VERSION ""

NS_ :

BS_:

BU_: CH DIPF DIPR ETH FC HVI HVS PARTY SDCV VEH VIRT

BO_ 1373 VCLEFT_alertLog: 8 VEH
 SG_ VCLEFT_a166_AUTO_DOWN_HELD m166 : 62|1@1+ (1,0) [0|1] ""  gtw
 SG_ VCLEFT_a150_pinchV3InUse m150 : 61|1@1+ (1,0) [0|1] ""  gtw
 SG_ VCLEFT_a151_pinchV3InUse m151 : 61|1@1+ (1,0) [0|1] ""  gtw
 SG_ VCLEFT_a166_SOFT_STOP_OVERRIDE m166 : 61|1@1+ (1,0) [0|1] ""  gtw
 SG_ VCLEFT_a166_CAL_CLEAR_ENC_LOSS m166 : 60|1@1+ (1,0) [0|1] ""  gtw
 SG_ VCLEFT_a321_railVoltage m321 : 59|5@1+ (0.5,0) [0|16] "V"  gtw
 SG_ VCLEFT_a320_railVoltage m320 : 59|5@1+ (0.5,0) [0|16] "V"  gtw
 SG_ VCLEFT_a323_railVoltage m323 : 59|5@1+ (0.5,0) [0|16] "V"  gtw
 SG_ VCLEFT_a166_SHORT_DROP_FAILED m166 : 59|1@1+ (1,0) [0|1] ""  gtw
 SG_ VCLEFT_a322_railVoltage m322 : 59|5@1+ (0.5,0) [0|16] "V"  gtw
 SG_ VCLEFT_a166_PINCH_TABLE_REJECTED m166 : 58|1@1+ (1,0) [0|1] ""  gtw
 SG_ VCLEFT_a166_INT_SWITCH_IGNORED m166 : 57|1@1+ (1,0) [0|1] ""  gtw
 SG_ VCLEFT_a042_UsageNVMMTask m42 : 56|8@1+ (1,0) [0|255] ""  gtw
 SG_ VCLEFT_a166_REAR_SWITCH_IGNORED m166 : 56|1@1+ (1,0) [0|1] ""  gtw
 SG_ VCLEFT_a041_CPULoadNVMMTask m41 : 56|8@1+ (1,0) [0|255] ""  gtw
 SG_ VCLEFT_a022_TaskInitError4 m22 : 56|8@1+ (1,0) [0|255] ""  gtw
 SG_ VCLEFT_a200_phantomTicks m200 : 53|11@1- (1,0) [-1024|1023] "ticks"  gtw
 SG_ VCLEFT_a265_seatMotorState m265 : 52|3@1+ (1,0) [0|5] ""  gtw
 SG_ VCLEFT_a237_lumbarBState m237 : 52|3@1+ (1,0) [0|5] ""  gtw
 SG_ VCLEFT_a269_seatMotorState m269 : 52|3@1+ (1,0) [0|5] ""  gtw
 SG_ VCLEFT_a270_seatMotorState m270 : 52|3@1+ (1,0) [0|5] ""  gtw
 SG_ VCLEFT_a266_seatMotorState m266 : 52|3@1+ (1,0) [0|5] ""  gtw
 SG_ VCLEFT_a263_seatMotorState m263 : 52|3@1+ (1,0) [0|5] ""  gtw
 SG_ VCLEFT_a180_latchClawStatus m180 : 52|1@1+ (1,0) [0|1] ""  gtw
 SG_ VCLEFT_a238_lumbarBState m238 : 52|3@1+ (1,0) [0|5] ""  gtw
 SG_ VCLEFT_a218_motorDutyCycle m218 : 52|10@1+ (0.1,0) [0|100] "A"  gtw
 SG_ VCLEFT_a267_seatMotorState m267 : 52|3@1+ (1,0) [0|5] ""  gtw
 SG_ VCLEFT_a181_latchClawStatus m181 : 52|1@1+ (1,0) [0|1] ""  gtw
 SG_ VCLEFT_a236_lumbarBState m236 : 52|3@1+ (1,0) [0|5] ""  gtw
 SG_ VCLEFT_a264_seatMotorState m264 : 52|3@1+ (1,0) [0|5] ""  gtw
 SG_ VCLEFT_a268_seatMotorState m268 : 52|3@1+ (1,0) [0|5] ""  gtw
 SG_ VCLEFT_a166_pinchV2PctAboveExp m166 : 51|5@1+ (1,0) [0|31] ""  gtw
 SG_ VCLEFT_a151_powerDeriv2Accum m151 : 51|10@1+ (1000,0) [0|1023000] "ticks"  gtw
 SG_ VCLEFT_a150_powerDeriv2Accum m150 : 51|10@1+ (1000,0) [0|1023000] "ticks"  gtw
 SG_ VCLEFT_a223_seatSwitchForward m223 : 50|2@1+ (1,0) [0|3] ""  gtw
 SG_ VCLEFT_a322_powerDerivAccum m322 : 50|9@1+ (100,0) [0|51100] "-"  gtw
 SG_ VCLEFT_a323_powerDeriv2Accum m323 : 50|9@1+ (2000,0) [0|1022000] "-"  gtw
 SG_ VCLEFT_a220_seatSwitchForward m220 : 50|2@1+ (1,0) [0|3] ""  gtw
 SG_ VCLEFT_a320_powerDerivAccum m320 : 50|9@1+ (100,0) [0|51100] "-"  gtw
 SG_ VCLEFT_a221_seatSwitchForward m221 : 50|2@1+ (1,0) [0|3] ""  gtw
 SG_ VCLEFT_a231_seatSwitchForward m231 : 50|2@1+ (1,0) [0|3] ""  gtw
 SG_ VCLEFT_a228_seatSwitchForward m228 : 50|2@1+ (1,0) [0|3] ""  gtw
 SG_ VCLEFT_a222_seatSwitchForward m222 : 50|2@1+ (1,0) [0|3] ""  gtw
 SG_ VCLEFT_a321_powerDeriv2Accum m321 : 50|9@1+ (2000,0) [0|1022000] "-"  gtw
 SG_ VCLEFT_a230_seatSwitchForward m230 : 50|2@1+ (1,0) [0|3] ""  gtw
 SG_ VCLEFT_a229_seatSwitchForward m229 : 50|2@1+ (1,0) [0|3] ""  gtw
 SG_ VCLEFT_a238_lumbarAState m238 : 49|3@1+ (1,0) [0|5] ""  gtw
 SG_ VCLEFT_a237_lumbarAState m237 : 49|3@1+ (1,0) [0|5] ""  gtw
 SG_ VCLEFT_a236_lumbarAState m236 : 49|3@1+ (1,0) [0|5] ""  gtw
 SG_ VCLEFT_a181_latchStatus m181 : 48|4@1+ (1,0) [0|8] ""  gtw
 SG_ VCLEFT_a223_seatSwitchBack m223 : 48|2@1+ (1,0) [0|3] ""  gtw
 SG_ VCLEFT_a237_lumbarDiagStatus m237 : 48|1@1+ (1,0) [0|1] ""  gtw
 SG_ VCLEFT_a041_CPULoad1000msTask m41 : 48|8@1+ (1,0) [0|255] ""  gtw
 SG_ VCLEFT_a180_latchStatus m180 : 48|4@1+ (1,0) [0|8] ""  gtw
 SG_ VCLEFT_a231_seatSwitchBack m231 : 48|2@1+ (1,0) [0|3] ""  gtw
 SG_ VCLEFT_a228_seatSwitchBack m228 : 48|2@1+ (1,0) [0|3] ""  gtw
 SG_ VCLEFT_a222_seatSwitchBack m222 : 48|2@1+ (1,0) [0|3] ""  gtw
 SG_ VCLEFT_a238_lumbarDiagStatus m238 : 48|1@1+ (1,0) [0|1] ""  gtw
 SG_ VCLEFT_a221_seatSwitchBack m221 : 48|2@1+ (1,0) [0|3] ""  gtw
 SG_ VCLEFT_a042_UsageUDSTask m42 : 48|8@1+ (1,0) [0|255] ""  gtw
 SG_ VCLEFT_a022_TaskInitError3 m22 : 48|8@1+ (1,0) [0|255] ""  gtw
 SG_ VCLEFT_a216_byte3 m216 : 48|8@1+ (1,0) [0|255] ""  gtw
 SG_ VCLEFT_a168_pinchV3InUse m168 : 48|1@1+ (1,0) [0|1] ""  gtw
 SG_ VCLEFT_a220_seatSwitchBack m220 : 48|2@1+ (1,0) [0|3] ""  gtw
 SG_ VCLEFT_a164_calibratedVoltage m164 : 48|6@1+ (0.25,0) [0|16] "V"  gtw
 SG_ VCLEFT_a167_pinchV3InUse m167 : 48|1@1+ (1,0) [0|1] ""  gtw
 SG_ VCLEFT_a236_lumbarDiagStatus m236 : 48|1@1+ (1,0) [0|1] ""  gtw
 SG_ VCLEFT_a229_seatSwitchBack m229 : 48|2@1+ (1,0) [0|3] ""  gtw
 SG_ VCLEFT_a230_seatSwitchBack m230 : 48|2@1+ (1,0) [0|3] ""  gtw
 SG_ VCLEFT_a003_Data m3 : 48|16@1+ (1,0) [0|65535] ""  gtw
 SG_ VCLEFT_a000_alertDataW2 m0 : 48|16@1+ (1,0) [0|65535] ""  X
 SG_ VCLEFT_a200_motorPosition m200 : 46|7@1+ (20,0) [0|2540] "ticks"  gtw
 SG_ VCLEFT_a235_seatSwitchForward m235 : 45|2@1+ (1,0) [0|3] ""  gtw
 SG_ VCLEFT_a253_seatSwitchForward m253 : 45|2@1+ (1,0) [0|3] ""  gtw
 SG_ VCLEFT_a252_seatSwitchForward m252 : 45|2@1+ (1,0) [0|3] ""  gtw
 SG_ VCLEFT_a234_seatSwitchForward m234 : 45|2@1+ (1,0) [0|3] ""  gtw
 SG_ VCLEFT_a233_seatSwitchForward m233 : 45|2@1+ (1,0) [0|3] ""  gtw
 SG_ VCLEFT_a200_encoder8vEn m200 : 45|1@1+ (1,0) [0|1] ""  gtw
 SG_ VCLEFT_a232_seatSwitchForward m232 : 45|2@1+ (1,0) [0|3] ""  gtw
 SG_ VCLEFT_a254_seatSwitchForward m254 : 45|2@1+ (1,0) [0|3] ""  gtw
 SG_ VCLEFT_a251_seatSwitchForward m251 : 45|2@1+ (1,0) [0|3] ""  gtw
 SG_ VCLEFT_a221_seatMotorState m221 : 44|3@1+ (1,0) [0|5] ""  gtw
 SG_ VCLEFT_a231_seatMotorState m231 : 44|3@1+ (1,0) [0|5] ""  gtw
 SG_ VCLEFT_a228_seatMotorState m228 : 44|3@1+ (1,0) [0|5] ""  gtw
 SG_ VCLEFT_a222_seatMotorState m222 : 44|3@1+ (1,0) [0|5] ""  gtw
 SG_ VCLEFT_a229_seatMotorState m229 : 44|3@1+ (1,0) [0|5] ""  gtw
 SG_ VCLEFT_a230_seatMotorState m230 : 44|3@1+ (1,0) [0|5] ""  gtw
 SG_ VCLEFT_a223_seatMotorState m223 : 44|3@1+ (1,0) [0|5] ""  gtw
 SG_ VCLEFT_a220_seatMotorState m220 : 44|3@1+ (1,0) [0|5] ""  gtw
 SG_ VCLEFT_a166_sealPos m166 : 43|8@1+ (1,0) [0|255] ""  gtw
 SG_ VCLEFT_a251_seatSwitchBack m251 : 43|2@1+ (1,0) [0|3] ""  gtw
 SG_ VCLEFT_a234_seatSwitchBack m234 : 43|2@1+ (1,0) [0|3] ""  gtw
 SG_ VCLEFT_a252_seatSwitchBack m252 : 43|2@1+ (1,0) [0|3] ""  gtw
 SG_ VCLEFT_a235_seatSwitchBack m235 : 43|2@1+ (1,0) [0|3] ""  gtw
 SG_ VCLEFT_a253_seatSwitchBack m253 : 43|2@1+ (1,0) [0|3] ""  gtw
 SG_ VCLEFT_a063_faulted m63 : 43|1@1+ (1,0) [0|1] ""  gtw
 SG_ VCLEFT_a232_seatSwitchBack m232 : 43|2@1+ (1,0) [0|3] ""  gtw
 SG_ VCLEFT_a254_seatSwitchBack m254 : 43|2@1+ (1,0) [0|3] ""  gtw
 SG_ VCLEFT_a233_seatSwitchBack m233 : 43|2@1+ (1,0) [0|3] ""  gtw
 SG_ VCLEFT_a218_motorCurrent m218 : 42|10@1- (0.04,0.0) [-20|20] "A"  gtw
 SG_ VCLEFT_a129_VGS_LC m129 : 42|1@1+ (1,0) [0|1] ""  gtw
 SG_ VCLEFT_a063_stuckActive m63 : 42|1@1+ (1,0) [0|1] ""  gtw
 SG_ VCLEFT_a323_peakTimeMs m323 : 41|9@1+ (2,0) [0|1022] "ms"  gtw
 SG_ VCLEFT_a150_powerDerivAccum m150 : 41|10@1+ (100,0) [0|102300] "ticks"  gtw
 SG_ VCLEFT_a129_VGS_HC m129 : 41|1@1+ (1,0) [0|1] ""  gtw
 SG_ VCLEFT_a151_powerDerivAccum m151 : 41|10@1+ (100,0) [0|102300] "ticks"  gtw
 SG_ VCLEFT_a320_peakTimeMs m320 : 41|9@1+ (2,0) [0|1022] "ms"  gtw
 SG_ VCLEFT_a321_peakTimeMs m321 : 41|9@1+ (2,0) [0|1022] "ms"  gtw
 SG_ VCLEFT_a322_peakTimeMs m322 : 41|9@1+ (2,0) [0|1022] "ms"  gtw
 SG_ VCLEFT_a063_indeterminate m63 : 41|1@1+ (1,0) [0|1] ""  gtw
 SG_ VCLEFT_a129_VGS_LB m129 : 40|1@1+ (1,0) [0|1] ""  gtw
 SG_ VCLEFT_a042_Usage1000msTask m42 : 40|8@1+ (1,0) [0|255] ""  gtw
 SG_ VCLEFT_a266_seatMotorPosReal m266 : 40|12@1- (1,0) [-2048|2047] "mm"  gtw
 SG_ VCLEFT_a254_seatMotorState m254 : 40|3@1+ (1,0) [0|5] ""  gtw
 SG_ VCLEFT_a232_seatMotorState m232 : 40|3@1+ (1,0) [0|5] ""  gtw
 SG_ VCLEFT_a265_seatMotorPosReal m265 : 40|12@1- (1,0) [-2048|2047] "mm"  gtw
 SG_ VCLEFT_a242_seatHeatTmpTarget m242 : 40|8@1- (0.5,0) [0|60] "degC"  gtw
 SG_ VCLEFT_a208_unitStatusEPBM m208 : 40|5@1+ (1,0) [0|21] ""  gtw
 SG_ VCLEFT_a234_seatMotorState m234 : 40|3@1+ (1,0) [0|5] ""  gtw
 SG_ VCLEFT_a252_seatMotorState m252 : 40|3@1+ (1,0) [0|5] ""  gtw
 SG_ VCLEFT_a207_unitStatusEPBM m207 : 40|5@1+ (1,0) [0|21] ""  gtw
 SG_ VCLEFT_a043_CallTrace1 m43 : 40|24@1+ (1,0) [0|16777215] ""  gtw
 SG_ VCLEFT_a046_CallTrace1 m46 : 40|24@1+ (1,0) [0|16777215] ""  gtw
 SG_ VCLEFT_a045_CallTrace1 m45 : 40|24@1+ (1,0) [0|16777215] ""  gtw
 SG_ VCLEFT_a181_releasePWM m181 : 40|8@1+ (1,0) [0|255] "%"  gtw
 SG_ VCLEFT_a270_seatMotorPosReal m270 : 40|12@1- (1,0) [-2048|2047] "mm"  gtw
 SG_ VCLEFT_a269_seatMotorPosReal m269 : 40|12@1- (1,0) [-2048|2047] "mm"  gtw
 SG_ VCLEFT_a264_seatMotorPosReal m264 : 40|12@1- (1,0) [-2048|2047] "mm"  gtw
 SG_ VCLEFT_a164_downMovementTimeMs m164 : 40|7@1+ (50,0) [0|6350] "ms"  gtw
 SG_ VCLEFT_a217_byte7 m217 : 40|8@1+ (1,0) [0|255] ""  gtw
 SG_ VCLEFT_a263_seatMotorPosReal m263 : 40|12@1- (1,0) [-2048|2047] "mm"  gtw
 SG_ VCLEFT_a251_seatMotorState m251 : 40|3@1+ (1,0) [0|5] ""  gtw
 SG_ VCLEFT_a063_disconnected m63 : 40|1@1+ (1,0) [0|1] ""  gtw
 SG_ VCLEFT_a206_unitStatusEPBM m206 : 40|5@1+ (1,0) [0|21] ""  gtw
 SG_ VCLEFT_a165_lowerEndStopPosition m165 : 40|8@1+ (10,0) [0|2550] "ticks"  gtw
 SG_ VCLEFT_a041_CPULoad100msTask m41 : 40|8@1+ (1,0) [0|255] ""  gtw
 SG_ VCLEFT_a044_CallTrace1 m44 : 40|24@1+ (1,0) [0|16777215] ""  gtw
 SG_ VCLEFT_a268_seatMotorPosReal m268 : 40|12@1- (1,0) [-2048|2047] "mm"  gtw
 SG_ VCLEFT_a180_releasePWM m180 : 40|8@1+ (1,0) [0|255] "%"  gtw
 SG_ VCLEFT_a216_byte2 m216 : 40|8@1+ (1,0) [0|255] ""  gtw
 SG_ VCLEFT_a233_seatMotorState m233 : 40|3@1+ (1,0) [0|5] ""  gtw
 SG_ VCLEFT_a022_TaskInitError2 m22 : 40|8@1+ (1,0) [0|255] ""  gtw
 SG_ VCLEFT_a059_current m59 : 40|12@1+ (0.05,0) [0|204.75] "A"  gtw
 SG_ VCLEFT_a267_seatMotorPosReal m267 : 40|12@1- (1,0) [-2048|2047] "mm"  gtw
 SG_ VCLEFT_a210_unitStatusEPBM m210 : 40|5@1+ (1,0) [0|21] ""  gtw
 SG_ VCLEFT_a239_seatHeatTmpTarget m239 : 40|8@1- (0.5,0) [0|60] "degC"  gtw
 SG_ VCLEFT_a253_seatMotorState m253 : 40|3@1+ (1,0) [0|5] ""  gtw
 SG_ VCLEFT_a235_seatMotorState m235 : 40|3@1+ (1,0) [0|5] ""  gtw
 SG_ VCLEFT_a209_unitStatusEPBM m209 : 40|5@1+ (1,0) [0|21] ""  gtw
 SG_ VCLEFT_a200_encoderVoltage m200 : 39|6@1+ (0.15,0) [0|9] "V"  gtw
 SG_ VCLEFT_a129_VGS_HB m129 : 39|1@1+ (1,0) [0|1] ""  gtw
 SG_ VCLEFT_a205_current m205 : 38|10@1+ (0.2,0) [0|204.6] "A"  gtw
 SG_ VCLEFT_a213_current m213 : 38|10@1+ (0.2,0) [0|204.6] "A"  gtw
 SG_ VCLEFT_a204_current m204 : 38|10@1+ (0.2,0) [0|204.6] "A"  gtw
 SG_ VCLEFT_a129_VGS_LA m129 : 38|1@1+ (1,0) [0|1] ""  gtw
 SG_ VCLEFT_a203_current m203 : 38|10@1+ (0.2,0) [0|204.6] "A"  gtw
 SG_ VCLEFT_a211_current m211 : 38|10@1+ (0.2,0) [0|204.6] "A"  gtw
 SG_ VCLEFT_a214_current m214 : 38|10@1+ (0.2,0) [0|204.6] "A"  gtw
 SG_ VCLEFT_a202_current m202 : 38|10@1+ (0.2,0) [0|204.6] "A"  gtw
 SG_ VCLEFT_a168_powerDeriv2Accum m168 : 38|10@1+ (1000,0) [0|1023000] "ticks"  gtw
 SG_ VCLEFT_a212_current m212 : 38|10@1+ (0.2,0) [0|204.6] "A"  gtw
 SG_ VCLEFT_a167_powerDeriv2Accum m167 : 38|10@1+ (1000,0) [0|1023000] "ticks"  gtw
 SG_ VCLEFT_a129_VGS_HA m129 : 37|1@1+ (1,0) [0|1] ""  gtw
 SG_ VCLEFT_a129_VCPH_OVLO_ABS m129 : 36|1@1+ (1,0) [0|1] ""  gtw
 SG_ VCLEFT_a150_pinchVoltage m150 : 35|6@1+ (0.25,0) [0|16] "V"  gtw
 SG_ VCLEFT_a129_VCPH_UVLO m129 : 35|1@1+ (1,0) [0|1] ""  gtw
 SG_ VCLEFT_a151_pinchVoltage m151 : 35|6@1+ (0.25,0) [0|16] "V"  gtw
 SG_ VCLEFT_a320_movementTimeMs m320 : 34|7@1+ (50,0) [0|6350] "ms"  gtw
 SG_ VCLEFT_a226_seatSwitchForward m226 : 34|2@1+ (1,0) [0|3] ""  gtw
 SG_ VCLEFT_a227_seatSwitchForward m227 : 34|2@1+ (1,0) [0|3] ""  gtw
 SG_ VCLEFT_a321_movementTimeMs m321 : 34|7@1+ (50,0) [0|6350] "ms"  gtw
 SG_ VCLEFT_a322_movementTimeMs m322 : 34|7@1+ (50,0) [0|6350] "ms"  gtw
 SG_ VCLEFT_a224_seatSwitchForward m224 : 34|2@1+ (1,0) [0|3] ""  gtw
 SG_ VCLEFT_a225_seatSwitchForward m225 : 34|2@1+ (1,0) [0|3] ""  gtw
 SG_ VCLEFT_a129_VCPH_UVLO2 m129 : 34|1@1+ (1,0) [0|1] ""  gtw
 SG_ VCLEFT_a323_movementTimeMs m323 : 34|7@1+ (50,0) [0|6350] "ms"  gtw
 SG_ VCLEFT_a302_CBC_UARTReset m302 : 33|1@1+ (1,0) [0|1] ""  gtw
 SG_ VCLEFT_a129_VCP_LSD_UVLO2 m129 : 33|1@1+ (1,0) [0|1] ""  gtw
 SG_ VCLEFT_a219_dropoutCount m219 : 32|12@1+ (1,0) [0|4095] ""  gtw
 SG_ VCLEFT_a231_seatMotorPosReal m231 : 32|12@1- (1,0) [-2048|2047] "mm"  gtw
 SG_ VCLEFT_a228_seatMotorPosReal m228 : 32|12@1- (1,0) [-2048|2047] "mm"  gtw
 SG_ VCLEFT_a022_TaskInitError1 m22 : 32|8@1+ (1,0) [0|255] ""  gtw
 SG_ VCLEFT_a210_unitStatusEPB m210 : 32|5@1+ (1,0) [0|21] ""  gtw
 SG_ VCLEFT_a224_seatSwitchBack m224 : 32|2@1+ (1,0) [0|3] ""  gtw
 SG_ VCLEFT_a209_unitStatusEPB m209 : 32|5@1+ (1,0) [0|21] ""  gtw
 SG_ VCLEFT_a167_pinchVoltage m167 : 32|6@1+ (0.25,0) [0|16] "V"  gtw
 SG_ VCLEFT_a180_extHandlePulled m180 : 32|1@1+ (1,0) [0|1] ""  gtw
 SG_ VCLEFT_a164_upMovementTimeMs m164 : 32|7@1+ (50,0) [0|6350] "ms"  gtw
 SG_ VCLEFT_a216_byte1 m216 : 32|8@1+ (1,0) [0|255] ""  gtw
 SG_ VCLEFT_a151_windowPinchReason m151 : 32|3@1+ (1,0) [0|4] ""  gtw
 SG_ VCLEFT_a302_CBC_MIA m302 : 32|1@1+ (1,0) [0|1] ""  gtw
 SG_ VCLEFT_a206_unitStatusEPB m206 : 32|5@1+ (1,0) [0|21] ""  gtw
 SG_ VCLEFT_a212_desyncCount m212 : 32|6@1+ (1,0) [0|63] ""  gtw
 SG_ VCLEFT_a236_lumbarBPressureHpa m236 : 32|16@1+ (1,0) [0|65535] ""  gtw
 SG_ VCLEFT_a222_seatMotorPosReal m222 : 32|12@1- (1,0) [-2048|2047] "mm"  gtw
 SG_ VCLEFT_a208_unitStatusEPB m208 : 32|5@1+ (1,0) [0|21] ""  gtw
 SG_ VCLEFT_a276_mirrorTiltYPosition m276 : 32|8@1+ (0.02,0) [0|5] "V"  gtw
 SG_ VCLEFT_a041_CPULoad10msTask m41 : 32|8@1+ (1,0) [0|255] ""  gtw
 SG_ VCLEFT_a181_extHandlePulled m181 : 32|1@1+ (1,0) [0|1] ""  gtw
 SG_ VCLEFT_a221_seatMotorPosReal m221 : 32|12@1- (1,0) [-2048|2047] "mm"  gtw
 SG_ VCLEFT_a129_AVDD_UVLO m129 : 32|1@1+ (1,0) [0|1] ""  gtw
 SG_ VCLEFT_a214_desyncCount m214 : 32|6@1+ (1,0) [0|63] ""  gtw
 SG_ VCLEFT_a227_seatSwitchBack m227 : 32|2@1+ (1,0) [0|3] ""  gtw
 SG_ VCLEFT_a213_desyncCount m213 : 32|6@1+ (1,0) [0|63] ""  gtw
 SG_ VCLEFT_a260_temperature m260 : 32|8@1+ (0.5,-40) [-40|80] "degC"  gtw
 SG_ VCLEFT_a000_alertDataW1 m0 : 32|16@1+ (1,0) [0|65535] ""  X
 SG_ VCLEFT_a217_byte6 m217 : 32|8@1+ (1,0) [0|255] ""  gtw
 SG_ VCLEFT_a165_sealZoneStartPos m165 : 32|8@1+ (1,0) [0|255] ""  gtw
 SG_ VCLEFT_a287_encoderVoltage m287 : 32|6@1+ (0.15,0) [0|9] "V"  gtw
 SG_ VCLEFT_a220_seatMotorPosReal m220 : 32|12@1- (1,0) [-2048|2047] "mm"  gtw
 SG_ VCLEFT_a003_LineNumber m3 : 32|16@1+ (1,0) [0|65535] ""  gtw
 SG_ VCLEFT_a244_seatHeatTmpTarget m244 : 32|8@1- (0.5,0) [0|60] "degC"  gtw
 SG_ VCLEFT_a063_ADCVoltage m63 : 32|8@1+ (0.025,0) [0|6.375] "V"  gtw
 SG_ VCLEFT_a166_powerSealPos m166 : 32|11@1+ (1,0) [0|2047] ""  gtw
 SG_ VCLEFT_a168_pinchVoltage m168 : 32|6@1+ (0.25,0) [0|16] "V"  gtw
 SG_ VCLEFT_a042_Usage100msTask m42 : 32|8@1+ (1,0) [0|255] ""  gtw
 SG_ VCLEFT_a218_voltage m218 : 32|10@1+ (0.02,0) [0|19] "V"  gtw
 SG_ VCLEFT_a241_seatHeatTmpTarget m241 : 32|8@1- (0.5,0) [0|60] "degC"  gtw
 SG_ VCLEFT_a203_desyncCount m203 : 32|6@1+ (1,0) [0|63] ""  gtw
 SG_ VCLEFT_a226_seatSwitchBack m226 : 32|2@1+ (1,0) [0|3] ""  gtw
 SG_ VCLEFT_a211_desyncCount m211 : 32|6@1+ (1,0) [0|63] ""  gtw
 SG_ VCLEFT_a230_seatMotorPosReal m230 : 32|12@1- (1,0) [-2048|2047] "mm"  gtw
 SG_ VCLEFT_a229_seatMotorPosReal m229 : 32|12@1- (1,0) [-2048|2047] "mm"  gtw
 SG_ VCLEFT_a225_seatSwitchBack m225 : 32|2@1+ (1,0) [0|3] ""  gtw
 SG_ VCLEFT_a286_encoderVoltage m286 : 32|6@1+ (0.15,0) [0|9] "V"  gtw
 SG_ VCLEFT_a259_temperature m259 : 32|8@1+ (0.5,-40) [-40|80] "degC"  gtw
 SG_ VCLEFT_a238_lumbarBPressureHpa m238 : 32|16@1+ (1,0) [0|65535] ""  gtw
 SG_ VCLEFT_a205_desyncCount m205 : 32|6@1+ (1,0) [0|63] ""  gtw
 SG_ VCLEFT_a237_lumbarBPressureHpa m237 : 32|16@1+ (1,0) [0|65535] ""  gtw
 SG_ VCLEFT_a202_desyncCount m202 : 32|6@1+ (1,0) [0|63] ""  gtw
 SG_ VCLEFT_a223_seatMotorPosReal m223 : 32|12@1- (1,0) [-2048|2047] "mm"  gtw
 SG_ VCLEFT_a207_unitStatusEPB m207 : 32|5@1+ (1,0) [0|21] ""  gtw
 SG_ VCLEFT_a150_windowPinchReason m150 : 32|3@1+ (1,0) [0|4] ""  gtw
 SG_ VCLEFT_a204_desyncCount m204 : 32|6@1+ (1,0) [0|63] ""  gtw
 SG_ VCLEFT_a129_VREG_UV m129 : 31|1@1+ (1,0) [0|1] ""  gtw
 SG_ VCLEFT_a302_overCurrentLatch m302 : 31|1@1+ (1,0) [0|1] ""  gtw
 SG_ VCLEFT_a166_STATE_TIMEOUT m166 : 31|1@1+ (1,0) [0|1] ""  gtw
 SG_ VCLEFT_a302_DRV_MIA m302 : 30|1@1+ (1,0) [0|1] ""  gtw
 SG_ VCLEFT_a166_PINCH_DEBUG m166 : 30|1@1+ (1,0) [0|1] ""  gtw
 SG_ VCLEFT_a129_OTSD m129 : 30|1@1+ (1,0) [0|1] ""  gtw
 SG_ VCLEFT_a130_OTW m130 : 29|1@1+ (1,0) [0|1] ""  gtw
 SG_ VCLEFT_a226_seatMotorState m226 : 29|3@1+ (1,0) [0|5] ""  gtw
 SG_ VCLEFT_a129_WD_FAULT m129 : 29|1@1+ (1,0) [0|1] ""  gtw
 SG_ VCLEFT_a227_seatMotorState m227 : 29|3@1+ (1,0) [0|5] ""  gtw
 SG_ VCLEFT_a224_seatMotorState m224 : 29|3@1+ (1,0) [0|5] ""  gtw
 SG_ VCLEFT_a225_seatMotorState m225 : 29|3@1+ (1,0) [0|5] ""  gtw
 SG_ VCLEFT_a302_motorDisconnect m302 : 29|1@1+ (1,0) [0|1] ""  gtw
 SG_ VCLEFT_a166_PINCH_V1 m166 : 29|1@1+ (1,0) [0|1] ""  gtw
 SG_ VCLEFT_a267_seatMotorDCurrent m267 : 28|12@1- (0.01,0) [-20.48|20.47] "A"  gtw
 SG_ VCLEFT_a204_wenchPendingAllowed m204 : 28|1@1+ (1,0) [0|1] ""  gtw
 SG_ VCLEFT_a130_TEMP_FLAG3 m130 : 28|1@1+ (1,0) [0|1] ""  gtw
 SG_ VCLEFT_a212_wenchPendingAllowed m212 : 28|1@1+ (1,0) [0|1] ""  gtw
 SG_ VCLEFT_a129_PVDD_UVLO2 m129 : 28|1@1+ (1,0) [0|1] ""  gtw
 SG_ VCLEFT_a268_seatMotorDCurrent m268 : 28|12@1- (0.01,0) [-20.48|20.47] "A"  gtw
 SG_ VCLEFT_a059_resistanceEstimate m59 : 28|12@1+ (0.00244,0) [0|9.9918] "Ohms"  gtw
 SG_ VCLEFT_a292_railV m292 : 28|12@1- (0.01,0) [-20.48|20.47] "V"  gtw
 SG_ VCLEFT_a240_seatHeatTmp m240 : 28|12@1- (0.05,0) [-40|80] "degC"  gtw
 SG_ VCLEFT_a266_seatMotorDCurrent m266 : 28|12@1- (0.01,0) [-20.48|20.47] "A"  gtw
 SG_ VCLEFT_a205_wenchPendingAllowed m205 : 28|1@1+ (1,0) [0|1] ""  gtw
 SG_ VCLEFT_a208_wenchPendingAllowed m208 : 28|1@1+ (1,0) [0|1] ""  gtw
 SG_ VCLEFT_a239_seatHeatTmp m239 : 28|12@1- (0.05,0) [-40|80] "degC"  gtw
 SG_ VCLEFT_a211_wenchPendingAllowed m211 : 28|1@1+ (1,0) [0|1] ""  gtw
 SG_ VCLEFT_a232_seatMotorPosReal m232 : 28|12@1- (1,0) [-2048|2047] "mm"  gtw
 SG_ VCLEFT_a254_seatMotorPosReal m254 : 28|12@1- (1,0) [-2048|2047] "mm"  gtw
 SG_ VCLEFT_a251_seatMotorPosReal m251 : 28|12@1- (1,0) [-2048|2047] "mm"  gtw
 SG_ VCLEFT_a202_wenchPendingAllowed m202 : 28|1@1+ (1,0) [0|1] ""  gtw
 SG_ VCLEFT_a209_wenchPendingAllowed m209 : 28|1@1+ (1,0) [0|1] ""  gtw
 SG_ VCLEFT_a210_wenchPendingAllowed m210 : 28|1@1+ (1,0) [0|1] ""  gtw
 SG_ VCLEFT_a234_seatMotorPosReal m234 : 28|12@1- (1,0) [-2048|2047] "mm"  gtw
 SG_ VCLEFT_a252_seatMotorPosReal m252 : 28|12@1- (1,0) [-2048|2047] "mm"  gtw
 SG_ VCLEFT_a295_railV m295 : 28|12@1- (0.01,0) [-20.48|20.47] "V"  gtw
 SG_ VCLEFT_a242_seatHeatTmp m242 : 28|12@1- (0.05,0) [-40|80] "degC"  gtw
 SG_ VCLEFT_a291_railVoltage m291 : 28|12@1+ (0.01,0) [0|40.95] "V"  gtw
 SG_ VCLEFT_a203_wenchPendingAllowed m203 : 28|1@1+ (1,0) [0|1] ""  gtw
 SG_ VCLEFT_a206_wenchPendingAllowed m206 : 28|1@1+ (1,0) [0|1] ""  gtw
 SG_ VCLEFT_a233_seatMotorPosReal m233 : 28|12@1- (1,0) [-2048|2047] "mm"  gtw
 SG_ VCLEFT_a265_seatMotorDCurrent m265 : 28|12@1- (0.01,0) [-20.48|20.47] "A"  gtw
 SG_ VCLEFT_a166_ENCODER_STALL m166 : 28|1@1+ (1,0) [0|1] ""  gtw
 SG_ VCLEFT_a302_fetOvertempShutdown m302 : 28|1@1+ (1,0) [0|1] ""  gtw
 SG_ VCLEFT_a294_railV m294 : 28|12@1- (0.01,0) [-20.48|20.47] "V"  gtw
 SG_ VCLEFT_a290_railVoltage m290 : 28|12@1- (0.01,0) [-20.48|20.47] "V"  gtw
 SG_ VCLEFT_a243_seatHeatTmp m243 : 28|12@1- (0.05,0) [-40|80] "degC"  gtw
 SG_ VCLEFT_a214_wenchPendingAllowed m214 : 28|1@1+ (1,0) [0|1] ""  gtw
 SG_ VCLEFT_a235_seatMotorPosReal m235 : 28|12@1- (1,0) [-2048|2047] "mm"  gtw
 SG_ VCLEFT_a253_seatMotorPosReal m253 : 28|12@1- (1,0) [-2048|2047] "mm"  gtw
 SG_ VCLEFT_a263_seatMotorDCurrent m263 : 28|12@1- (0.01,0) [-20.48|20.47] "A"  gtw
 SG_ VCLEFT_a264_seatMotorDCurrent m264 : 28|12@1- (0.01,0) [-20.48|20.47] "A"  gtw
 SG_ VCLEFT_a207_wenchPendingAllowed m207 : 28|1@1+ (1,0) [0|1] ""  gtw
 SG_ VCLEFT_a269_seatMotorDCurrent m269 : 28|12@1- (0.01,0) [-20.48|20.47] "A"  gtw
 SG_ VCLEFT_a293_railV m293 : 28|12@1- (0.01,0) [-20.48|20.47] "V"  gtw
 SG_ VCLEFT_a270_seatMotorDCurrent m270 : 28|12@1- (0.01,0) [-20.48|20.47] "A"  gtw
 SG_ VCLEFT_a213_wenchPendingAllowed m213 : 28|1@1+ (1,0) [0|1] ""  gtw
 SG_ VCLEFT_a212_parkPendingAllowed m212 : 27|1@1+ (1,0) [0|1] ""  gtw
 SG_ VCLEFT_a130_TEMP_FLAG2 m130 : 27|1@1+ (1,0) [0|1] ""  gtw
 SG_ VCLEFT_a202_parkPendingAllowed m202 : 27|1@1+ (1,0) [0|1] ""  gtw
 SG_ VCLEFT_a207_parkPendingAllowed m207 : 27|1@1+ (1,0) [0|1] ""  gtw
 SG_ VCLEFT_a116_VEH_logging1Hz m116 : 27|1@1+ (1,0) [0|1] ""  gtw
 SG_ VCLEFT_a211_parkPendingAllowed m211 : 27|1@1+ (1,0) [0|1] ""  gtw
 SG_ VCLEFT_a208_parkPendingAllowed m208 : 27|1@1+ (1,0) [0|1] ""  gtw
 SG_ VCLEFT_a166_UNDERCURRENT m166 : 27|1@1+ (1,0) [0|1] ""  gtw
 SG_ VCLEFT_a214_parkPendingAllowed m214 : 27|1@1+ (1,0) [0|1] ""  gtw
 SG_ VCLEFT_a203_parkPendingAllowed m203 : 27|1@1+ (1,0) [0|1] ""  gtw
 SG_ VCLEFT_a129_SNS_A_OCP m129 : 27|1@1+ (1,0) [0|1] ""  gtw
 SG_ VCLEFT_a204_parkPendingAllowed m204 : 27|1@1+ (1,0) [0|1] ""  gtw
 SG_ VCLEFT_a021_Task1000msMissed m21 : 27|1@1+ (1,0) [0|1] ""  gtw
 SG_ VCLEFT_a210_parkPendingAllowed m210 : 27|1@1+ (1,0) [0|1] ""  gtw
 SG_ VCLEFT_a209_parkPendingAllowed m209 : 27|1@1+ (1,0) [0|1] ""  gtw
 SG_ VCLEFT_a213_parkPendingAllowed m213 : 27|1@1+ (1,0) [0|1] ""  gtw
 SG_ VCLEFT_a302_TMS320OverTempShutDw m302 : 27|1@1+ (1,0) [0|1] ""  gtw
 SG_ VCLEFT_a205_parkPendingAllowed m205 : 27|1@1+ (1,0) [0|1] ""  gtw
 SG_ VCLEFT_a206_parkPendingAllowed m206 : 27|1@1+ (1,0) [0|1] ""  gtw
 SG_ VCLEFT_a205_releaseAllowed m205 : 26|1@1+ (1,0) [0|1] ""  gtw
 SG_ VCLEFT_a202_releaseAllowed m202 : 26|1@1+ (1,0) [0|1] ""  gtw
 SG_ VCLEFT_a209_releaseAllowed m209 : 26|1@1+ (1,0) [0|1] ""  gtw
 SG_ VCLEFT_a210_releaseAllowed m210 : 26|1@1+ (1,0) [0|1] ""  gtw
 SG_ VCLEFT_a206_releaseAllowed m206 : 26|1@1+ (1,0) [0|1] ""  gtw
 SG_ VCLEFT_a203_releaseAllowed m203 : 26|1@1+ (1,0) [0|1] ""  gtw
 SG_ VCLEFT_a320_positionDelta m320 : 26|8@1+ (2,0) [0|510] "ticks"  gtw
 SG_ VCLEFT_a214_releaseAllowed m214 : 26|1@1+ (1,0) [0|1] ""  gtw
 SG_ VCLEFT_a132_RPMTarget m132 : 26|10@1+ (10,0) [0|10000] "RPM"  gtw
 SG_ VCLEFT_a213_releaseAllowed m213 : 26|1@1+ (1,0) [0|1] ""  gtw
 SG_ VCLEFT_a321_positionDelta m321 : 26|8@1+ (2,0) [0|510] "ticks"  gtw
 SG_ VCLEFT_a116_VEH_switchStatus m116 : 26|1@1+ (1,0) [0|1] ""  gtw
 SG_ VCLEFT_a207_releaseAllowed m207 : 26|1@1+ (1,0) [0|1] ""  gtw
 SG_ VCLEFT_a130_TEMP_FLAG1 m130 : 26|1@1+ (1,0) [0|1] ""  gtw
 SG_ VCLEFT_a204_releaseAllowed m204 : 26|1@1+ (1,0) [0|1] ""  gtw
 SG_ VCLEFT_a302_startupFailed m302 : 26|1@1+ (1,0) [0|1] ""  gtw
 SG_ VCLEFT_a133_RPMTarget m133 : 26|10@1+ (10,0) [0|10000] "RPM"  gtw
 SG_ VCLEFT_a322_positionDelta m322 : 26|8@1+ (2,0) [0|510] "ticks"  gtw
 SG_ VCLEFT_a021_Task1000msStarved m21 : 26|1@1+ (1,0) [0|1] ""  gtw
 SG_ VCLEFT_a129_SNS_B_OCP m129 : 26|1@1+ (1,0) [0|1] ""  gtw
 SG_ VCLEFT_a166_POWER_AT_SEAL m166 : 26|1@1+ (1,0) [0|1] ""  gtw
 SG_ VCLEFT_a212_releaseAllowed m212 : 26|1@1+ (1,0) [0|1] ""  gtw
 SG_ VCLEFT_a284_RPMTarget m284 : 26|10@1+ (10,0) [0|10000] "RPM"  gtw
 SG_ VCLEFT_a211_releaseAllowed m211 : 26|1@1+ (1,0) [0|1] ""  gtw
 SG_ VCLEFT_a208_releaseAllowed m208 : 26|1@1+ (1,0) [0|1] ""  gtw
 SG_ VCLEFT_a323_positionDelta m323 : 26|8@1+ (2,0) [0|510] "ticks"  gtw
 SG_ VCLEFT_a116_VEH_restraintStatus m116 : 25|1@1+ (1,0) [0|1] ""  gtw
 SG_ VCLEFT_a203_dynApplyAllowed m203 : 25|1@1+ (1,0) [0|1] ""  gtw
 SG_ VCLEFT_a210_dynApplyAllowed m210 : 25|1@1+ (1,0) [0|1] ""  gtw
 SG_ VCLEFT_a209_dynApplyAllowed m209 : 25|1@1+ (1,0) [0|1] ""  gtw
 SG_ VCLEFT_a202_dynApplyAllowed m202 : 25|1@1+ (1,0) [0|1] ""  gtw
 SG_ VCLEFT_a302_overspeedFault m302 : 25|1@1+ (1,0) [0|1] ""  gtw
 SG_ VCLEFT_a208_dynApplyAllowed m208 : 25|1@1+ (1,0) [0|1] ""  gtw
 SG_ VCLEFT_a211_dynApplyAllowed m211 : 25|1@1+ (1,0) [0|1] ""  gtw
 SG_ VCLEFT_a205_dynApplyAllowed m205 : 25|1@1+ (1,0) [0|1] ""  gtw
 SG_ VCLEFT_a286_voltage m286 : 25|7@1+ (0.15,0) [0|19] "V"  gtw
 SG_ VCLEFT_a212_dynApplyAllowed m212 : 25|1@1+ (1,0) [0|1] ""  gtw
 SG_ VCLEFT_a117_VEH_intrusionSensorS m117 : 25|1@1+ (1,0) [0|1] ""  gtw
 SG_ VCLEFT_a204_dynApplyAllowed m204 : 25|1@1+ (1,0) [0|1] ""  gtw
 SG_ VCLEFT_a130_VCPH_UVFL m130 : 25|1@1+ (1,0) [0|1] ""  gtw
 SG_ VCLEFT_a213_dynApplyAllowed m213 : 25|1@1+ (1,0) [0|1] ""  gtw
 SG_ VCLEFT_a287_voltage m287 : 25|7@1+ (0.15,0) [0|19] "V"  gtw
 SG_ VCLEFT_a207_dynApplyAllowed m207 : 25|1@1+ (1,0) [0|1] ""  gtw
 SG_ VCLEFT_a021_Task1000msLate m21 : 25|1@1+ (1,0) [0|1] ""  gtw
 SG_ VCLEFT_a166_JUST_CALIBRATED m166 : 25|1@1+ (1,0) [0|1] ""  gtw
 SG_ VCLEFT_a214_dynApplyAllowed m214 : 25|1@1+ (1,0) [0|1] ""  gtw
 SG_ VCLEFT_a206_dynApplyAllowed m206 : 25|1@1+ (1,0) [0|1] ""  gtw
 SG_ VCLEFT_a129_SNS_C_OCP m129 : 25|1@1+ (1,0) [0|1] ""  gtw
 SG_ VCLEFT_a276_mirrorTiltXPosition m276 : 24|8@1+ (0.02,0) [0|5] "V"  gtw
 SG_ VCLEFT_a260_voltage m260 : 24|7@1+ (0.15,0) [0|19] "V"  gtw
 SG_ VCLEFT_a042_Usage10msTask m42 : 24|8@1+ (1,0) [0|255] ""  gtw
 SG_ VCLEFT_a181_extHandlePWM m181 : 24|8@1+ (1,0) [0|255] "%"  gtw
 SG_ VCLEFT_a212_parkingAllowed m212 : 24|1@1+ (1,0) [0|1] ""  gtw
 SG_ VCLEFT_a150_movementTimeMs m150 : 24|7@1+ (50,0) [0|6350] "ms"  gtw
 SG_ VCLEFT_a282_temperature m282 : 24|8@1+ (0.5,-40) [-40|80] "degC"  gtw
 SG_ VCLEFT_a206_parkingAllowed m206 : 24|1@1+ (1,0) [0|1] ""  gtw
 SG_ VCLEFT_a205_parkingAllowed m205 : 24|1@1+ (1,0) [0|1] ""  gtw
 SG_ VCLEFT_a168_movementTimeMs m168 : 24|7@1+ (50,0) [0|6350] "ms"  gtw
 SG_ VCLEFT_a216_byte0 m216 : 24|8@1+ (1,0) [0|255] ""  gtw
 SG_ VCLEFT_a063_switchType m63 : 24|8@1+ (1,0) [0|255] ""  gtw
 SG_ VCLEFT_a022_TaskInitError0 m22 : 24|8@1+ (1,0) [0|255] ""  gtw
 SG_ VCLEFT_a187_temperature m187 : 24|8@1+ (0.5,-40) [-40|80] "degC"  gtw
 SG_ VCLEFT_a273_temperature m273 : 24|8@1+ (0.5,-40) [-40|80] "degC"  gtw
 SG_ VCLEFT_a117_VEH_switchStatus m117 : 24|1@1+ (1,0) [0|1] ""  gtw
 SG_ VCLEFT_a116_VEH_seatHeatStatus m116 : 24|1@1+ (1,0) [0|1] ""  gtw
 SG_ VCLEFT_a274_temperature m274 : 24|8@1+ (0.5,-40) [-40|80] "degC"  gtw
 SG_ VCLEFT_a302_currentUnbalance m302 : 24|1@1+ (1,0) [0|1] ""  gtw
 SG_ VCLEFT_a118_VEH_systemStatus m118 : 24|1@1+ (1,0) [0|1] ""  gtw
 SG_ VCLEFT_a283_temperature m283 : 24|8@1+ (0.5,-40) [-40|80] "degC"  gtw
 SG_ VCLEFT_a180_extHandlePWM m180 : 24|8@1+ (1,0) [0|255] "%"  gtw
 SG_ VCLEFT_a286_windowDirectionUp m286 : 24|1@1+ (1,0) [0|1] ""  gtw
 SG_ VCLEFT_a213_parkingAllowed m213 : 24|1@1+ (1,0) [0|1] ""  gtw
 SG_ VCLEFT_a167_movementTimeMs m167 : 24|7@1+ (50,0) [0|6350] "ms"  gtw
 SG_ VCLEFT_a210_parkingAllowed m210 : 24|1@1+ (1,0) [0|1] ""  gtw
 SG_ VCLEFT_a186_temperature m186 : 24|8@1+ (0.5,-40) [-40|80] "degC"  gtw
 SG_ VCLEFT_a129_VDS_LC m129 : 24|1@1+ (1,0) [0|1] ""  gtw
 SG_ VCLEFT_a209_parkingAllowed m209 : 24|1@1+ (1,0) [0|1] ""  gtw
 SG_ VCLEFT_a310_foldingDirection m310 : 24|1@1+ (1,0) [0|1] ""  gtw
 SG_ VCLEFT_a183_stopReason m183 : 24|4@1+ (1,0) [0|8] ""  gtw
 SG_ VCLEFT_a204_parkingAllowed m204 : 24|1@1+ (1,0) [0|1] ""  gtw
 SG_ VCLEFT_a203_parkingAllowed m203 : 24|1@1+ (1,0) [0|1] ""  gtw
 SG_ VCLEFT_a169_currentPeakPosition m169 : 24|8@1+ (10,0) [0|2550] "ticks"  gtw
 SG_ VCLEFT_a287_windowDirectionUp m287 : 24|1@1+ (1,0) [0|1] ""  gtw
 SG_ VCLEFT_a170_currentPeakPosition m170 : 24|8@1+ (10,0) [0|2550] "ticks"  gtw
 SG_ VCLEFT_a259_voltage m259 : 24|7@1+ (0.15,0) [0|19] "V"  gtw
 SG_ VCLEFT_a189_temperature m189 : 24|8@1+ (0.5,-40) [-40|80] "degC"  gtw
 SG_ VCLEFT_a021_Task100msMissed m21 : 24|1@1+ (1,0) [0|1] ""  gtw
 SG_ VCLEFT_a113_VEH_powertrainContro m113 : 24|1@1+ (1,0) [0|1] ""  gtw
 SG_ VCLEFT_a041_CPULoad1msTask m41 : 24|8@1+ (1,0) [0|255] ""  gtw
 SG_ VCLEFT_a164_stopReason m164 : 24|3@1+ (1,0) [0|6] ""  gtw
 SG_ VCLEFT_a214_parkingAllowed m214 : 24|1@1+ (1,0) [0|1] ""  gtw
 SG_ VCLEFT_a211_parkingAllowed m211 : 24|1@1+ (1,0) [0|1] ""  gtw
 SG_ VCLEFT_a208_parkingAllowed m208 : 24|1@1+ (1,0) [0|1] ""  gtw
 SG_ VCLEFT_a165_maxClosingPower m165 : 24|8@1+ (1,0) [0|255] "W"  gtw
 SG_ VCLEFT_a166_CAL_CLEAR_PARTIAL m166 : 24|1@1+ (1,0) [0|1] ""  gtw
 SG_ VCLEFT_a207_parkingAllowed m207 : 24|1@1+ (1,0) [0|1] ""  gtw
 SG_ VCLEFT_a151_movementTimeMs m151 : 24|7@1+ (50,0) [0|6350] "ms"  gtw
 SG_ VCLEFT_a188_temperature m188 : 24|8@1+ (0.5,-40) [-40|80] "degC"  gtw
 SG_ VCLEFT_a202_parkingAllowed m202 : 24|1@1+ (1,0) [0|1] ""  gtw
 SG_ VCLEFT_a130_VDS_STATUS m130 : 24|1@1+ (1,0) [0|1] ""  gtw
 SG_ VCLEFT_a120_VEH_speed m120 : 24|1@1+ (1,0) [0|1] ""  gtw
 SG_ VCLEFT_a201_motorChannels m201 : 24|16@1+ (1,0) [0|65535] ""  gtw
 SG_ VCLEFT_a217_byte5 m217 : 24|8@1+ (1,0) [0|255] ""  gtw
 SG_ VCLEFT_a200_motorChannels m200 : 23|16@1+ (1,0) [0|65535] ""  gtw
 SG_ VCLEFT_a302_motorLostPhase m302 : 23|1@1+ (1,0) [0|1] ""  gtw
 SG_ VCLEFT_a117_VEH_doorStatus m117 : 23|1@1+ (1,0) [0|1] ""  gtw
 SG_ VCLEFT_a204_winchReleaseAllowed m204 : 23|1@1+ (1,0) [0|1] ""  gtw
 SG_ VCLEFT_a202_winchReleaseAllowed m202 : 23|1@1+ (1,0) [0|1] ""  gtw
 SG_ VCLEFT_a120_PARTY_speed m120 : 23|1@1+ (1,0) [0|1] ""  gtw
 SG_ VCLEFT_a205_winchReleaseAllowed m205 : 23|1@1+ (1,0) [0|1] ""  gtw
 SG_ VCLEFT_a211_winchReleaseAllowed m211 : 23|1@1+ (1,0) [0|1] ""  gtw
 SG_ VCLEFT_a208_winchReleaseAllowed m208 : 23|1@1+ (1,0) [0|1] ""  gtw
 SG_ VCLEFT_a116_VEH_doorStatus m116 : 23|1@1+ (1,0) [0|1] ""  gtw
 SG_ VCLEFT_a203_winchReleaseAllowed m203 : 23|1@1+ (1,0) [0|1] ""  gtw
 SG_ VCLEFT_a118_VEH_12VBattStatus m118 : 23|1@1+ (1,0) [0|1] ""  gtw
 SG_ VCLEFT_a206_winchReleaseAllowed m206 : 23|1@1+ (1,0) [0|1] ""  gtw
 SG_ VCLEFT_a210_winchReleaseAllowed m210 : 23|1@1+ (1,0) [0|1] ""  gtw
 SG_ VCLEFT_a209_winchReleaseAllowed m209 : 23|1@1+ (1,0) [0|1] ""  gtw
 SG_ VCLEFT_a129_VDS_HC m129 : 23|1@1+ (1,0) [0|1] ""  gtw
 SG_ VCLEFT_a207_winchReleaseAllowed m207 : 23|1@1+ (1,0) [0|1] ""  gtw
 SG_ VCLEFT_a166_CAL_CLEAR_POS m166 : 23|1@1+ (1,0) [0|1] ""  gtw
 SG_ VCLEFT_a213_winchReleaseAllowed m213 : 23|1@1+ (1,0) [0|1] ""  gtw
 SG_ VCLEFT_a021_Task100msStarved m21 : 23|1@1+ (1,0) [0|1] ""  gtw
 SG_ VCLEFT_a214_winchReleaseAllowed m214 : 23|1@1+ (1,0) [0|1] ""  gtw
 SG_ VCLEFT_a113_VEH_chassisControl m113 : 23|1@1+ (1,0) [0|1] ""  gtw
 SG_ VCLEFT_a130_PVDD_OVFL m130 : 23|1@1+ (1,0) [0|1] ""  gtw
 SG_ VCLEFT_a212_winchReleaseAllowed m212 : 23|1@1+ (1,0) [0|1] ""  gtw
 SG_ VCLEFT_a208_winchAllowed m208 : 22|1@1+ (1,0) [0|1] ""  gtw
 SG_ VCLEFT_a211_winchAllowed m211 : 22|1@1+ (1,0) [0|1] ""  gtw
 SG_ VCLEFT_a116_VEH_thsStatus m116 : 22|1@1+ (1,0) [0|1] ""  gtw
 SG_ VCLEFT_a205_winchAllowed m205 : 22|1@1+ (1,0) [0|1] ""  gtw
 SG_ VCLEFT_a206_winchAllowed m206 : 22|1@1+ (1,0) [0|1] ""  gtw
 SG_ VCLEFT_a129_VDS_LB m129 : 22|1@1+ (1,0) [0|1] ""  gtw
 SG_ VCLEFT_a203_winchAllowed m203 : 22|1@1+ (1,0) [0|1] ""  gtw
 SG_ VCLEFT_a209_winchAllowed m209 : 22|1@1+ (1,0) [0|1] ""  gtw
 SG_ VCLEFT_a210_winchAllowed m210 : 22|1@1+ (1,0) [0|1] ""  gtw
 SG_ VCLEFT_a118_VEH_vehicleStatus m118 : 22|1@1+ (1,0) [0|1] ""  gtw
 SG_ VCLEFT_a213_winchAllowed m213 : 22|1@1+ (1,0) [0|1] ""  gtw
 SG_ VCLEFT_a120_VEH_status m120 : 22|1@1+ (1,0) [0|1] ""  gtw
 SG_ VCLEFT_a207_winchAllowed m207 : 22|1@1+ (1,0) [0|1] ""  gtw
 SG_ VCLEFT_a166_CAL_CLEAR_SWITCH m166 : 22|1@1+ (1,0) [0|1] ""  gtw
 SG_ VCLEFT_a117_VEH_seatStatus m117 : 22|1@1+ (1,0) [0|1] ""  gtw
 SG_ VCLEFT_a214_winchAllowed m214 : 22|1@1+ (1,0) [0|1] ""  gtw
 SG_ VCLEFT_a276_mirrorDip m276 : 22|1@1+ (1,0) [0|1] ""  gtw
 SG_ VCLEFT_a130_PVDD_UVFL m130 : 22|1@1+ (1,0) [0|1] ""  gtw
 SG_ VCLEFT_a212_winchAllowed m212 : 22|1@1+ (1,0) [0|1] ""  gtw
 SG_ VCLEFT_a113_VEH_ventCntlReq m113 : 22|1@1+ (1,0) [0|1] ""  gtw
 SG_ VCLEFT_a204_winchAllowed m204 : 22|1@1+ (1,0) [0|1] ""  gtw
 SG_ VCLEFT_a021_Task100msLate m21 : 22|1@1+ (1,0) [0|1] ""  gtw
 SG_ VCLEFT_a302_overloadFault m302 : 22|1@1+ (1,0) [0|1] ""  gtw
 SG_ VCLEFT_a202_winchAllowed m202 : 22|1@1+ (1,0) [0|1] ""  gtw
 SG_ VCLEFT_a210_serviceAllowed m210 : 21|1@1+ (1,0) [0|1] ""  gtw
 SG_ VCLEFT_a118_VEH_LVPowerState m118 : 21|1@1+ (1,0) [0|1] ""  gtw
 SG_ VCLEFT_a120_PARTY_locStatus m120 : 21|1@1+ (1,0) [0|1] ""  gtw
 SG_ VCLEFT_a209_serviceAllowed m209 : 21|1@1+ (1,0) [0|1] ""  gtw
 SG_ VCLEFT_a203_serviceAllowed m203 : 21|1@1+ (1,0) [0|1] ""  gtw
 SG_ VCLEFT_a113_VEH_solarData m113 : 21|1@1+ (1,0) [0|1] ""  gtw
 SG_ VCLEFT_a205_serviceAllowed m205 : 21|1@1+ (1,0) [0|1] ""  gtw
 SG_ VCLEFT_a166_THERMAL_BLOCKED m166 : 21|1@1+ (1,0) [0|1] ""  gtw
 SG_ VCLEFT_a213_serviceAllowed m213 : 21|1@1+ (1,0) [0|1] ""  gtw
 SG_ VCLEFT_a116_VEH_seatStatus m116 : 21|1@1+ (1,0) [0|1] ""  gtw
 SG_ VCLEFT_a012_ExternalReset m12 : 21|1@1+ (1,0) [0|1] ""  gtw
 SG_ VCLEFT_a129_VDS_HB m129 : 21|1@1+ (1,0) [0|1] ""  gtw
 SG_ VCLEFT_a130_TEMP_FLAG4 m130 : 21|1@1+ (1,0) [0|1] ""  gtw
 SG_ VCLEFT_a206_serviceAllowed m206 : 21|1@1+ (1,0) [0|1] ""  gtw
 SG_ VCLEFT_a117_VEH_lightStatus m117 : 21|1@1+ (1,0) [0|1] ""  gtw
 SG_ VCLEFT_a021_Task10msMissed m21 : 21|1@1+ (1,0) [0|1] ""  gtw
 SG_ VCLEFT_a302_motorStall m302 : 21|1@1+ (1,0) [0|1] ""  gtw
 SG_ VCLEFT_a212_serviceAllowed m212 : 21|1@1+ (1,0) [0|1] ""  gtw
 SG_ VCLEFT_a211_serviceAllowed m211 : 21|1@1+ (1,0) [0|1] ""  gtw
 SG_ VCLEFT_a208_serviceAllowed m208 : 21|1@1+ (1,0) [0|1] ""  gtw
 SG_ VCLEFT_a015_NVMMWriteFailed m15 : 21|1@1+ (1,0) [0|1] ""  gtw
 SG_ VCLEFT_a214_serviceAllowed m214 : 21|1@1+ (1,0) [0|1] ""  gtw
 SG_ VCLEFT_a202_serviceAllowed m202 : 21|1@1+ (1,0) [0|1] ""  gtw
 SG_ VCLEFT_a207_serviceAllowed m207 : 21|1@1+ (1,0) [0|1] ""  gtw
 SG_ VCLEFT_a204_serviceAllowed m204 : 21|1@1+ (1,0) [0|1] ""  gtw
 SG_ VCLEFT_a204_startAllowed m204 : 20|1@1+ (1,0) [0|1] ""  gtw
 SG_ VCLEFT_a130_vccUnderVoltage m130 : 20|1@1+ (1,0) [0|1] ""  gtw
 SG_ VCLEFT_a107_VEH_bmbMinMax m107 : 20|1@1+ (1,0) [0|1] ""  gtw
 SG_ VCLEFT_a129_VDS_LA m129 : 20|1@1+ (1,0) [0|1] ""  gtw
 SG_ VCLEFT_a203_startAllowed m203 : 20|1@1+ (1,0) [0|1] ""  gtw
 SG_ VCLEFT_a214_startAllowed m214 : 20|1@1+ (1,0) [0|1] ""  gtw
 SG_ VCLEFT_a117_VEH_restraintStatus m117 : 20|1@1+ (1,0) [0|1] ""  gtw
 SG_ VCLEFT_a012_DebugReset m12 : 20|1@1+ (1,0) [0|1] ""  gtw
 SG_ VCLEFT_a120_VEH_torque m120 : 20|1@1+ (1,0) [0|1] ""  gtw
 SG_ VCLEFT_a302_overRMSCurrent m302 : 20|1@1+ (1,0) [0|1] ""  gtw
 SG_ VCLEFT_a211_startAllowed m211 : 20|1@1+ (1,0) [0|1] ""  gtw
 SG_ VCLEFT_a113_VEH_vehicleControl2 m113 : 20|1@1+ (1,0) [0|1] ""  gtw
 SG_ VCLEFT_a208_startAllowed m208 : 20|1@1+ (1,0) [0|1] ""  gtw
 SG_ VCLEFT_a207_startAllowed m207 : 20|1@1+ (1,0) [0|1] ""  gtw
 SG_ VCLEFT_a131_thOverTemperature m131 : 20|1@1+ (1,0) [0|1] ""  gtw
 SG_ VCLEFT_a116_VEH_lightStatus m116 : 20|1@1+ (1,0) [0|1] ""  gtw
 SG_ VCLEFT_a202_startAllowed m202 : 20|1@1+ (1,0) [0|1] ""  gtw
 SG_ VCLEFT_a285_watchdogTimeout m285 : 20|1@1+ (1,0) [0|1] ""  gtw
 SG_ VCLEFT_a212_startAllowed m212 : 20|1@1+ (1,0) [0|1] ""  gtw
 SG_ VCLEFT_a206_startAllowed m206 : 20|1@1+ (1,0) [0|1] ""  gtw
 SG_ VCLEFT_a205_startAllowed m205 : 20|1@1+ (1,0) [0|1] ""  gtw
 SG_ VCLEFT_a021_Task10msStarved m21 : 20|1@1+ (1,0) [0|1] ""  gtw
 SG_ VCLEFT_a166_THERMAL m166 : 20|1@1+ (1,0) [0|1] ""  gtw
 SG_ VCLEFT_a015_NVMMMemOverflow m15 : 20|1@1+ (1,0) [0|1] ""  gtw
 SG_ VCLEFT_a213_startAllowed m213 : 20|1@1+ (1,0) [0|1] ""  gtw
 SG_ VCLEFT_a209_startAllowed m209 : 20|1@1+ (1,0) [0|1] ""  gtw
 SG_ VCLEFT_a210_startAllowed m210 : 20|1@1+ (1,0) [0|1] ""  gtw
 SG_ VCLEFT_a118_VEH_okToUseHighPwr m118 : 20|1@1+ (1,0) [0|1] ""  gtw
 SG_ VCLEFT_a166_PINCH_OVERRIDE m166 : 19|1@1+ (1,0) [0|1] ""  gtw
 SG_ VCLEFT_a164_lastState m164 : 19|3@1+ (1,0) [0|5] ""  gtw
 SG_ VCLEFT_a204_parkAllowed m204 : 19|1@1+ (1,0) [0|1] ""  gtw
 SG_ VCLEFT_a212_parkAllowed m212 : 19|1@1+ (1,0) [0|1] ""  gtw
 SG_ VCLEFT_a302_moduleOverCurrent m302 : 19|1@1+ (1,0) [0|1] ""  gtw
 SG_ VCLEFT_a131_vglUnderVoltage m131 : 19|1@1+ (1,0) [0|1] ""  gtw
 SG_ VCLEFT_a130_lossOfSpeedLock m130 : 19|1@1+ (1,0) [0|1] ""  gtw
 SG_ VCLEFT_a205_parkAllowed m205 : 19|1@1+ (1,0) [0|1] ""  gtw
 SG_ VCLEFT_a208_parkAllowed m208 : 19|1@1+ (1,0) [0|1] ""  gtw
 SG_ VCLEFT_a120_PARTY_torque m120 : 19|1@1+ (1,0) [0|1] ""  gtw
 SG_ VCLEFT_a211_parkAllowed m211 : 19|1@1+ (1,0) [0|1] ""  gtw
 SG_ VCLEFT_a276_mirrorState m276 : 19|3@1+ (1,0) [0|4] ""  gtw
 SG_ VCLEFT_a129_VDS_HA m129 : 19|1@1+ (1,0) [0|1] ""  gtw
 SG_ VCLEFT_a107_VEH_thermalStatus m107 : 19|1@1+ (1,0) [0|1] ""  gtw
 SG_ VCLEFT_a108_PARTY_torque m108 : 19|1@1+ (1,0) [0|1] ""  gtw
 SG_ VCLEFT_a202_parkAllowed m202 : 19|1@1+ (1,0) [0|1] ""  gtw
 SG_ VCLEFT_a118_VEH_status m118 : 19|1@1+ (1,0) [0|1] ""  gtw
 SG_ VCLEFT_a113_VEH_vehicleControl m113 : 19|1@1+ (1,0) [0|1] ""  gtw
 SG_ VCLEFT_a209_parkAllowed m209 : 19|1@1+ (1,0) [0|1] ""  gtw
 SG_ VCLEFT_a210_parkAllowed m210 : 19|1@1+ (1,0) [0|1] ""  gtw
 SG_ VCLEFT_a117_VEH_LVPowerState m117 : 19|1@1+ (1,0) [0|1] ""  gtw
 SG_ VCLEFT_a203_parkAllowed m203 : 19|1@1+ (1,0) [0|1] ""  gtw
 SG_ VCLEFT_a206_parkAllowed m206 : 19|1@1+ (1,0) [0|1] ""  gtw
 SG_ VCLEFT_a183_lastState m183 : 19|3@1+ (1,0) [0|6] ""  gtw
 SG_ VCLEFT_a109_PARTY_collision m109 : 19|1@1+ (1,0) [0|1] ""  gtw
 SG_ VCLEFT_a214_parkAllowed m214 : 19|1@1+ (1,0) [0|1] ""  gtw
 SG_ VCLEFT_a021_Task10msLate m21 : 19|1@1+ (1,0) [0|1] ""  gtw
 SG_ VCLEFT_a207_parkAllowed m207 : 19|1@1+ (1,0) [0|1] ""  gtw
 SG_ VCLEFT_a015_NVMMRecordUpgraded m15 : 19|1@1+ (1,0) [0|1] ""  gtw
 SG_ VCLEFT_a213_parkAllowed m213 : 19|1@1+ (1,0) [0|1] ""  gtw
 SG_ VCLEFT_a285_pwmOutputFault m285 : 19|1@1+ (1,0) [0|1] ""  gtw
 SG_ VCLEFT_a012_CheckstopReset m12 : 19|1@1+ (1,0) [0|1] ""  gtw
 SG_ VCLEFT_a114_PARTY_party3 m114 : 19|1@1+ (1,0) [0|1] ""  gtw
 SG_ VCLEFT_a116_VEH_LVPowerState m116 : 19|1@1+ (1,0) [0|1] ""  gtw
 SG_ VCLEFT_a216_monitor_MIA m216 : 19|1@1+ (1,0) [0|1] ""  gtw
 SG_ VCLEFT_a104_PARTY_control m104 : 19|1@1+ (1,0) [0|1] ""  gtw
 SG_ VCLEFT_a210_dynamicAllowed m210 : 18|1@1+ (1,0) [0|1] ""  gtw
 SG_ VCLEFT_a107_VEH_status m107 : 18|1@1+ (1,0) [0|1] ""  gtw
 SG_ VCLEFT_a117_VEH_hvacBlowerFdb m117 : 18|1@1+ (1,0) [0|1] ""  gtw
 SG_ VCLEFT_a272_actualState m272 : 18|2@1+ (1,0) [0|3] ""  gtw
 SG_ VCLEFT_a209_dynamicAllowed m209 : 18|1@1+ (1,0) [0|1] ""  gtw
 SG_ VCLEFT_a110_VEH_time m110 : 18|1@1+ (1,0) [0|1] ""  gtw
 SG_ VCLEFT_a012_SoftwareReset m12 : 18|1@1+ (1,0) [0|1] ""  gtw
 SG_ VCLEFT_a119_VEH_rightStalk m119 : 18|1@1+ (1,0) [0|1] ""  gtw
 SG_ VCLEFT_a106_VEH_thermalStatus m106 : 18|1@1+ (1,0) [0|1] ""  gtw
 SG_ VCLEFT_a203_dynamicAllowed m203 : 18|1@1+ (1,0) [0|1] ""  gtw
 SG_ VCLEFT_a196_lockoutState m196 : 18|1@1+ (1,0) [0|1] ""  gtw
 SG_ VCLEFT_a114_VEH_wheelSpeeds m114 : 18|1@1+ (1,0) [0|1] ""  gtw
 SG_ VCLEFT_a116_VEH_hvacRequest m116 : 18|1@1+ (1,0) [0|1] ""  gtw
 SG_ VCLEFT_a152_pinchTableBuilt m152 : 18|1@1+ (1,0) [0|1] ""  gtw
 SG_ VCLEFT_a015_NVMMVersionMismatch m15 : 18|1@1+ (1,0) [0|1] ""  gtw
 SG_ VCLEFT_a109_PARTY_nearDeploy m109 : 18|1@1+ (1,0) [0|1] ""  gtw
 SG_ VCLEFT_a130_startUpOperation m130 : 18|1@1+ (1,0) [0|1] ""  gtw
 SG_ VCLEFT_a205_dynamicAllowed m205 : 18|1@1+ (1,0) [0|1] ""  gtw
 SG_ VCLEFT_a165_windowRear m165 : 18|1@1+ (1,0) [0|1] ""  gtw
 SG_ VCLEFT_a102_VEH_sensorStatus m102 : 18|1@1+ (1,0) [0|1] ""  gtw
 SG_ VCLEFT_a166_PINCH_V2C m166 : 18|1@1+ (1,0) [0|1] ""  gtw
 SG_ VCLEFT_a213_dynamicAllowed m213 : 18|1@1+ (1,0) [0|1] ""  gtw
 SG_ VCLEFT_a108_VEH_torque m108 : 18|1@1+ (1,0) [0|1] ""  gtw
 SG_ VCLEFT_a183_doorRear m183 : 18|1@1+ (1,0) [0|1] ""  gtw
 SG_ VCLEFT_a153_pinchTableBuilt m153 : 18|1@1+ (1,0) [0|1] ""  gtw
 SG_ VCLEFT_a120_PARTY_systemStatus m120 : 18|1@1+ (1,0) [0|1] ""  gtw
 SG_ VCLEFT_a104_VEH_thermalStatus m104 : 18|1@1+ (1,0) [0|1] ""  gtw
 SG_ VCLEFT_a285_spiDiagError m285 : 18|1@1+ (1,0) [0|1] ""  gtw
 SG_ VCLEFT_a118_VEH_sensors m118 : 18|1@1+ (1,0) [0|1] ""  gtw
 SG_ VCLEFT_a206_dynamicAllowed m206 : 18|1@1+ (1,0) [0|1] ""  gtw
 SG_ VCLEFT_a021_Task1msMissed m21 : 18|1@1+ (1,0) [0|1] ""  gtw
 SG_ VCLEFT_a113_VEH_chargeRequest m113 : 18|1@1+ (1,0) [0|1] ""  gtw
 SG_ VCLEFT_a212_dynamicAllowed m212 : 18|1@1+ (1,0) [0|1] ""  gtw
 SG_ VCLEFT_a129_lockedRotor m129 : 18|1@1+ (1,0) [0|1] ""  gtw
 SG_ VCLEFT_a208_dynamicAllowed m208 : 18|1@1+ (1,0) [0|1] ""  gtw
 SG_ VCLEFT_a211_dynamicAllowed m211 : 18|1@1+ (1,0) [0|1] ""  gtw
 SG_ VCLEFT_a214_dynamicAllowed m214 : 18|1@1+ (1,0) [0|1] ""  gtw
 SG_ VCLEFT_a131_chpUnderVoltage m131 : 18|1@1+ (1,0) [0|1] ""  gtw
 SG_ VCLEFT_a103_VEH_status m103 : 18|1@1+ (1,0) [0|1] ""  gtw
 SG_ VCLEFT_a202_dynamicAllowed m202 : 18|1@1+ (1,0) [0|1] ""  gtw
 SG_ VCLEFT_a197_lockoutState m197 : 18|1@1+ (1,0) [0|1] ""  gtw
 SG_ VCLEFT_a136_DIbrakePedalState m136 : 18|2@1+ (1,0) [0|2] ""  gtw
 SG_ VCLEFT_a216_CRC_error m216 : 18|1@1+ (1,0) [0|1] ""  gtw
 SG_ VCLEFT_a207_dynamicAllowed m207 : 18|1@1+ (1,0) [0|1] ""  gtw
 SG_ VCLEFT_a302_motorOverTemperature m302 : 18|1@1+ (1,0) [0|1] ""  gtw
 SG_ VCLEFT_a164_windowRear m164 : 18|1@1+ (1,0) [0|1] ""  gtw
 SG_ VCLEFT_a204_dynamicAllowed m204 : 18|1@1+ (1,0) [0|1] ""  gtw
 SG_ VCLEFT_a211_openAllowed m211 : 17|1@1+ (1,0) [0|1] ""  gtw
 SG_ VCLEFT_a103_VEH_vehNm m103 : 17|1@1+ (1,0) [0|1] ""  gtw
 SG_ VCLEFT_a120_VEH_systemStatus m120 : 17|1@1+ (1,0) [0|1] ""  gtw
 SG_ VCLEFT_a208_openAllowed m208 : 17|1@1+ (1,0) [0|1] ""  gtw
 SG_ VCLEFT_a227_seatMotorCurrent m227 : 17|12@1- (0.01,0) [-20.48|20.47] "A"  gtw
 SG_ VCLEFT_a220_seatMotorCurrent m220 : 17|12@1- (0.01,0) [-20.48|20.47] "A"  gtw
 SG_ VCLEFT_a002_PowerOnReset m2 : 17|1@1+ (1,0) [0|1] ""  gtw
 SG_ VCLEFT_a013_ClearQueueFull m13 : 17|1@1+ (1,0) [0|1] ""  gtw
 SG_ VCLEFT_a207_openAllowed m207 : 17|1@1+ (1,0) [0|1] ""  gtw
 SG_ VCLEFT_a115_VEH_authentication m115 : 17|1@1+ (1,0) [0|1] ""  gtw
 SG_ VCLEFT_a098_VEH_temperature m98 : 17|1@1+ (1,0) [0|1] ""  gtw
 SG_ VCLEFT_a202_openAllowed m202 : 17|1@1+ (1,0) [0|1] ""  gtw
 SG_ VCLEFT_a129_fetShortCircuit m129 : 17|1@1+ (1,0) [0|1] ""  gtw
 SG_ VCLEFT_a152_endStopTrusted m152 : 17|1@1+ (1,0) [0|1] ""  gtw
 SG_ VCLEFT_a196_NVRAMState m196 : 17|1@1+ (1,0) [0|1] ""  gtw
 SG_ VCLEFT_a119_VEH_leftStalk m119 : 17|1@1+ (1,0) [0|1] ""  gtw
 SG_ VCLEFT_a209_openAllowed m209 : 17|1@1+ (1,0) [0|1] ""  gtw
 SG_ VCLEFT_a100_PARTY m100 : 17|1@1+ (1,0) [0|1] ""  gtw
 SG_ VCLEFT_a210_openAllowed m210 : 17|1@1+ (1,0) [0|1] ""  gtw
 SG_ VCLEFT_a112_VEH_status m112 : 17|1@1+ (1,0) [0|1] ""  gtw
 SG_ VCLEFT_a015_NVMMCRCMismatch m15 : 17|1@1+ (1,0) [0|1] ""  gtw
 SG_ VCLEFT_a118_VEH_lighting m118 : 17|1@1+ (1,0) [0|1] ""  gtw
 SG_ VCLEFT_a204_openAllowed m204 : 17|1@1+ (1,0) [0|1] ""  gtw
 SG_ VCLEFT_a131_vsOverVoltage m131 : 17|1@1+ (1,0) [0|1] ""  gtw
 SG_ VCLEFT_a060_resetUnlocked m60 : 17|1@1+ (1,0) [0|1] ""  gtw
 SG_ VCLEFT_a116_VEH_vehNm m116 : 17|1@1+ (1,0) [0|1] ""  gtw
 SG_ VCLEFT_a203_openAllowed m203 : 17|1@1+ (1,0) [0|1] ""  gtw
 SG_ VCLEFT_a104_VEH_bodyControls m104 : 17|1@1+ (1,0) [0|1] ""  gtw
 SG_ VCLEFT_a224_seatMotorCurrent m224 : 17|12@1- (0.01,0) [-20.48|20.47] "A"  gtw
 SG_ VCLEFT_a285_spiRegisterMismatch m285 : 17|1@1+ (1,0) [0|1] ""  gtw
 SG_ VCLEFT_a221_seatMotorCurrent m221 : 17|12@1- (0.01,0) [-20.48|20.47] "A"  gtw
 SG_ VCLEFT_a205_openAllowed m205 : 17|1@1+ (1,0) [0|1] ""  gtw
 SG_ VCLEFT_a117_VEH_vehNm m117 : 17|1@1+ (1,0) [0|1] ""  gtw
 SG_ VCLEFT_a222_seatMotorCurrent m222 : 17|12@1- (0.01,0) [-20.48|20.47] "A"  gtw
 SG_ VCLEFT_a110_VEH_carConfig m110 : 17|1@1+ (1,0) [0|1] ""  gtw
 SG_ VCLEFT_a164_windowFront m164 : 17|1@1+ (1,0) [0|1] ""  gtw
 SG_ VCLEFT_a130_junctionOverTemp m130 : 17|1@1+ (1,0) [0|1] ""  gtw
 SG_ VCLEFT_a197_NVRAMState m197 : 17|1@1+ (1,0) [0|1] ""  gtw
 SG_ VCLEFT_a228_seatMotorCurrent m228 : 17|12@1- (0.01,0) [-20.48|20.47] "A"  gtw
 SG_ VCLEFT_a111_VEH_status m111 : 17|1@1+ (1,0) [0|1] ""  gtw
 SG_ VCLEFT_a166_windowRear m166 : 17|1@1+ (1,0) [0|1] ""  gtw
 SG_ VCLEFT_a231_seatMotorCurrent m231 : 17|12@1- (0.01,0) [-20.48|20.47] "A"  gtw
 SG_ VCLEFT_a108_VEH_thermalControl m108 : 17|1@1+ (1,0) [0|1] ""  gtw
 SG_ VCLEFT_a213_openAllowed m213 : 17|1@1+ (1,0) [0|1] ""  gtw
 SG_ VCLEFT_a225_seatMotorCurrent m225 : 17|12@1- (0.01,0) [-20.48|20.47] "A"  gtw
 SG_ VCLEFT_a165_windowFront m165 : 17|1@1+ (1,0) [0|1] ""  gtw
 SG_ VCLEFT_a226_seatMotorCurrent m226 : 17|12@1- (0.01,0) [-20.48|20.47] "A"  gtw
 SG_ VCLEFT_a106_VEH_thermalControl m106 : 17|1@1+ (1,0) [0|1] ""  gtw
 SG_ VCLEFT_a113_VEH_hvacRequest m113 : 17|1@1+ (1,0) [0|1] ""  gtw
 SG_ VCLEFT_a107_VEH_vehNm m107 : 17|1@1+ (1,0) [0|1] ""  gtw
 SG_ VCLEFT_a021_Task1msStarved m21 : 17|1@1+ (1,0) [0|1] ""  gtw
 SG_ VCLEFT_a102_VEH_feedbackStatus m102 : 17|1@1+ (1,0) [0|1] ""  gtw
 SG_ VCLEFT_a223_seatMotorCurrent m223 : 17|12@1- (0.01,0) [-20.48|20.47] "A"  gtw
 SG_ VCLEFT_a114_PARTY_wheelSpeeds m114 : 17|1@1+ (1,0) [0|1] ""  gtw
 SG_ VCLEFT_a153_endStopTrusted m153 : 17|1@1+ (1,0) [0|1] ""  gtw
 SG_ VCLEFT_a097_VEH_state m97 : 17|1@1+ (1,0) [0|1] ""  gtw
 SG_ VCLEFT_a183_doorFront m183 : 17|1@1+ (1,0) [0|1] ""  gtw
 SG_ VCLEFT_a212_openAllowed m212 : 17|1@1+ (1,0) [0|1] ""  gtw
 SG_ VCLEFT_a216_spiFault m216 : 17|1@1+ (1,0) [0|1] ""  gtw
 SG_ VCLEFT_a105_VEH_chNm m105 : 17|1@1+ (1,0) [0|1] ""  gtw
 SG_ VCLEFT_a010_UnderVoltageTimeout m10 : 17|1@1+ (1,0) [0|1] ""  gtw
 SG_ VCLEFT_a206_openAllowed m206 : 17|1@1+ (1,0) [0|1] ""  gtw
 SG_ VCLEFT_a230_seatMotorCurrent m230 : 17|12@1- (0.01,0) [-20.48|20.47] "A"  gtw
 SG_ VCLEFT_a229_seatMotorCurrent m229 : 17|12@1- (0.01,0) [-20.48|20.47] "A"  gtw
 SG_ VCLEFT_a012_FlashError m12 : 17|1@1+ (1,0) [0|1] ""  gtw
 SG_ VCLEFT_a214_openAllowed m214 : 17|1@1+ (1,0) [0|1] ""  gtw
 SG_ VCLEFT_a109_PARTY_inertial2 m109 : 17|1@1+ (1,0) [0|1] ""  gtw
 SG_ VCLEFT_a302_underVoltage m302 : 17|1@1+ (1,0) [0|1] ""  gtw
 SG_ VCLEFT_a273_handlePWM m273 : 16|7@1+ (1,0) [0|100] "%"  gtw
 SG_ VCLEFT_a204_unknownAllowed m204 : 16|1@1+ (1,0) [0|1] ""  gtw
 SG_ VCLEFT_a111_VEH_internalStatus m111 : 16|1@1+ (1,0) [0|1] ""  gtw
 SG_ VCLEFT_a102_VEH_faults m102 : 16|1@1+ (1,0) [0|1] ""  gtw
 SG_ VCLEFT_a292_occupancySensorV m292 : 16|12@1- (0.01,0) [-20.48|20.47] "V"  gtw
 SG_ VCLEFT_a263_seatMotorCurrent m263 : 16|12@1- (0.01,0) [-20.48|20.47] "A"  gtw
 SG_ VCLEFT_a002_CPUUndervoltage m2 : 16|1@1+ (1,0) [0|1] ""  gtw
 SG_ VCLEFT_a196_outputState m196 : 16|1@1+ (1,0) [0|1] ""  gtw
 SG_ VCLEFT_a203_unknownAllowed m203 : 16|1@1+ (1,0) [0|1] ""  gtw
 SG_ VCLEFT_a238_lumbarAPressureHpa m238 : 16|16@1+ (1,0) [0|65535] ""  gtw
 SG_ VCLEFT_a264_seatMotorCurrent m264 : 16|12@1- (0.01,0) [-20.48|20.47] "A"  gtw
 SG_ VCLEFT_a222_seatMotorCalibrated m222 : 16|1@1+ (1,0) [0|1] ""  gtw
 SG_ VCLEFT_a260_disarmDelay m260 : 16|7@1+ (10,0) [0|1270] "ms"  gtw
 SG_ VCLEFT_a306_disconnectedTime m306 : 16|10@1+ (1,0) [0|1000] "ms"  gtw
 SG_ VCLEFT_a108_VEH_temperature m108 : 16|1@1+ (1,0) [0|1] ""  gtw
 SG_ VCLEFT_a115_VEH_vehNm m115 : 16|1@1+ (1,0) [0|1] ""  gtw
 SG_ VCLEFT_a132_RPMActual m132 : 16|10@1+ (10,0) [0|10000] "RPM"  gtw
 SG_ VCLEFT_a219_motorChannels m219 : 16|16@1+ (1,0) [0|65535] ""  gtw
 SG_ VCLEFT_a305_handleADCmV m305 : 16|8@1+ (5,0) [0|1000] "mV"  gtw
 SG_ VCLEFT_a183_testPassed m183 : 16|1@1+ (1,0) [0|1] ""  gtw
 SG_ VCLEFT_a227_seatMotorCalibrated m227 : 16|1@1+ (1,0) [0|1] ""  gtw
 SG_ VCLEFT_a295_buckleSensorVoltage m295 : 16|12@1- (0.01,0) [-20.48|20.47] "V"  gtw
 SG_ VCLEFT_a216_noData m216 : 16|1@1+ (1,0) [0|1] ""  gtw
 SG_ VCLEFT_a270_seatMotorCurrent m270 : 16|12@1- (0.01,0) [-20.48|20.47] "A"  gtw
 SG_ VCLEFT_a043_CallTrace0 m43 : 16|24@1+ (1,0) [0|16777215] ""  gtw
 SG_ VCLEFT_a240_seatHeatCurrent m240 : 16|12@1+ (0.01,0) [0|40.95] "A"  gtw
 SG_ VCLEFT_a131_vsUnderVoltage m131 : 16|1@1+ (1,0) [0|1] ""  gtw
 SG_ VCLEFT_a252_seatMotorCurrent m252 : 16|12@1- (0.01,0) [-20.48|20.47] "A"  gtw
 SG_ VCLEFT_a022_TaskInitErrorCount m22 : 16|8@1+ (1,0) [0|255] ""  gtw
 SG_ VCLEFT_a269_seatMotorCurrent m269 : 16|12@1- (0.01,0) [-20.48|20.47] "A"  gtw
 SG_ VCLEFT_a234_seatMotorCurrent m234 : 16|12@1- (0.01,0) [-20.48|20.47] "A"  gtw
 SG_ VCLEFT_a107_VEH_hvsNm m107 : 16|1@1+ (1,0) [0|1] ""  gtw
 SG_ VCLEFT_a154_windowThermalMode m154 : 16|2@1+ (1,0) [0|3] ""  gtw
 SG_ VCLEFT_a187_voltage m187 : 16|7@1+ (0.15,0) [0|19] "V"  gtw
 SG_ VCLEFT_a013_LogQueueFull m13 : 16|1@1+ (1,0) [0|1] ""  gtw
 SG_ VCLEFT_a166_windowFront m166 : 16|1@1+ (1,0) [0|1] ""  gtw
 SG_ VCLEFT_a197_outputState m197 : 16|1@1+ (1,0) [0|1] ""  gtw
 SG_ VCLEFT_a214_unknownAllowed m214 : 16|1@1+ (1,0) [0|1] ""  gtw
 SG_ VCLEFT_a251_seatMotorCurrent m251 : 16|12@1- (0.01,0) [-20.48|20.47] "A"  gtw
 SG_ VCLEFT_a310_mirrorFoldTime m310 : 16|8@1+ (10,0) [0|2550] "ms"  gtw
 SG_ VCLEFT_a059_voltageDrop m59 : 16|12@1+ (0.005443676098,0) [0|22.29185] "V"  gtw
 SG_ VCLEFT_a236_lumbarAPressureHpa m236 : 16|16@1+ (1,0) [0|65535] ""  gtw
 SG_ VCLEFT_a232_seatMotorCurrent m232 : 16|12@1- (0.01,0) [-20.48|20.47] "A"  gtw
 SG_ VCLEFT_a221_seatMotorCalibrated m221 : 16|1@1+ (1,0) [0|1] ""  gtw
 SG_ VCLEFT_a239_seatHeatCurrent m239 : 16|12@1+ (0.01,0) [0|40.95] "A"  gtw
 SG_ VCLEFT_a015_NVMMRecordNotFound m15 : 16|1@1+ (1,0) [0|1] ""  gtw
 SG_ VCLEFT_a168_windowPosition m168 : 16|8@1+ (10,0) [0|2550] "ticks"  gtw
 SG_ VCLEFT_a211_unknownAllowed m211 : 16|1@1+ (1,0) [0|1] ""  gtw
 SG_ VCLEFT_a130_junctionTempWarning m130 : 16|1@1+ (1,0) [0|1] ""  gtw
 SG_ VCLEFT_a254_seatMotorCurrent m254 : 16|12@1- (0.01,0) [-20.48|20.47] "A"  gtw
 SG_ VCLEFT_a282_voltage m282 : 16|7@1+ (0.15,0) [0|19] "V"  gtw
 SG_ VCLEFT_a045_CallTrace0 m45 : 16|24@1+ (1,0) [0|16777215] ""  gtw
 SG_ VCLEFT_a180_intButtonPressed m180 : 16|1@1+ (1,0) [0|1] ""  gtw
 SG_ VCLEFT_a208_unknownAllowed m208 : 16|1@1+ (1,0) [0|1] ""  gtw
 SG_ VCLEFT_a279_voltageInmV m279 : 16|16@1+ (1,0) [0|65535] ""  gtw
 SG_ VCLEFT_a241_seatHeatTmp m241 : 16|12@1- (0.05,0) [-40|80] "degC"  gtw
 SG_ VCLEFT_a186_voltage m186 : 16|7@1+ (0.15,0) [0|19] "V"  gtw
 SG_ VCLEFT_a226_seatMotorCalibrated m226 : 16|1@1+ (1,0) [0|1] ""  gtw
 SG_ VCLEFT_a164_testPassed m164 : 16|1@1+ (1,0) [0|1] ""  gtw
 SG_ VCLEFT_a207_unknownAllowed m207 : 16|1@1+ (1,0) [0|1] ""  gtw
 SG_ VCLEFT_a302_overVoltage m302 : 16|1@1+ (1,0) [0|1] ""  gtw
 SG_ VCLEFT_a155_windowThermalMode m155 : 16|2@1+ (1,0) [0|3] ""  gtw
 SG_ VCLEFT_a010_UnderVoltageDetected m10 : 16|1@1+ (1,0) [0|1] ""  gtw
 SG_ VCLEFT_a185_summonFaultReason m185 : 16|5@1+ (1,0) [0|28] ""  gtw
 SG_ VCLEFT_a167_windowPosition m167 : 16|8@1+ (10,0) [0|2550] "ticks"  gtw
 SG_ VCLEFT_a112_VEH_internalStatus m112 : 16|1@1+ (1,0) [0|1] ""  gtw
 SG_ VCLEFT_a152_zeroed m152 : 16|1@1+ (1,0) [0|1] ""  gtw
 SG_ VCLEFT_a202_unknownAllowed m202 : 16|1@1+ (1,0) [0|1] ""  gtw
 SG_ VCLEFT_a294_occupancySensorV m294 : 16|12@1- (0.01,0) [-20.48|20.47] "V"  gtw
 SG_ VCLEFT_a320_positionStart m320 : 16|10@1+ (2,0) [0|2046] "ticks"  gtw
 SG_ VCLEFT_a265_seatMotorCurrent m265 : 16|12@1- (0.01,0) [-20.48|20.47] "A"  gtw
 SG_ VCLEFT_a200_voltage m200 : 16|7@1+ (0.15,0) [0|19] "V"  gtw
 SG_ VCLEFT_a307_disconnectedTime m307 : 16|10@1+ (1,0) [0|1000] "ms"  gtw
 SG_ VCLEFT_a220_seatMotorCalibrated m220 : 16|1@1+ (1,0) [0|1] ""  gtw
 SG_ VCLEFT_a110_VEH_carState m110 : 16|1@1+ (1,0) [0|1] ""  gtw
 SG_ VCLEFT_a278_voltageInmV m278 : 16|16@1+ (1,0) [0|65535] ""  gtw
 SG_ VCLEFT_a215_desyncCount m215 : 16|8@1+ (1,0) [0|255] ""  gtw
 SG_ VCLEFT_a259_disarmDelay m259 : 16|7@1+ (10,0) [0|1270] "ms"  gtw
 SG_ VCLEFT_a060_lockoutDisabled m60 : 16|1@1+ (1,0) [0|1] ""  gtw
 SG_ VCLEFT_a064_busBitField m64 : 16|8@1+ (1,0) [0|255] ""  gtw
 SG_ VCLEFT_a283_voltage m283 : 16|7@1+ (0.15,0) [0|19] "V"  gtw
 SG_ VCLEFT_a099_VEH_oocStatus m99 : 16|1@1+ (1,0) [0|1] ""  gtw
 SG_ VCLEFT_a012_ClockError m12 : 16|1@1+ (1,0) [0|1] ""  gtw
 SG_ VCLEFT_a266_seatMotorCurrent m266 : 16|12@1- (0.01,0) [-20.48|20.47] "A"  gtw
 SG_ VCLEFT_a237_lumbarAPressureHpa m237 : 16|16@1+ (1,0) [0|65535] ""  gtw
 SG_ VCLEFT_a225_seatMotorCalibrated m225 : 16|1@1+ (1,0) [0|1] ""  gtw
 SG_ VCLEFT_a242_seatHeatCurrent m242 : 16|12@1+ (0.01,0) [0|40.95] "A"  gtw
 SG_ VCLEFT_a285_spiErrorCount m285 : 16|1@1+ (1,0) [0|1] ""  gtw
 SG_ VCLEFT_a272_expectedState m272 : 16|2@1+ (1,0) [0|3] ""  gtw
 SG_ VCLEFT_a156_windowThermalMode m156 : 16|2@1+ (1,0) [0|3] ""  gtw
 SG_ VCLEFT_a287_windowSpeed m287 : 16|8@1- (100,0) [-12800|12700] "ticksPerSecond"  gtw
 SG_ VCLEFT_a201_voltage m201 : 16|7@1+ (0.15,0) [0|19] "V"  gtw
 SG_ VCLEFT_a170_currentPeakCurrent m170 : 16|6@1+ (0.1,0) [0|6.3] "A"  gtw
 SG_ VCLEFT_a116_PARTY_epbmStatus m116 : 16|1@1+ (1,0) [0|1] ""  gtw
 SG_ VCLEFT_a274_handlePWM m274 : 16|7@1+ (1,0) [0|100] "%"  gtw
 SG_ VCLEFT_a321_positionStart m321 : 16|10@1+ (2,0) [0|2046] "ticks"  gtw
 SG_ VCLEFT_a136_brakeSwitch m136 : 16|2@1+ (1,0) [0|3] ""  gtw
 SG_ VCLEFT_a114_PARTY_status m114 : 16|1@1+ (1,0) [0|1] ""  gtw
 SG_ VCLEFT_a212_unknownAllowed m212 : 16|1@1+ (1,0) [0|1] ""  gtw
 SG_ VCLEFT_a000_alertDataW0 m0 : 16|16@1+ (1,0) [0|65535] ""  X
 SG_ VCLEFT_a137_VCSECPowerCycleCount m137 : 16|8@1+ (1,0) [0|255] ""  gtw
 SG_ VCLEFT_a104_VEH_chNm m104 : 16|1@1+ (1,0) [0|1] ""  gtw
 SG_ VCLEFT_a046_CallTrace0 m46 : 16|24@1+ (1,0) [0|16777215] ""  gtw
 SG_ VCLEFT_a169_currentPeakCurrent m169 : 16|6@1+ (0.1,0) [0|6.3] "A"  gtw
 SG_ VCLEFT_a098_VEH_thermalControl m98 : 16|1@1+ (1,0) [0|1] ""  gtw
 SG_ VCLEFT_a042_Usage1msTask m42 : 16|8@1+ (1,0) [0|255] ""  gtw
 SG_ VCLEFT_a119_VEH_steerAngle m119 : 16|1@1+ (1,0) [0|1] ""  gtw
 SG_ VCLEFT_a150_windowPosition m150 : 16|8@1+ (10,0) [0|2550] "ticks"  gtw
 SG_ VCLEFT_a003_AssertID m3 : 16|16@1+ (1,0) [0|65535] ""  gtw
 SG_ VCLEFT_a063_switchChannel m63 : 16|8@1+ (1,0) [0|255] ""  gtw
 SG_ VCLEFT_a118_VEH_vehNm m118 : 16|1@1+ (1,0) [0|1] ""  gtw
 SG_ VCLEFT_a165_testPassed m165 : 16|1@1+ (1,0) [0|1] ""  gtw
 SG_ VCLEFT_a153_zeroed m153 : 16|1@1+ (1,0) [0|1] ""  gtw
 SG_ VCLEFT_a105_VEH_states m105 : 16|1@1+ (1,0) [0|1] ""  gtw
 SG_ VCLEFT_a206_unknownAllowed m206 : 16|1@1+ (1,0) [0|1] ""  gtw
 SG_ VCLEFT_a290_occupancySensorV m290 : 16|12@1- (0.01,0) [-20.48|20.47] "V"  gtw
 SG_ VCLEFT_a277_voltageInmV m277 : 16|16@1+ (1,0) [0|65535] ""  gtw
 SG_ VCLEFT_a190_eFuseTripCount m190 : 16|8@1+ (1,0) [0|255] ""  gtw
 SG_ VCLEFT_a303_eFuseTripCount m303 : 16|8@1+ (1,0) [0|255] ""  gtw
 SG_ VCLEFT_a106_VEH_dcdcStatus m106 : 16|1@1+ (1,0) [0|1] ""  gtw
 SG_ VCLEFT_a157_windowThermalMode m157 : 16|2@1+ (1,0) [0|3] ""  gtw
 SG_ VCLEFT_a286_windowSpeed m286 : 16|8@1- (100,0) [-12800|12700] "ticksPerSecond"  gtw
 SG_ VCLEFT_a041_CPULoadTotal m41 : 16|8@1+ (1,0) [0|255] ""  gtw
 SG_ VCLEFT_a284_RPMActual m284 : 16|10@1+ (10,0) [0|10000] "RPM"  gtw
 SG_ VCLEFT_a120_PARTY_chassisCntl m120 : 16|1@1+ (1,0) [0|1] ""  gtw
 SG_ VCLEFT_a205_unknownAllowed m205 : 16|1@1+ (1,0) [0|1] ""  gtw
 SG_ VCLEFT_a243_seatHeatCurrent m243 : 16|12@1+ (0.01,0) [0|40.95] "A"  gtw
 SG_ VCLEFT_a224_seatMotorCalibrated m224 : 16|1@1+ (1,0) [0|1] ""  gtw
 SG_ VCLEFT_a293_occupancySensorV m293 : 16|12@1- (0.01,0) [-20.48|20.47] "V"  gtw
 SG_ VCLEFT_a217_byte4 m217 : 16|8@1+ (1,0) [0|255] ""  gtw
 SG_ VCLEFT_a267_seatMotorCurrent m267 : 16|12@1- (0.01,0) [-20.48|20.47] "A"  gtw
 SG_ VCLEFT_a230_seatMotorCalibrated m230 : 16|1@1+ (1,0) [0|1] ""  gtw
 SG_ VCLEFT_a189_voltage m189 : 16|7@1+ (0.15,0) [0|19] "V"  gtw
 SG_ VCLEFT_a141_outputCurrent m141 : 16|16@1+ (0.1,0) [0|6553.5] "A"  gtw
 SG_ VCLEFT_a322_positionStart m322 : 16|10@1+ (2,0) [0|2046] "ticks"  gtw
 SG_ VCLEFT_a100_VEH m100 : 16|1@1+ (1,0) [0|1] ""  gtw
 SG_ VCLEFT_a030_logId m30 : 16|4@1+ (1,0) [0|15] ""  gtw
 SG_ VCLEFT_a229_seatMotorCalibrated m229 : 16|1@1+ (1,0) [0|1] ""  gtw
 SG_ VCLEFT_a268_seatMotorCurrent m268 : 16|12@1- (0.01,0) [-20.48|20.47] "A"  gtw
 SG_ VCLEFT_a235_seatMotorCurrent m235 : 16|12@1- (0.01,0) [-20.48|20.47] "A"  gtw
 SG_ VCLEFT_a324_mirrorHeatCurrent m324 : 16|10@1+ (0.01,0) [0|10] "A"  gtw
 SG_ VCLEFT_a021_Task1msLate m21 : 16|1@1+ (1,0) [0|1] ""  gtw
 SG_ VCLEFT_a109_PARTY_status m109 : 16|1@1+ (1,0) [0|1] ""  gtw
 SG_ VCLEFT_a253_seatMotorCurrent m253 : 16|12@1- (0.01,0) [-20.48|20.47] "A"  gtw
 SG_ VCLEFT_a113_VEH_ethNm m113 : 16|1@1+ (1,0) [0|1] ""  gtw
 SG_ VCLEFT_a129_overCurrentError m129 : 16|1@1+ (1,0) [0|1] ""  gtw
 SG_ VCLEFT_a151_windowPosition m151 : 16|8@1+ (10,0) [0|2550] "ticks"  gtw
 SG_ VCLEFT_a223_seatMotorCalibrated m223 : 16|1@1+ (1,0) [0|1] ""  gtw
 SG_ VCLEFT_a133_RPMActual m133 : 16|10@1+ (10,0) [0|10000] "RPM"  gtw
 SG_ VCLEFT_a103_VEH_hvsNm m103 : 16|1@1+ (1,0) [0|1] ""  gtw
 SG_ VCLEFT_a097_VEH_HVStatus m97 : 16|1@1+ (1,0) [0|1] ""  gtw
 SG_ VCLEFT_a304_handleADCmV m304 : 16|8@1+ (5,0) [0|1000] "mV"  gtw
 SG_ VCLEFT_a213_unknownAllowed m213 : 16|1@1+ (1,0) [0|1] ""  gtw
 SG_ VCLEFT_a309_5VMainVoltage m309 : 16|12@1- (0.01,0) [-20.48|20.47] "V"  gtw
 SG_ VCLEFT_a244_seatHeatTmp m244 : 16|12@1- (0.05,0) [-40|80] "degC"  gtw
 SG_ VCLEFT_a117_PARTY_epbmStatus m117 : 16|1@1+ (1,0) [0|1] ""  gtw
 SG_ VCLEFT_a218_motorChannels m218 : 16|16@1+ (1,0) [0|65535] ""  gtw
 SG_ VCLEFT_a291_buckleSensorVoltage m291 : 16|12@1+ (0.01,0) [0|40.95] "V"  gtw
 SG_ VCLEFT_a181_intButtonPressed m181 : 16|1@1+ (1,0) [0|1] ""  gtw
 SG_ VCLEFT_a188_voltage m188 : 16|7@1+ (0.15,0) [0|19] "V"  gtw
 SG_ VCLEFT_a101_VEH_state m101 : 16|1@1+ (1,0) [0|1] ""  gtw
 SG_ VCLEFT_a233_seatMotorCurrent m233 : 16|12@1- (0.01,0) [-20.48|20.47] "A"  gtw
 SG_ VCLEFT_a231_seatMotorCalibrated m231 : 16|1@1+ (1,0) [0|1] ""  gtw
 SG_ VCLEFT_a001_InternalWatchdog m1 : 16|1@1+ (1,0) [0|1] ""  gtw
 SG_ VCLEFT_a323_positionStart m323 : 16|10@1+ (2,0) [0|2046] "ticks"  gtw
 SG_ VCLEFT_a210_unknownAllowed m210 : 16|1@1+ (1,0) [0|1] ""  gtw
 SG_ VCLEFT_a276_mirrorDebugType m276 : 16|3@1+ (1,0) [0|6] ""  gtw
 SG_ VCLEFT_a228_seatMotorCalibrated m228 : 16|1@1+ (1,0) [0|1] ""  gtw
 SG_ VCLEFT_a209_unknownAllowed m209 : 16|1@1+ (1,0) [0|1] ""  gtw
 SG_ VCLEFT_a044_CallTrace0 m44 : 16|24@1+ (1,0) [0|16777215] ""  gtw
 SG_ VCLEFT_alertType : 15|1@1+ (1,0) [0|1] ""  gtw
 SG_ VCLEFT_alertID M : 0|9@1+ (1,0) [0|324] ""  gtw

BO_ 812 CC_logData: 8 VEH
 SG_ CC_temperature4 m0 : 44|8@1- (1,88) [-40|215] "DegC"  gtw
 SG_ CC_contactor2Closed m0 : 42|2@1+ (1,0) [0|3] ""  gtw
 SG_ CC_contactor1Closed m0 : 40|2@1+ (1,0) [0|3] ""  gtw
 SG_ CC_lifetimeThermalFoldbacks m12 : 36|28@1+ (1,0) [0|268435455] ""  gtw
 SG_ CC_lifetimeCtrCyclesLoaded m11 : 36|28@1+ (1,0) [0|268435455] ""  gtw
 SG_ CC_lifetimeAvgStartupTemp m13 : 36|28@1- (0.1,0) [-13421772.8|13421772.7] "degC"  gtw
 SG_ CC_lifetimei2t m10 : 32|32@1+ (0.1,0) [0|429496729.5] "A2h"  gtw
 SG_ CC_temperature3 m0 : 32|8@1- (1,88) [-40|215] "DegC"  gtw
 SG_ CC_temperature2 m0 : 24|8@1- (1,88) [-40|215] "DegC"  gtw
 SG_ CC_temperature1 m0 : 16|8@1- (1,88) [-40|215] "DegC"  gtw
 SG_ CC_conn3Current m3 : 8|8@1+ (0.5,0) [0|127.5] "A"  gtw
 SG_ CC_lifetimeAlertCount m12 : 8|28@1+ (1,0) [0|268435455] ""  gtw
 SG_ CC_conn4Current m4 : 8|8@1+ (0.5,0) [0|127.5] "A"  gtw
 SG_ CC_activeConnectorID m0 : 8|8@1+ (1,0) [0|255] ""  gtw
 SG_ CC_lifetimeCtrCycles m11 : 8|28@1+ (1,0) [0|268435455] ""  gtw
 SG_ CC_conn1Current m1 : 8|8@1+ (0.5,0) [0|127.5] "A"  gtw
 SG_ CC_conn2Current m2 : 8|8@1+ (0.5,0) [0|127.5] "A"  gtw
 SG_ CC_logIndex M : 0|8@1+ (1,0) [0|13] ""  dbg

BO_ 1795 VCRIGHT_debugThermal10Hz: 8 VEH
 SG_ VCRIGHT_wattsHeaterRightFeedfwd m0 : 48|9@1+ (20,0) [0|4000] "W"  X
 SG_ VCRIGHT_setTempAdjustmentRight m3 : 40|7@1+ (0.1,0) [0|12] "degC"  X
 SG_ VCRIGHT_wattsHeaterRightFeedback m0 : 39|9@1- (20,0) [-1000|1000] "W"  X
 SG_ VCRIGHT_setTempAdjustmentLeft m3 : 32|7@1+ (0.1,0) [0|12] "degC"  X
 SG_ VCRIGHT_hvacPanelFloorSplitRow2 m2 : 32|8@1+ (0.4,0) [0|100] "%"  X
 SG_ VCRIGHT_wattsHeaterLeftFeedfwd m0 : 30|9@1+ (20,0) [0|4000] "W"  X
 SG_ VCRIGHT_hvacIntakeCalibrated m4 : 27|1@1+ (1,0) [0|1] ""  X
 SG_ VCRIGHT_cabinTempProbe m3 : 24|8@1+ (0.5,-40) [-40|80] "degC"  gtw
 SG_ VCRIGHT_hvacRow2Percent m2 : 24|8@1+ (0.4,0) [0|100] "%"  gtw
 SG_ VCRIGHT_hvacLowerModeCalibrated m4 : 23|1@1+ (1,0) [0|1] ""  X
 SG_ VCRIGHT_wattsHeaterLeftFeedback m0 : 21|9@1- (20,0) [-1000|1000] "W"  X
 SG_ VCRIGHT_hvacUpperModeCalibrated m4 : 19|1@1+ (1,0) [0|1] ""  X
 SG_ VCRIGHT_tempEvapAdjustmentRight m1 : 16|7@1+ (0.1,0) [0|9] "degC"  X
 SG_ VCRIGHT_hvacDefrostPercent m2 : 16|8@1+ (0.4,0) [0|100] "%"  X
 SG_ VCRIGHT_cabinTempThsBracket m3 : 16|8@1+ (0.5,-40) [-40|80] "degC"  X
 SG_ VCRIGHT_hvacRHVaneCalibrated m4 : 15|1@1+ (1,0) [0|1] ""  X
 SG_ VCRIGHT_wattsDemandEvapFeedfwd m0 : 12|9@1+ (20,0) [0|10000] "W"  X
 SG_ VCRIGHT_hvacLHVaneCalibrated m4 : 11|1@1+ (1,0) [0|1] ""  X
 SG_ VCRIGHT_hvacPanelFloorSplitRow1 m2 : 8|8@1+ (0.4,0) [0|100] "%"  X
 SG_ VCRIGHT_cabinTempThs m3 : 8|8@1+ (0.5,-40) [-40|80] "degC"  X
 SG_ VCRIGHT_tempEvapAdjustmentLeft m1 : 8|7@1+ (0.1,0) [0|9] "degC"  X
 SG_ VCRIGHT_hvacRHBleedCalibrated m4 : 7|1@1+ (1,0) [0|1] ""  X
 SG_ VCRIGHT_hvacActuatorsCalibrated m4 : 4|1@1+ (1,0) [0|1] ""  X
 SG_ VCRIGHT_wattsDemandEvapFeedback m0 : 3|9@1- (20,0) [-5000|5000] "W"  X
 SG_ VCRIGHT_hvacLHBleedCalibrated m4 : 3|1@1+ (1,0) [0|1] ""  X
 SG_ VCRIGHT_debugThermal10HzIndex M : 0|3@1+ (1,0) [0|5] ""  X

BO_ 1344 SCCM_alertLog: 8 VEH
 SG_ SCCM_a021_adcValue6 m21 : 56|8@1+ (1,0) [0|255] "-"  gtw
 SG_ SCCM_a023_adcValue6 m23 : 56|8@1+ (1,0) [0|255] "-"  gtw
 SG_ SCCM_a024_adcValue6 m24 : 56|8@1+ (1,0) [0|255] "-"  gtw
 SG_ SCCM_a022_adcValue6 m22 : 56|8@1+ (1,0) [0|255] "-"  gtw
 SG_ SCCM_a024_adcValue5 m24 : 48|8@1+ (1,0) [0|255] "-"  gtw
 SG_ SCCM_a012_adcValue2 m12 : 48|8@1+ (1,0) [0|255] "-"  gtw
 SG_ SCCM_a029_adcValue2 m29 : 48|8@1+ (1,0) [0|255] "-"  gtw
 SG_ SCCM_a028_adcValue2 m28 : 48|8@1+ (1,0) [0|255] "-"  gtw
 SG_ SCCM_a022_adcValue5 m22 : 48|8@1+ (1,0) [0|255] "-"  gtw
 SG_ SCCM_a007_adcValue2 m7 : 48|8@1+ (1,0) [0|255] "-"  gtw
 SG_ SCCM_a009_adcValue2 m9 : 48|8@1+ (1,0) [0|255] "-"  gtw
 SG_ SCCM_a010_adcValue2 m10 : 48|8@1+ (1,0) [0|255] "-"  gtw
 SG_ SCCM_a023_adcValue5 m23 : 48|8@1+ (1,0) [0|255] "-"  gtw
 SG_ SCCM_a011_adcValue2 m11 : 48|8@1+ (1,0) [0|255] "-"  gtw
 SG_ SCCM_a008_adcValue2 m8 : 48|8@1+ (1,0) [0|255] "-"  gtw
 SG_ SCCM_a027_adcValue2 m27 : 48|8@1+ (1,0) [0|255] "-"  gtw
 SG_ SCCM_a026_adcValue2 m26 : 48|8@1+ (1,0) [0|255] "-"  gtw
 SG_ SCCM_a021_adcValue5 m21 : 48|8@1+ (1,0) [0|255] "-"  gtw
 SG_ SCCM_a017_svError m17 : 44|16@1+ (1,0) [0|65535] "-"  gtw
 SG_ SCCM_a011_adcValue1 m11 : 40|8@1+ (1,0) [0|255] "-"  gtw
 SG_ SCCM_a008_adcValue1 m8 : 40|8@1+ (1,0) [0|255] "-"  gtw
 SG_ SCCM_a024_adcValue4 m24 : 40|8@1+ (1,0) [0|255] "-"  gtw
 SG_ SCCM_a010_adcValue1 m10 : 40|8@1+ (1,0) [0|255] "-"  gtw
 SG_ SCCM_a009_adcValue1 m9 : 40|8@1+ (1,0) [0|255] "-"  gtw
 SG_ SCCM_a026_adcValue1 m26 : 40|8@1+ (1,0) [0|255] "-"  gtw
 SG_ SCCM_a023_adcValue4 m23 : 40|8@1+ (1,0) [0|255] "-"  gtw
 SG_ SCCM_a003_adcValue m3 : 40|8@1+ (1,0) [0|255] "-"  gtw
 SG_ SCCM_a028_adcValue1 m28 : 40|8@1+ (1,0) [0|255] "-"  gtw
 SG_ SCCM_a027_adcValue1 m27 : 40|8@1+ (1,0) [0|255] "-"  gtw
 SG_ SCCM_a022_adcValue4 m22 : 40|8@1+ (1,0) [0|255] "-"  gtw
 SG_ SCCM_a004_adcValue m4 : 40|8@1+ (1,0) [0|255] "-"  gtw
 SG_ SCCM_a012_adcValue1 m12 : 40|8@1+ (1,0) [0|255] "-"  gtw
 SG_ SCCM_a029_adcValue1 m29 : 40|8@1+ (1,0) [0|255] "-"  gtw
 SG_ SCCM_a021_adcValue4 m21 : 40|8@1+ (1,0) [0|255] "-"  gtw
 SG_ SCCM_a017_subStackHardLimitTest m17 : 40|4@1+ (1,0) [0|15] "-"  gtw
 SG_ SCCM_a005_adcValue m5 : 40|8@1+ (1,0) [0|255] "-"  gtw
 SG_ SCCM_a007_adcValue1 m7 : 40|8@1+ (1,0) [0|255] "-"  gtw
 SG_ SCCM_a006_adcValue m6 : 40|8@1+ (1,0) [0|255] "-"  gtw
 SG_ SCCM_a017_subRomTest m17 : 36|4@1+ (1,0) [0|15] "-"  gtw
 SG_ SCCM_a022_adcValue3 m22 : 32|8@1+ (1,0) [0|255] "-"  gtw
 SG_ SCCM_a027_errorPosition m27 : 32|8@1+ (1,0) [0|255] "-"  gtw
 SG_ SCCM_a015_intMemIndex m15 : 32|8@1+ (1,0) [0|255] "-"  gtw
 SG_ SCCM_a005_errorPosition m5 : 32|8@1+ (1,0) [0|255] "-"  gtw
 SG_ SCCM_a023_adcValue3 m23 : 32|8@1+ (1,0) [0|255] "-"  gtw
 SG_ SCCM_a003_errorPosition m3 : 32|8@1+ (1,0) [0|255] "-"  gtw
 SG_ SCCM_a004_errorPosition m4 : 32|8@1+ (1,0) [0|255] "-"  gtw
 SG_ SCCM_a026_errorPosition m26 : 32|8@1+ (1,0) [0|255] "-"  gtw
 SG_ SCCM_a010_errorPosition m10 : 32|8@1+ (1,0) [0|255] "-"  gtw
 SG_ SCCM_a024_adcValue3 m24 : 32|8@1+ (1,0) [0|255] "-"  gtw
 SG_ SCCM_a009_errorPosition m9 : 32|8@1+ (1,0) [0|255] "-"  gtw
 SG_ SCCM_a016_subAdcTest m16 : 32|4@1+ (1,0) [0|15] "-"  gtw
 SG_ SCCM_a007_errorPosition m7 : 32|8@1+ (1,0) [0|255] "-"  gtw
 SG_ SCCM_a008_errorPosition m8 : 32|8@1+ (1,0) [0|255] "-"  gtw
 SG_ SCCM_a011_errorPosition m11 : 32|8@1+ (1,0) [0|255] "-"  gtw
 SG_ SCCM_a006_errorPosition m6 : 32|8@1+ (1,0) [0|255] "-"  gtw
 SG_ SCCM_a012_errorPosition m12 : 32|8@1+ (1,0) [0|255] "-"  gtw
 SG_ SCCM_a029_errorPosition m29 : 32|8@1+ (1,0) [0|255] "-"  gtw
 SG_ SCCM_a017_subRamTest m17 : 32|4@1+ (1,0) [0|15] "-"  gtw
 SG_ SCCM_a021_adcValue3 m21 : 32|8@1+ (1,0) [0|255] "-"  gtw
 SG_ SCCM_a028_errorPosition m28 : 32|8@1+ (1,0) [0|255] "-"  gtw
 SG_ SCCM_a017_mainDataFlashTest m17 : 28|4@1+ (1,0) [0|15] "-"  gtw
 SG_ SCCM_a016_subCpuTest m16 : 28|4@1+ (1,0) [0|15] "-"  gtw
 SG_ SCCM_a016_wdtTest m16 : 24|4@1+ (1,0) [0|15] "-"  gtw
 SG_ SCCM_a003_rawPosition m3 : 24|8@1+ (1,0) [0|255] "-"  gtw
 SG_ SCCM_a023_adcValue2 m23 : 24|8@1+ (1,0) [0|255] "-"  gtw
 SG_ SCCM_a010_rawPosition m10 : 24|8@1+ (1,0) [0|255] "-"  gtw
 SG_ SCCM_a017_stackHardLimitTest m17 : 24|4@1+ (1,0) [0|15] "-"  gtw
 SG_ SCCM_a009_rawPosition m9 : 24|8@1+ (1,0) [0|255] "-"  gtw
 SG_ SCCM_a022_adcValue2 m22 : 24|8@1+ (1,0) [0|255] "-"  gtw
 SG_ SCCM_a011_rawPosition m11 : 24|8@1+ (1,0) [0|255] "-"  gtw
 SG_ SCCM_a008_rawPosition m8 : 24|8@1+ (1,0) [0|255] "-"  gtw
 SG_ SCCM_a005_rawPosition m5 : 24|8@1+ (1,0) [0|255] "-"  gtw
 SG_ SCCM_a027_rawPosition m27 : 24|8@1+ (1,0) [0|255] "-"  gtw
 SG_ SCCM_a012_rawPosition m12 : 24|8@1+ (1,0) [0|255] "-"  gtw
 SG_ SCCM_a029_rawPosition m29 : 24|8@1+ (1,0) [0|255] "-"  gtw
 SG_ SCCM_a026_rawPosition m26 : 24|8@1+ (1,0) [0|255] "-"  gtw
 SG_ SCCM_a024_adcValue2 m24 : 24|8@1+ (1,0) [0|255] "-"  gtw
 SG_ SCCM_a004_rawPosition m4 : 24|8@1+ (1,0) [0|255] "-"  gtw
 SG_ SCCM_a021_adcValue2 m21 : 24|8@1+ (1,0) [0|255] "-"  gtw
 SG_ SCCM_a028_rawPosition m28 : 24|8@1+ (1,0) [0|255] "-"  gtw
 SG_ SCCM_a007_rawPosition m7 : 24|8@1+ (1,0) [0|255] "-"  gtw
 SG_ SCCM_a015_intSubIndex m15 : 24|8@1+ (1,0) [0|255] "-"  gtw
 SG_ SCCM_a006_rawPosition m6 : 24|8@1+ (1,0) [0|255] "-"  gtw
 SG_ SCCM_a017_mainRomTest m17 : 20|4@1+ (1,0) [0|15] "-"  gtw
 SG_ SCCM_a016_mainCpuTest m16 : 20|4@1+ (1,0) [0|15] "-"  gtw
 SG_ SCCM_a006_debouncePosition m6 : 16|8@1+ (1,0) [0|255] "-"  gtw
 SG_ SCCM_a019_internalSASState m19 : 16|8@1+ (1,0) [0|255] "-"  gtw
 SG_ SCCM_a021_adcValue1 m21 : 16|8@1+ (1,0) [0|255] "-"  gtw
 SG_ SCCM_a015_intMainIndex m15 : 16|8@1+ (1,0) [0|255] "-"  gtw
 SG_ SCCM_a028_debouncePosition m28 : 16|8@1+ (1,0) [0|255] "-"  gtw
 SG_ SCCM_a025_taskState m25 : 16|16@1+ (1,0) [0|65535] "-"  gtw
 SG_ SCCM_a027_debouncePosition m27 : 16|8@1+ (1,0) [0|255] "-"  gtw
 SG_ SCCM_a005_debouncePosition m5 : 16|8@1+ (1,0) [0|255] "-"  gtw
 SG_ SCCM_a018_internalSASState m18 : 16|8@1+ (1,0) [0|255] "-"  gtw
 SG_ SCCM_a020_internalSASState m20 : 16|8@1+ (1,0) [0|255] "-"  gtw
 SG_ SCCM_a003_debouncePosition m3 : 16|8@1+ (1,0) [0|255] "-"  gtw
 SG_ SCCM_a010_debouncePosition m10 : 16|8@1+ (1,0) [0|255] "-"  gtw
 SG_ SCCM_a009_debouncePosition m9 : 16|8@1+ (1,0) [0|255] "-"  gtw
 SG_ SCCM_a016_mainAdcTest m16 : 16|4@1+ (1,0) [0|15] "-"  gtw
 SG_ SCCM_a004_debouncePosition m4 : 16|8@1+ (1,0) [0|255] "-"  gtw
 SG_ SCCM_a026_debouncePosition m26 : 16|8@1+ (1,0) [0|255] "-"  gtw
 SG_ SCCM_a022_adcValue1 m22 : 16|8@1+ (1,0) [0|255] "-"  gtw
 SG_ SCCM_a014_voltage m14 : 16|8@1+ (1,0) [0|255] "-"  gtw
 SG_ SCCM_a007_debouncePosition m7 : 16|8@1+ (1,0) [0|255] "-"  gtw
 SG_ SCCM_a024_adcValue1 m24 : 16|8@1+ (1,0) [0|255] "-"  gtw
 SG_ SCCM_a023_adcValue1 m23 : 16|8@1+ (1,0) [0|255] "-"  gtw
 SG_ SCCM_a017_mainRamTest m17 : 16|4@1+ (1,0) [0|15] "-"  gtw
 SG_ SCCM_a011_debouncePosition m11 : 16|8@1+ (1,0) [0|255] "-"  gtw
 SG_ SCCM_a013_voltage m13 : 16|8@1+ (1,0) [0|255] "-"  gtw
 SG_ SCCM_a008_debouncePosition m8 : 16|8@1+ (1,0) [0|255] "-"  gtw
 SG_ SCCM_a012_debouncePosition m12 : 16|8@1+ (1,0) [0|255] "-"  gtw
 SG_ SCCM_a029_debouncePosition m29 : 16|8@1+ (1,0) [0|255] "-"  gtw
 SG_ SCCM_alertState : 15|1@1+ (1,0) [0|1] ""  gtw
 SG_ SCCM_alertID M : 0|5@1+ (1,0) [0|29] ""  gtw

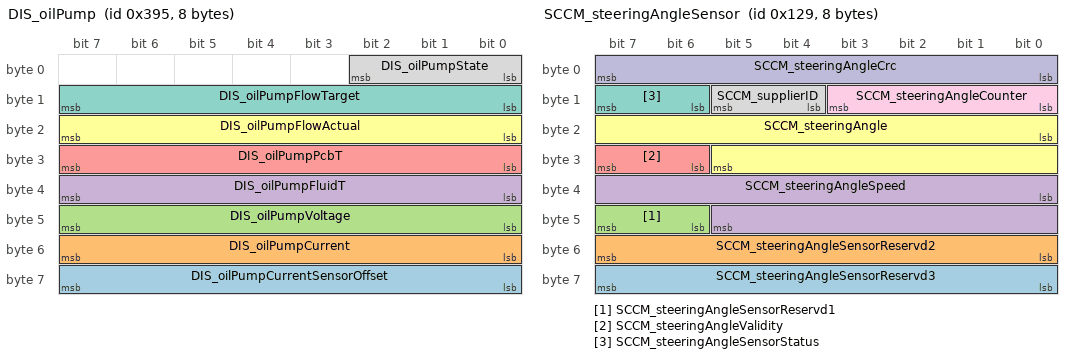
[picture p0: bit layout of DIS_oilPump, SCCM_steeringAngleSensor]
BO_ 917 DIS_oilPump: 8 VEH
 SG_ DIS_oilPumpCurrentSensorOffset : 56|8@1+ (0.005,0) [0|1.27] "A"  gtw
 SG_ DIS_oilPumpCurrent : 48|8@1+ (0.1,0) [0|25.4] "A"  gtw
 SG_ DIS_oilPumpVoltage : 40|8@1+ (0.1,0) [0|25.4] "V"  gtw
 SG_ DIS_oilPumpFluidT : 32|8@1+ (1,-40) [-40|214] "DegC"  gtw
 SG_ DIS_oilPumpPcbT : 24|8@1+ (1,-40) [-40|214] "DegC"  gtw
 SG_ DIS_oilPumpFlowActual : 16|8@1+ (0.06,0) [0|15] "LPM"  gtw
 SG_ DIS_oilPumpFlowTarget : 8|8@1+ (0.06,0) [0|15] "LPM"  gtw
 SG_ DIS_oilPumpState : 0|3@1+ (1,0) [0|7] ""  gtw

BO_ 297 SCCM_steeringAngleSensor: 8 VEH
 SG_ SCCM_steeringAngleSensorReservd3 : 56|8@1+ (1,0) [0|255] ""  X
 SG_ SCCM_steeringAngleSensorReservd2 : 48|8@1+ (1,0) [0|255] ""  X
 SG_ SCCM_steeringAngleSensorReservd1 : 46|2@1+ (1,0) [0|3] ""  X
 SG_ SCCM_steeringAngleSpeed : 32|14@1+ (0.5,-4096) [-4096|4095.5] "deg/s"  das
 SG_ SCCM_steeringAngleValidity : 30|2@1+ (1,0) [0|3] ""  gtw
 SG_ SCCM_steeringAngle : 16|14@1+ (0.1,-819.2) [-819.2|819] "deg"  aps
 SG_ SCCM_steeringAngleSensorStatus : 14|2@1+ (1,0) [0|3] ""  aps
 SG_ SCCM_supplierID : 12|2@1+ (1,0) [0|3] ""  gtw
 SG_ SCCM_steeringAngleCounter : 8|4@1+ (1,0) [0|15] ""  gtw
 SG_ SCCM_steeringAngleCrc : 0|8@1+ (1,0) [0|255] ""  gtw

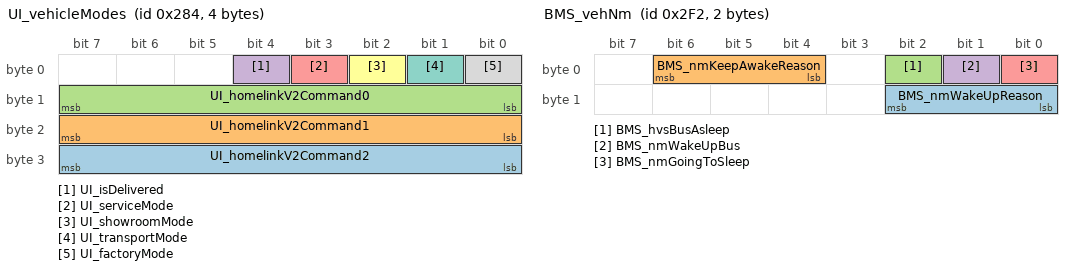
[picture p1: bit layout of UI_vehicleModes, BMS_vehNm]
BO_ 644 UI_vehicleModes: 4 VEH
 SG_ UI_homelinkV2Command2 : 24|8@1+ (1,0) [0|255] ""  vcfront
 SG_ UI_homelinkV2Command1 : 16|8@1+ (1,0) [0|255] ""  vcfront
 SG_ UI_homelinkV2Command0 : 8|8@1+ (1,0) [0|255] ""  vcfront
 SG_ UI_isDelivered : 4|1@1+ (1,0) [0|1] ""  vcright
 SG_ UI_serviceMode : 3|1@1+ (1,0) [0|1] ""  di
 SG_ UI_showroomMode : 2|1@1+ (1,0) [0|1] ""  vcfront
 SG_ UI_transportMode : 1|1@1+ (1,0) [0|1] ""  vcfront
 SG_ UI_factoryMode : 0|1@1+ (1,0) [0|1] ""  vcfront

BO_ 754 BMS_vehNm: 2 VEH
 SG_ BMS_nmWakeUpReason : 8|3@1+ (1,0) [0|5] ""  gtw
 SG_ BMS_nmKeepAwakeReason : 4|3@1+ (1,0) [0|6] ""  gtw
 SG_ BMS_hvsBusAsleep : 2|1@1+ (1,0) [0|1] ""  gtw
 SG_ BMS_nmWakeUpBus : 1|1@1+ (1,0) [0|1] ""  X
 SG_ BMS_nmGoingToSleep : 0|1@1+ (1,0) [0|1] ""  X

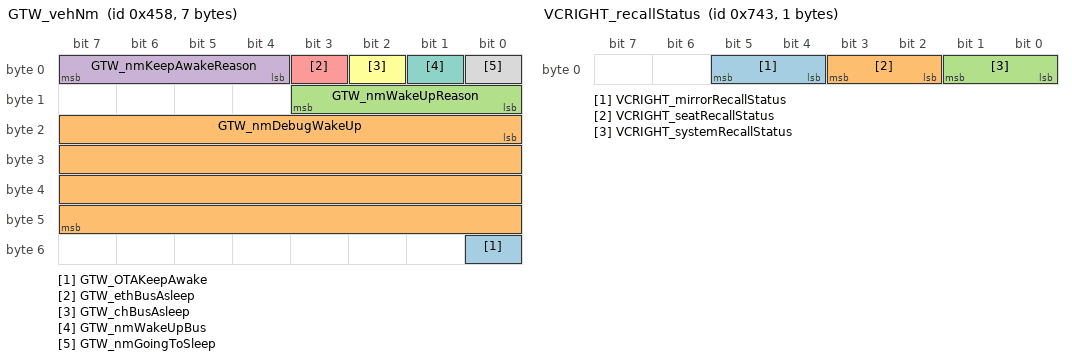
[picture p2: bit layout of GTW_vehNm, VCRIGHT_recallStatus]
BO_ 1112 GTW_vehNm: 7 VEH
 SG_ GTW_OTAKeepAwake : 48|1@1+ (1,0) [0|1] ""  vcfront
 SG_ GTW_nmDebugWakeUp : 16|32@1+ (1,0) [0|4294967295] ""  X
 SG_ GTW_nmWakeUpReason : 8|4@1+ (1,0) [0|8] ""  X
 SG_ GTW_nmKeepAwakeReason : 4|4@1+ (1,0) [0|15] ""  vcfront
 SG_ GTW_ethBusAsleep : 3|1@1+ (1,0) [0|1] ""  vcfront
 SG_ GTW_chBusAsleep : 2|1@1+ (1,0) [0|1] ""  vcfront
 SG_ GTW_nmWakeUpBus : 1|1@1+ (1,0) [0|1] ""  X
 SG_ GTW_nmGoingToSleep : 0|1@1+ (1,0) [0|1] ""  X

BO_ 1835 XCP_tasRequest: 8 VEH
 SG_ XCP_tasRequest : 7|64@0+ (1,0) [0|18446744073709551615] ""  X

BO_ 1558 DI_udsResponse: 8 VEH
 SG_ DI_udsResponseData : 7|64@0+ (1,0) [0|18446744073709551615] ""  gtw

BO_ 1892 VCFRONT_xcpResponse: 8 VEH
 SG_ VCFRONT_xcpResponseData : 0|64@1+ (1,0) [0|18446744073709551615] ""  X

BO_ 705 VCFRONT_logging10Hz: 8 VEH
 SG_ VCFRONT_pumpsWake m0 : 63|1@1+ (1,0) [0|1] ""  gtw
 SG_ VCFRONT_usingSimulatedAmbTemp m3 : 63|1@1+ (1,0) [0|1] ""  gtw
 SG_ VCFRONT_usingSimulatedDischTemp m3 : 62|1@1+ (1,0) [0|1] ""  gtw
 SG_ VCFRONT_pumpPowertrainPowerOn m0 : 62|1@1+ (1,0) [0|1] ""  gtw
 SG_ VCFRONT_pumpBatteryPowerOn m0 : 61|1@1+ (1,0) [0|1] ""  gtw
 SG_ VCFRONT_isOnlySuctTempNotReady m3 : 61|1@1+ (1,0) [0|1] ""  gtw
 SG_ VCFRONT_pumpPowertrainEnabled m0 : 60|1@1+ (1,0) [0|1] ""  gtw
 SG_ VCFRONT_pumpBatteryEnabled m0 : 59|1@1+ (1,0) [0|1] ""  gtw
 SG_ VCFRONT_pumpPowertrainInitd m0 : 58|1@1+ (1,0) [0|1] ""  gtw
 SG_ VCFRONT_pumpBatteryInitd m0 : 57|1@1+ (1,0) [0|1] ""  gtw
 SG_ VCFRONT_radiatorFanDemandLimit m1 : 56|7@1+ (1,0) [0|100] "%"  gtw
 SG_ VCFRONT_louverDemand m5 : 56|7@1+ (1,0) [0|100] "%"  gtw
 SG_ VCFRONT_radiatorFanDemandLimited m1 : 55|1@1+ (1,0) [0|1] ""  gtw
 SG_ VCFRONT_fiveWayValveISense m2 : 53|6@1+ (0.01,0) [0|0.63] "A"  X
 SG_ VCFRONT_tempDischargeSimulated m3 : 50|11@1+ (0.125,-40) [-40|150] "degC"  gtw
 SG_ VCFRONT_pumpPowertrainOutVoltage m0 : 50|7@1+ (0.2,0) [0|20] "V"  gtw
 SG_ VCFRONT_thmlFanSpiError m3 : 49|1@1+ (1,0) [0|1] ""  X
 SG_ VCFRONT_radiatorFanPhaseIMax m1 : 48|7@1+ (0.25,0) [5|35] "A"  gtw
 SG_ VCFRONT_pumpPtSpiError m3 : 48|1@1+ (1,0) [0|1] ""  X
 SG_ VCFRONT_pumpBatSpiError m3 : 47|1@1+ (1,0) [0|1] ""  X
 SG_ VCFRONT_refrigerantValvesClosed m4 : 46|1@1+ (1,0) [0|1] ""  gtw
 SG_ VCFRONT_fiveWayValveAngleTravel m2 : 43|10@1+ (5,0) [0|5000] "degrees"  gtw
 SG_ VCFRONT_pumpBatteryOutVoltage m0 : 43|7@1+ (0.2,0) [0|20] "V"  gtw
 SG_ VCFRONT_radiatorFanPhaseCurrent m1 : 40|8@1+ (0.25,-10) [-10|50] "A"  gtw
 SG_ VCFRONT_compRampRateUpMax m4 : 40|6@1+ (0.1,0) [0|6] "%/s"  gtw
 SG_ VCFRONT_compLimitTempDischargeSi m4 : 38|1@1+ (1,0) [0|1] ""  gtw
 SG_ VCFRONT_radiatorFanPowerOn m1 : 38|1@1+ (1,0) [0|1] ""  gtw
 SG_ VCFRONT_radiatorFanEnabled m1 : 37|1@1+ (1,0) [0|1] ""  gtw
 SG_ VCFRONT_compStandbyRefrigNotOk m4 : 37|1@1+ (1,0) [0|1] ""  gtw
 SG_ VCFRONT_compStandbyLowDischPress m4 : 36|1@1+ (1,0) [0|1] ""  gtw
 SG_ VCFRONT_radiatorFanInitd m1 : 36|1@1+ (1,0) [0|1] ""  gtw
 SG_ VCFRONT_compStandbyLowAmbient m4 : 35|1@1+ (1,0) [0|1] ""  gtw
 SG_ VCFRONT_fiveWayValveDuty m2 : 35|8@1- (1,0) [-100|100] "%"  gtw
 SG_ VCFRONT_compStandbyHVNotReady m4 : 34|1@1+ (1,0) [0|1] ""  gtw
 SG_ VCFRONT_compStandbyCommunication m4 : 33|1@1+ (1,0) [0|1] ""  gtw
 SG_ VCFRONT_pumpPowertrainRPMTarget m0 : 33|10@1+ (10,0) [0|10000] "rpm"  gtw
 SG_ VCFRONT_fiveWayValveState m2 : 33|2@1+ (1,0) [0|3] ""  gtw
 SG_ VCFRONT_exvPrechillActive m5 : 32|1@1+ (1,0) [0|1] ""  gtw
 SG_ VCFRONT_compStandbySelfNotReady m4 : 32|1@1+ (1,0) [0|1] ""  gtw
 SG_ VCFRONT_compLimitDeadband m4 : 31|1@1+ (1,0) [0|1] ""  gtw
 SG_ VCFRONT_exvIsFlooding m5 : 31|1@1+ (1,0) [0|1] ""  gtw
 SG_ VCFRONT_compLimitScrollSepRamp m4 : 30|1@1+ (1,0) [0|1] ""  gtw
 SG_ VCFRONT_compLimitNvh m4 : 29|1@1+ (1,0) [0|1] ""  gtw
 SG_ VCFRONT_compLimitScrollSepRegion m4 : 28|1@1+ (1,0) [0|1] ""  gtw
 SG_ VCFRONT_compLimitTempDischargeHi m4 : 27|1@1+ (1,0) [0|1] ""  gtw
 SG_ VCFRONT_compLimitPresDischargeHi m4 : 26|1@1+ (1,0) [0|1] ""  gtw
 SG_ VCFRONT_exvFlow m5 : 21|10@1+ (0.1,0) [0|100] "%"  gtw
 SG_ VCFRONT_fiveWayValveAngleTarget m2 : 16|10@1+ (0.25,-10) [-10|180] "degrees"  gtw
 SG_ VCFRONT_radiatorFanRPMTarget m1 : 16|10@1+ (10,0) [0|10000] "rpm"  gtw
 SG_ VCFRONT_pumpBatteryRPMTarget m0 : 13|10@1+ (10,0) [0|10000] "rpm"  gtw
 SG_ VCFRONT_radiatorFanOutVoltage m1 : 8|7@1+ (0.2,0) [0|20] "V"  gtw
 SG_ VCFRONT_fiveWayValveAngleActual m2 : 6|10@1+ (0.25,-70) [-70|180] "degrees"  gtw
 SG_ VCFRONT_fiveWayValveModeWrong m2 : 5|1@1+ (1,0) [0|1] ""  gtw
 SG_ VCFRONT_coolantTempBasedMode m2 : 4|1@1+ (1,0) [0|1] ""  gtw
 SG_ VCFRONT_exvMotorState m5 : 3|4@1+ (1,0) [0|11] ""  dbg
 SG_ VCFRONT_refrigerantHasBeenFilled m4 : 3|1@1+ (1,0) [0|1] ""  gtw
 SG_ VCFRONT_logging10HzIndex M : 0|3@1+ (1,0) [0|6] ""  X

BO_ 994 VCLEFT_lightStatus: 6 VEH
 SG_ VCLEFT_rearRideHeight : 36|8@1- (1,0) [-127|127] "mm"  vcfront
 SG_ VCLEFT_frontRideHeight : 28|8@1- (1,0) [-127|127] "mm"  vcfront
 SG_ VCLEFT_fogTrailerLightStatus : 26|2@1+ (1,0) [0|3] ""  X
 SG_ VCLEFT_tailTrailerLightStatus : 24|2@1+ (1,0) [0|3] ""  X
 SG_ VCLEFT_brakeTrailerLightStatus : 22|2@1+ (1,0) [0|3] ""  X
 SG_ VCLEFT_rightTrnTrailerLightStatu : 20|2@1+ (1,0) [0|3] ""  X
 SG_ VCLEFT_leftTurnTrailerLightStatu : 18|2@1+ (1,0) [0|3] ""  X
 SG_ VCLEFT_RRMapLightSwitchPressed : 17|1@1+ (1,0) [0|1] ""  gtw
 SG_ VCLEFT_RLMapLightSwitchPressed : 16|1@1+ (1,0) [0|1] ""  gtw
 SG_ VCLEFT_FRMapLightSwitchPressed : 15|1@1+ (1,0) [0|1] ""  gtw
 SG_ VCLEFT_FLMapLightSwitchPressed : 14|1@1+ (1,0) [0|1] ""  gtw
 SG_ VCLEFT_RRMapLightStatus : 12|2@1+ (1,0) [0|3] ""  gtw
 SG_ VCLEFT_RLMapLightStatus : 10|2@1+ (1,0) [0|3] ""  gtw
 SG_ VCLEFT_FRMapLightStatus : 8|2@1+ (1,0) [0|3] ""  gtw
 SG_ VCLEFT_FLMapLightStatus : 6|2@1+ (1,0) [0|3] ""  gtw
 SG_ VCLEFT_turnSignalStatus : 4|2@1+ (1,0) [0|3] ""  das
 SG_ VCLEFT_tailLightStatus : 2|2@1+ (1,0) [0|3] ""  gtw
 SG_ VCLEFT_brakeLightStatus : 0|2@1+ (1,0) [0|3] ""  gtw

BO_ 1575 EPBR_udsResponse: 8 VEH
 SG_ EPBR_udsResponseData_L : 39|32@0+ (1,0) [0|4294967295] ""  gtw
 SG_ EPBR_udsResponseData_H : 7|32@0+ (1,0) [0|4294967295] ""  gtw

BO_ 1859 VCRIGHT_recallStatus: 1 VEH
 SG_ VCRIGHT_mirrorRecallStatus : 4|2@1+ (1,0) [0|3] ""  gtw
 SG_ VCRIGHT_seatRecallStatus : 2|2@1+ (1,0) [0|3] ""  gtw
 SG_ VCRIGHT_systemRecallStatus : 0|2@1+ (1,0) [0|3] ""  gtw

BO_ 258 VCLEFT_doorStatus: 8 VEH
 SG_ VCLEFT_frontHandlePulledPersist : 62|1@1+ (1,0) [0|1] ""  gtw
 SG_ VCLEFT_mirrorDipped : 61|1@1+ (1,0) [0|1] ""  X
 SG_ VCLEFT_mirrorHeatState : 58|3@1+ (1,0) [0|4] ""  X
 SG_ VCLEFT_mirrorRecallState : 55|3@1+ (1,0) [0|5] ""  gtw
 SG_ VCLEFT_mirrorFoldState : 52|3@1+ (1,0) [0|4] ""  gtw
 SG_ VCLEFT_mirrorState : 49|3@1+ (1,0) [0|4] ""  gtw
 SG_ VCLEFT_mirrorTiltYPosition : 41|8@1+ (0.02,0) [0|5] "V"  gtw
 SG_ VCLEFT_mirrorTiltXPosition : 33|8@1+ (0.02,0) [0|5] "V"  gtw
 SG_ VCLEFT_rearIntSwitchPressed : 32|1@1+ (1,0) [0|1] ""  aps
 SG_ VCLEFT_frontIntSwitchPressed : 31|1@1+ (1,0) [0|1] ""  aps
 SG_ VCLEFT_rearHandlePWM : 24|7@1+ (1,0) [0|100] "%"  X
 SG_ VCLEFT_frontHandlePWM : 16|7@1+ (1,0) [0|100] "%"  X
 SG_ VCLEFT_rearRelActuatorSwitch : 13|1@1+ (1,0) [0|1] ""  gtw
 SG_ VCLEFT_frontRelActuatorSwitch : 12|1@1+ (1,0) [0|1] ""  gtw
 SG_ VCLEFT_rearHandlePulled : 11|1@1+ (1,0) [0|1] ""  aps
 SG_ VCLEFT_frontHandlePulled : 10|1@1+ (1,0) [0|1] ""  aps
 SG_ VCLEFT_rearLatchSwitch : 9|1@1+ (1,0) [0|1] ""  gtw
 SG_ VCLEFT_frontLatchSwitch : 8|1@1+ (1,0) [0|1] ""  gtw
 SG_ VCLEFT_rearLatchStatus : 4|4@1+ (1,0) [0|8] ""  aps
 SG_ VCLEFT_frontLatchStatus : 0|4@1+ (1,0) [0|8] ""  aps

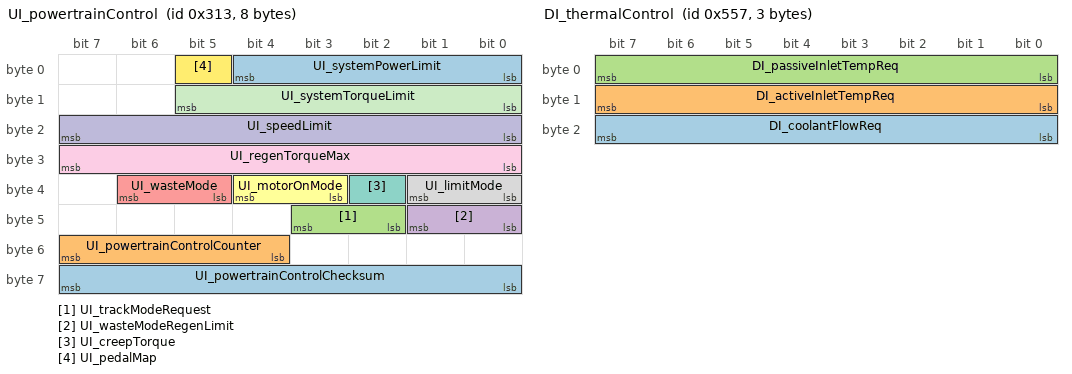
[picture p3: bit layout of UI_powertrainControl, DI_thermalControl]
BO_ 787 UI_powertrainControl: 8 VEH
 SG_ UI_powertrainControlChecksum : 56|8@1+ (1,0) [0|255] ""  X
 SG_ UI_powertrainControlCounter : 52|4@1+ (1,0) [0|15] ""  X
 SG_ UI_trackModeRequest : 42|2@1+ (1,0) [0|2] ""  bms
 SG_ UI_wasteModeRegenLimit : 40|2@1+ (1,0) [0|3] ""  di
 SG_ UI_wasteMode : 37|2@1+ (1,0) [0|2] ""  di
 SG_ UI_motorOnMode : 35|2@1+ (1,0) [0|2] ""  di
 SG_ UI_creepTorque : 34|1@1+ (1,0) [0|1] ""  di
 SG_ UI_limitMode : 32|2@1+ (1,0) [0|2] ""  di
 SG_ UI_regenTorqueMax : 24|8@1+ (0.5,0) [0|100] "%"  di
 SG_ UI_speedLimit : 16|8@1+ (1,50) [50|285] "kph"  di
 SG_ UI_systemTorqueLimit : 8|6@1+ (100,4000) [4000|13450] "Nm"  di
 SG_ UI_pedalMap : 5|1@1+ (1,0) [0|1] ""  di
 SG_ UI_systemPowerLimit : 0|5@1+ (20,20) [20|640] "kW"  di

BO_ 880 SCS_alertMatrix2: 8 VEH
 SG_ SCS_a128_unused128 : 63|1@1+ (1,0) [0|1] ""  gtw
 SG_ SCS_a127_unused127 : 62|1@1+ (1,0) [0|1] ""  gtw
 SG_ SCS_a126_unused126 : 61|1@1+ (1,0) [0|1] ""  gtw
 SG_ SCS_a125_unused125 : 60|1@1+ (1,0) [0|1] ""  gtw
 SG_ SCS_a124_unused124 : 59|1@1+ (1,0) [0|1] ""  gtw
 SG_ SCS_a123_unused123 : 58|1@1+ (1,0) [0|1] ""  gtw
 SG_ SCS_a122_unused122 : 57|1@1+ (1,0) [0|1] ""  gtw
 SG_ SCS_a121_unused121 : 56|1@1+ (1,0) [0|1] ""  gtw
 SG_ SCS_a120_unused120 : 55|1@1+ (1,0) [0|1] ""  gtw
 SG_ SCS_a119_unused119 : 54|1@1+ (1,0) [0|1] ""  gtw
 SG_ SCS_a118_unused118 : 53|1@1+ (1,0) [0|1] ""  gtw
 SG_ SCS_a117_unused117 : 52|1@1+ (1,0) [0|1] ""  gtw
 SG_ SCS_a116_unused116 : 51|1@1+ (1,0) [0|1] ""  gtw
 SG_ SCS_a115_unused115 : 50|1@1+ (1,0) [0|1] ""  gtw
 SG_ SCS_a114_unused114 : 49|1@1+ (1,0) [0|1] ""  gtw
 SG_ SCS_a113_unused113 : 48|1@1+ (1,0) [0|1] ""  gtw
 SG_ SCS_a112_unused112 : 47|1@1+ (1,0) [0|1] ""  gtw
 SG_ SCS_a111_unused111 : 46|1@1+ (1,0) [0|1] ""  gtw
 SG_ SCS_a110_unused110 : 45|1@1+ (1,0) [0|1] ""  gtw
 SG_ SCS_a109_unused109 : 44|1@1+ (1,0) [0|1] ""  gtw
 SG_ SCS_a108_unused108 : 43|1@1+ (1,0) [0|1] ""  gtw
 SG_ SCS_a107_unused107 : 42|1@1+ (1,0) [0|1] ""  gtw
 SG_ SCS_a106_unused106 : 41|1@1+ (1,0) [0|1] ""  gtw
 SG_ SCS_a105_unused105 : 40|1@1+ (1,0) [0|1] ""  gtw
 SG_ SCS_a104_unused104 : 39|1@1+ (1,0) [0|1] ""  gtw
 SG_ SCS_a103_unused103 : 38|1@1+ (1,0) [0|1] ""  gtw
 SG_ SCS_a102_unused102 : 37|1@1+ (1,0) [0|1] ""  gtw
 SG_ SCS_a101_unused101 : 36|1@1+ (1,0) [0|1] ""  gtw
 SG_ SCS_a100_unused100 : 35|1@1+ (1,0) [0|1] ""  gtw
 SG_ SCS_a099_unused99 : 34|1@1+ (1,0) [0|1] ""  gtw
 SG_ SCS_a098_unused98 : 33|1@1+ (1,0) [0|1] ""  gtw
 SG_ SCS_a097_unused97 : 32|1@1+ (1,0) [0|1] ""  gtw
 SG_ SCS_a096_unused96 : 31|1@1+ (1,0) [0|1] ""  gtw
 SG_ SCS_a095_unused95 : 30|1@1+ (1,0) [0|1] ""  gtw
 SG_ SCS_a094_unused94 : 29|1@1+ (1,0) [0|1] ""  gtw
 SG_ SCS_a093_unused93 : 28|1@1+ (1,0) [0|1] ""  gtw
 SG_ SCS_a092_cabEnableDeasserted : 27|1@1+ (1,0) [0|1] ""  gtw
 SG_ SCS_a091_voltageRiseDetection : 26|1@1+ (1,0) [0|1] ""  gtw
 SG_ SCS_a090_negCordOT : 25|1@1+ (1,0) [0|1] ""  gtw
 SG_ SCS_a089_posCordOT : 24|1@1+ (1,0) [0|1] ""  gtw
 SG_ SCS_a088_negCordTempRationality : 23|1@1+ (1,0) [0|1] ""  gtw
 SG_ SCS_a087_posCordTempRationality : 22|1@1+ (1,0) [0|1] ""  gtw
 SG_ SCS_a086_lccResetDetected : 21|1@1+ (1,0) [0|1] ""  gtw
 SG_ SCS_a085_unused85 : 20|1@1+ (1,0) [0|1] ""  gtw
 SG_ SCS_a084_unused84 : 19|1@1+ (1,0) [0|1] ""  gtw
 SG_ SCS_a083_chargeCurrentLimited : 18|1@1+ (1,0) [0|1] ""  gtw
 SG_ SCS_a082_VbatUV : 17|1@1+ (1,0) [0|1] ""  gtw
 SG_ SCS_a081_rmsInputVoltageHigh : 16|1@1+ (1,0) [0|1] ""  gtw
 SG_ SCS_a080_lccFaulted : 15|1@1+ (1,0) [0|1] ""  gtw
 SG_ SCS_a079_unexpectedVbat : 14|1@1+ (1,0) [0|1] ""  gtw
 SG_ SCS_a078_voltageMatchTimeout : 13|1@1+ (1,0) [0|1] ""  gtw
 SG_ SCS_a077_unexpectedVbatBehavior : 12|1@1+ (1,0) [0|1] ""  gtw
 SG_ SCS_a076_bmsMIA : 11|1@1+ (1,0) [0|1] ""  gtw
 SG_ SCS_a075_leakageTestAbsDecayLow : 10|1@1+ (1,0) [0|1] ""  gtw
 SG_ SCS_a074_isoVDiffHi : 9|1@1+ (1,0) [0|1] ""  gtw
 SG_ SCS_a073_lccMIA : 8|1@1+ (1,0) [0|1] ""  gtw
 SG_ SCS_a072_gtwMIA : 7|1@1+ (1,0) [0|1] ""  gtw
 SG_ SCS_a071_chargerMIA : 6|1@1+ (1,0) [0|1] ""  gtw
 SG_ SCS_a070_vStageRationalityV2 : 5|1@1+ (1,0) [0|1] ""  gtw
 SG_ SCS_a069_vStageRationalityV1 : 4|1@1+ (1,0) [0|1] ""  gtw
 SG_ SCS_a068_vBatRationalityStage4 : 3|1@1+ (1,0) [0|1] ""  gtw
 SG_ SCS_a067_vBatRationalityStage3 : 2|1@1+ (1,0) [0|1] ""  gtw
 SG_ SCS_a066_vBatRationalityStage2 : 1|1@1+ (1,0) [0|1] ""  gtw
 SG_ SCS_a065_vBatRationalityStage1 : 0|1@1+ (1,0) [0|1] ""  gtw

BO_ 859 DI_alertMatrix4: 8 VEH
 SG_ DI_a244_mechanical3PS : 51|1@1+ (1,0) [0|1] ""  gtw
 SG_ DI_a243_ecuLogAvailable : 50|1@1+ (1,0) [0|1] ""  gtw
 SG_ DI_a242_rotorOffsetLearning : 49|1@1+ (1,0) [0|1] ""  gtw
 SG_ DI_a241_systemThermallyLimited : 48|1@1+ (1,0) [0|1] ""  gtw
 SG_ DI_a240_torqueSplitStuck : 47|1@1+ (1,0) [0|1] ""  gtw
 SG_ DI_a239_neutralRequestByPM : 46|1@1+ (1,0) [0|1] ""  gtw
 SG_ DI_a235_trackModeActive : 42|1@1+ (1,0) [0|1] ""  gtw
 SG_ DI_a234_pcsMIA : 41|1@1+ (1,0) [0|1] ""  gtw
 SG_ DI_a233_diMsgMissed : 40|1@1+ (1,0) [0|1] ""  gtw
 SG_ DI_a232_velocityEstimatorDegrade : 39|1@1+ (1,0) [0|1] ""  gtw
 SG_ DI_a231_ptcMIA : 38|1@1+ (1,0) [0|1] ""  gtw
 SG_ DI_a230_cmpMIA : 37|1@1+ (1,0) [0|1] ""  gtw
 SG_ DI_a229_batteryIsHeating : 36|1@1+ (1,0) [0|1] ""  gtw
 SG_ DI_a228_brakeTempEstUnavailable : 35|1@1+ (1,0) [0|1] ""  gtw
 SG_ DI_a227_contactorsNotClosed : 34|1@1+ (1,0) [0|1] ""  gtw
 SG_ DI_a226_sysStartConditionNotMet : 33|1@1+ (1,0) [0|1] ""  gtw
 SG_ DI_a225_tmpEstPlausibility : 32|1@1+ (1,0) [0|1] ""  gtw
 SG_ DI_a224_brakeOverTemp : 31|1@1+ (1,0) [0|1] ""  gtw
 SG_ DI_a223_tractionControlDisabled : 30|1@1+ (1,0) [0|1] ""  gtw
 SG_ DI_a222_vdcDisabled : 29|1@1+ (1,0) [0|1] ""  gtw
 SG_ DI_a221_vdcUndersteerdMzActive : 28|1@1+ (1,0) [0|1] ""  gtw
 SG_ DI_a220_vdcUndersteerDecelActive : 27|1@1+ (1,0) [0|1] ""  gtw
 SG_ DI_a219_vdcOversteerdMzActive : 26|1@1+ (1,0) [0|1] ""  gtw
 SG_ DI_a218_vdcOSPreControlActive : 25|1@1+ (1,0) [0|1] ""  gtw
 SG_ DI_a217_vdcOutputIrrational : 24|1@1+ (1,0) [0|1] ""  gtw
 SG_ DI_a216_vdcMBPAlmostTripped : 23|1@1+ (1,0) [0|1] ""  gtw
 SG_ DI_a215_velEstWheelSpeedNonCGRe : 22|1@1+ (1,0) [0|1] ""  gtw
 SG_ DI_a214_velEstWheelSpeedNonCGFr : 21|1@1+ (1,0) [0|1] ""  gtw
 SG_ DI_a213_velEstWheelSpeedCGRe : 20|1@1+ (1,0) [0|1] ""  gtw
 SG_ DI_a212_velEstWheelSpeedCGFr : 19|1@1+ (1,0) [0|1] ""  gtw
 SG_ DI_a211_vdcMotorSpeeds : 18|1@1+ (1,0) [0|1] ""  gtw
 SG_ DI_a210_vdcOtherControllerStates : 17|1@1+ (1,0) [0|1] ""  gtw
 SG_ DI_a209_vdcVehicleSpeed : 16|1@1+ (1,0) [0|1] ""  gtw
 SG_ DI_a208_vdcPowertrainTorqueRe : 15|1@1+ (1,0) [0|1] ""  gtw
 SG_ DI_a207_vdcPowertrainTorqueFr : 14|1@1+ (1,0) [0|1] ""  gtw
 SG_ DI_a206_vdcRcmVertical : 13|1@1+ (1,0) [0|1] ""  gtw
 SG_ DI_a205_vdcRcmLateral : 12|1@1+ (1,0) [0|1] ""  gtw
 SG_ DI_a204_vdcRcmLongitudinal : 11|1@1+ (1,0) [0|1] ""  gtw
 SG_ DI_a203_TCReducedByADD : 10|1@1+ (1,0) [0|1] ""  gtw
 SG_ DI_a202_excessHeatUnavailable : 9|1@1+ (1,0) [0|1] ""  gtw
 SG_ DI_a201_regenLimited : 8|1@1+ (1,0) [0|1] ""  gtw
 SG_ DI_a200_vdcModelBasedPlausibilit : 7|1@1+ (1,0) [0|1] ""  gtw
 SG_ DI_a199_vdcFaulted : 6|1@1+ (1,0) [0|1] ""  gtw
 SG_ DI_a198_vdcEspMCPressAndSteering : 5|1@1+ (1,0) [0|1] ""  gtw
 SG_ DI_a197_vdcEspWheelSaturations : 4|1@1+ (1,0) [0|1] ""  gtw
 SG_ DI_a196_vdcEspSlipRe : 3|1@1+ (1,0) [0|1] ""  gtw
 SG_ DI_a195_vdcEspSlipFr : 2|1@1+ (1,0) [0|1] ""  gtw
 SG_ DI_a194_vdcEspBrakeTorqueRe : 1|1@1+ (1,0) [0|1] ""  gtw
 SG_ DI_a193_vdcEspBrakeTorqueFr : 0|1@1+ (1,0) [0|1] ""  gtw

BO_ 1556 PM_udsResponse: 8 VEH
 SG_ PM_udsResponseData : 7|64@0+ (1,0) [0|18446744073709551615] ""  gtw

BO_ 1947 XCP_epblRequest: 8 VEH
 SG_ XCP_epblRequest : 7|64@0+ (1,0) [0|18446744073709551615] ""  epbl

BO_ 1367 DI_thermalControl: 3 VEH
 SG_ DI_coolantFlowReq : 16|8@1+ (0.2,0) [0|50] "LPM"  gtw
 SG_ DI_activeInletTempReq : 8|8@1+ (1,-40) [-40|120] "DegC"  gtw
 SG_ DI_passiveInletTempReq : 0|8@1+ (1,-40) [-40|120] "DegC"  gtw

BA_DEF_ SG_  "SystemSignalLongSymbol" STRING ;
BA_DEF_DEF_  "SystemSignalLongSymbol" "";
BA_ "SystemSignalLongSymbol" SG_ 1373 VCLEFT_a302_TMS320OverTempShutDw "VCLEFT_a302_TMS320OverTempShutDwn";
BA_ "SystemSignalLongSymbol" SG_ 1373 VCLEFT_a117_VEH_intrusionSensorS "VCLEFT_a117_VEH_intrusionSensorStatus";
BA_ "SystemSignalLongSymbol" SG_ 1373 VCLEFT_a113_VEH_powertrainContro "VCLEFT_a113_VEH_powertrainControl";
BA_ "SystemSignalLongSymbol" SG_ 705 VCFRONT_compLimitTempDischargeSi "VCFRONT_compLimitTempDischargeSim";
BA_ "SystemSignalLongSymbol" SG_ 994 VCLEFT_rightTrnTrailerLightStatu "VCLEFT_rightTrnTrailerLightStatus";
BA_ "SystemSignalLongSymbol" SG_ 994 VCLEFT_leftTurnTrailerLightStatu "VCLEFT_leftTurnTrailerLightStatus";
BA_ "SystemSignalLongSymbol" SG_ 859 DI_a232_velocityEstimatorDegrade "DI_a232_velocityEstimatorDegraded";
BA_ "SystemSignalLongSymbol" SG_ 859 DI_a200_vdcModelBasedPlausibilit "DI_a200_vdcModelBasedPlausibility";
VAL_ 1373 VCLEFT_a265_seatMotorState 1 "SEAT_STATE_MOVING_UP" 2 "SEAT_STATE_MOVING_DOWN" 3 "SEAT_STATE_RECALLING" 0 "SEAT_STATE_STOPPED" 5 "SEAT_STATE_UNDEFINED" 4 "SEAT_STATE_CALIBRATING" ;
VAL_ 1373 VCLEFT_a237_lumbarBState 1 "SEAT_STATE_MOVING_UP" 2 "SEAT_STATE_MOVING_DOWN" 3 "SEAT_STATE_RECALLING" 0 "SEAT_STATE_STOPPED" 5 "SEAT_STATE_UNDEFINED" 4 "SEAT_STATE_CALIBRATING" ;
VAL_ 1373 VCLEFT_a269_seatMotorState 1 "SEAT_STATE_MOVING_UP" 2 "SEAT_STATE_MOVING_DOWN" 3 "SEAT_STATE_RECALLING" 0 "SEAT_STATE_STOPPED" 5 "SEAT_STATE_UNDEFINED" 4 "SEAT_STATE_CALIBRATING" ;
VAL_ 1373 VCLEFT_a270_seatMotorState 1 "SEAT_STATE_MOVING_UP" 2 "SEAT_STATE_MOVING_DOWN" 3 "SEAT_STATE_RECALLING" 0 "SEAT_STATE_STOPPED" 5 "SEAT_STATE_UNDEFINED" 4 "SEAT_STATE_CALIBRATING" ;
VAL_ 1373 VCLEFT_a266_seatMotorState 1 "SEAT_STATE_MOVING_UP" 2 "SEAT_STATE_MOVING_DOWN" 3 "SEAT_STATE_RECALLING" 0 "SEAT_STATE_STOPPED" 5 "SEAT_STATE_UNDEFINED" 4 "SEAT_STATE_CALIBRATING" ;
VAL_ 1373 VCLEFT_a263_seatMotorState 1 "SEAT_STATE_MOVING_UP" 2 "SEAT_STATE_MOVING_DOWN" 3 "SEAT_STATE_RECALLING" 0 "SEAT_STATE_STOPPED" 5 "SEAT_STATE_UNDEFINED" 4 "SEAT_STATE_CALIBRATING" ;
VAL_ 1373 VCLEFT_a238_lumbarBState 1 "SEAT_STATE_MOVING_UP" 2 "SEAT_STATE_MOVING_DOWN" 3 "SEAT_STATE_RECALLING" 0 "SEAT_STATE_STOPPED" 5 "SEAT_STATE_UNDEFINED" 4 "SEAT_STATE_CALIBRATING" ;
VAL_ 1373 VCLEFT_a267_seatMotorState 1 "SEAT_STATE_MOVING_UP" 2 "SEAT_STATE_MOVING_DOWN" 3 "SEAT_STATE_RECALLING" 0 "SEAT_STATE_STOPPED" 5 "SEAT_STATE_UNDEFINED" 4 "SEAT_STATE_CALIBRATING" ;
VAL_ 1373 VCLEFT_a236_lumbarBState 1 "SEAT_STATE_MOVING_UP" 2 "SEAT_STATE_MOVING_DOWN" 3 "SEAT_STATE_RECALLING" 0 "SEAT_STATE_STOPPED" 5 "SEAT_STATE_UNDEFINED" 4 "SEAT_STATE_CALIBRATING" ;
VAL_ 1373 VCLEFT_a264_seatMotorState 1 "SEAT_STATE_MOVING_UP" 2 "SEAT_STATE_MOVING_DOWN" 3 "SEAT_STATE_RECALLING" 0 "SEAT_STATE_STOPPED" 5 "SEAT_STATE_UNDEFINED" 4 "SEAT_STATE_CALIBRATING" ;
VAL_ 1373 VCLEFT_a268_seatMotorState 1 "SEAT_STATE_MOVING_UP" 2 "SEAT_STATE_MOVING_DOWN" 3 "SEAT_STATE_RECALLING" 0 "SEAT_STATE_STOPPED" 5 "SEAT_STATE_UNDEFINED" 4 "SEAT_STATE_CALIBRATING" ;
VAL_ 1373 VCLEFT_a223_seatSwitchForward 2 "SWITCH_ON" 0 "SWITCH_SNA" 3 "SWITCH_FAULT" 1 "SWITCH_OFF" ;
VAL_ 1373 VCLEFT_a220_seatSwitchForward 2 "SWITCH_ON" 0 "SWITCH_SNA" 3 "SWITCH_FAULT" 1 "SWITCH_OFF" ;
VAL_ 1373 VCLEFT_a221_seatSwitchForward 2 "SWITCH_ON" 0 "SWITCH_SNA" 3 "SWITCH_FAULT" 1 "SWITCH_OFF" ;
VAL_ 1373 VCLEFT_a231_seatSwitchForward 2 "SWITCH_ON" 0 "SWITCH_SNA" 3 "SWITCH_FAULT" 1 "SWITCH_OFF" ;
VAL_ 1373 VCLEFT_a228_seatSwitchForward 2 "SWITCH_ON" 0 "SWITCH_SNA" 3 "SWITCH_FAULT" 1 "SWITCH_OFF" ;
VAL_ 1373 VCLEFT_a222_seatSwitchForward 2 "SWITCH_ON" 0 "SWITCH_SNA" 3 "SWITCH_FAULT" 1 "SWITCH_OFF" ;
VAL_ 1373 VCLEFT_a230_seatSwitchForward 2 "SWITCH_ON" 0 "SWITCH_SNA" 3 "SWITCH_FAULT" 1 "SWITCH_OFF" ;
VAL_ 1373 VCLEFT_a229_seatSwitchForward 2 "SWITCH_ON" 0 "SWITCH_SNA" 3 "SWITCH_FAULT" 1 "SWITCH_OFF" ;
VAL_ 1373 VCLEFT_a238_lumbarAState 1 "SEAT_STATE_MOVING_UP" 2 "SEAT_STATE_MOVING_DOWN" 3 "SEAT_STATE_RECALLING" 0 "SEAT_STATE_STOPPED" 5 "SEAT_STATE_UNDEFINED" 4 "SEAT_STATE_CALIBRATING" ;
VAL_ 1373 VCLEFT_a237_lumbarAState 1 "SEAT_STATE_MOVING_UP" 2 "SEAT_STATE_MOVING_DOWN" 3 "SEAT_STATE_RECALLING" 0 "SEAT_STATE_STOPPED" 5 "SEAT_STATE_UNDEFINED" 4 "SEAT_STATE_CALIBRATING" ;
VAL_ 1373 VCLEFT_a236_lumbarAState 1 "SEAT_STATE_MOVING_UP" 2 "SEAT_STATE_MOVING_DOWN" 3 "SEAT_STATE_RECALLING" 0 "SEAT_STATE_STOPPED" 5 "SEAT_STATE_UNDEFINED" 4 "SEAT_STATE_CALIBRATING" ;
VAL_ 1373 VCLEFT_a181_latchStatus 8 "LATCH_FAULT" 2 "LATCH_CLOSED" 1 "LATCH_OPENED" 3 "LATCH_CLOSING" 7 "LATCH_DEFAULT" 4 "LATCH_OPENING" 5 "LATCH_AJAR" 6 "LATCH_TIMEOUT" 0 "LATCH_SNA" ;
VAL_ 1373 VCLEFT_a223_seatSwitchBack 2 "SWITCH_ON" 0 "SWITCH_SNA" 3 "SWITCH_FAULT" 1 "SWITCH_OFF" ;
VAL_ 1373 VCLEFT_a180_latchStatus 8 "LATCH_FAULT" 2 "LATCH_CLOSED" 1 "LATCH_OPENED" 3 "LATCH_CLOSING" 7 "LATCH_DEFAULT" 4 "LATCH_OPENING" 5 "LATCH_AJAR" 6 "LATCH_TIMEOUT" 0 "LATCH_SNA" ;
VAL_ 1373 VCLEFT_a231_seatSwitchBack 2 "SWITCH_ON" 0 "SWITCH_SNA" 3 "SWITCH_FAULT" 1 "SWITCH_OFF" ;
VAL_ 1373 VCLEFT_a228_seatSwitchBack 2 "SWITCH_ON" 0 "SWITCH_SNA" 3 "SWITCH_FAULT" 1 "SWITCH_OFF" ;
VAL_ 1373 VCLEFT_a222_seatSwitchBack 2 "SWITCH_ON" 0 "SWITCH_SNA" 3 "SWITCH_FAULT" 1 "SWITCH_OFF" ;
VAL_ 1373 VCLEFT_a221_seatSwitchBack 2 "SWITCH_ON" 0 "SWITCH_SNA" 3 "SWITCH_FAULT" 1 "SWITCH_OFF" ;
VAL_ 1373 VCLEFT_a220_seatSwitchBack 2 "SWITCH_ON" 0 "SWITCH_SNA" 3 "SWITCH_FAULT" 1 "SWITCH_OFF" ;
VAL_ 1373 VCLEFT_a229_seatSwitchBack 2 "SWITCH_ON" 0 "SWITCH_SNA" 3 "SWITCH_FAULT" 1 "SWITCH_OFF" ;
VAL_ 1373 VCLEFT_a230_seatSwitchBack 2 "SWITCH_ON" 0 "SWITCH_SNA" 3 "SWITCH_FAULT" 1 "SWITCH_OFF" ;
VAL_ 1373 VCLEFT_a235_seatSwitchForward 2 "SWITCH_ON" 0 "SWITCH_SNA" 3 "SWITCH_FAULT" 1 "SWITCH_OFF" ;
VAL_ 1373 VCLEFT_a253_seatSwitchForward 2 "SWITCH_ON" 0 "SWITCH_SNA" 3 "SWITCH_FAULT" 1 "SWITCH_OFF" ;
VAL_ 1373 VCLEFT_a252_seatSwitchForward 2 "SWITCH_ON" 0 "SWITCH_SNA" 3 "SWITCH_FAULT" 1 "SWITCH_OFF" ;
VAL_ 1373 VCLEFT_a234_seatSwitchForward 2 "SWITCH_ON" 0 "SWITCH_SNA" 3 "SWITCH_FAULT" 1 "SWITCH_OFF" ;
VAL_ 1373 VCLEFT_a233_seatSwitchForward 2 "SWITCH_ON" 0 "SWITCH_SNA" 3 "SWITCH_FAULT" 1 "SWITCH_OFF" ;
VAL_ 1373 VCLEFT_a232_seatSwitchForward 2 "SWITCH_ON" 0 "SWITCH_SNA" 3 "SWITCH_FAULT" 1 "SWITCH_OFF" ;
VAL_ 1373 VCLEFT_a254_seatSwitchForward 2 "SWITCH_ON" 0 "SWITCH_SNA" 3 "SWITCH_FAULT" 1 "SWITCH_OFF" ;
VAL_ 1373 VCLEFT_a251_seatSwitchForward 2 "SWITCH_ON" 0 "SWITCH_SNA" 3 "SWITCH_FAULT" 1 "SWITCH_OFF" ;
VAL_ 1373 VCLEFT_a221_seatMotorState 1 "SEAT_STATE_MOVING_UP" 2 "SEAT_STATE_MOVING_DOWN" 3 "SEAT_STATE_RECALLING" 0 "SEAT_STATE_STOPPED" 5 "SEAT_STATE_UNDEFINED" 4 "SEAT_STATE_CALIBRATING" ;
VAL_ 1373 VCLEFT_a231_seatMotorState 1 "SEAT_STATE_MOVING_UP" 2 "SEAT_STATE_MOVING_DOWN" 3 "SEAT_STATE_RECALLING" 0 "SEAT_STATE_STOPPED" 5 "SEAT_STATE_UNDEFINED" 4 "SEAT_STATE_CALIBRATING" ;
VAL_ 1373 VCLEFT_a228_seatMotorState 1 "SEAT_STATE_MOVING_UP" 2 "SEAT_STATE_MOVING_DOWN" 3 "SEAT_STATE_RECALLING" 0 "SEAT_STATE_STOPPED" 5 "SEAT_STATE_UNDEFINED" 4 "SEAT_STATE_CALIBRATING" ;
VAL_ 1373 VCLEFT_a222_seatMotorState 1 "SEAT_STATE_MOVING_UP" 2 "SEAT_STATE_MOVING_DOWN" 3 "SEAT_STATE_RECALLING" 0 "SEAT_STATE_STOPPED" 5 "SEAT_STATE_UNDEFINED" 4 "SEAT_STATE_CALIBRATING" ;
VAL_ 1373 VCLEFT_a229_seatMotorState 1 "SEAT_STATE_MOVING_UP" 2 "SEAT_STATE_MOVING_DOWN" 3 "SEAT_STATE_RECALLING" 0 "SEAT_STATE_STOPPED" 5 "SEAT_STATE_UNDEFINED" 4 "SEAT_STATE_CALIBRATING" ;
VAL_ 1373 VCLEFT_a230_seatMotorState 1 "SEAT_STATE_MOVING_UP" 2 "SEAT_STATE_MOVING_DOWN" 3 "SEAT_STATE_RECALLING" 0 "SEAT_STATE_STOPPED" 5 "SEAT_STATE_UNDEFINED" 4 "SEAT_STATE_CALIBRATING" ;
VAL_ 1373 VCLEFT_a223_seatMotorState 1 "SEAT_STATE_MOVING_UP" 2 "SEAT_STATE_MOVING_DOWN" 3 "SEAT_STATE_RECALLING" 0 "SEAT_STATE_STOPPED" 5 "SEAT_STATE_UNDEFINED" 4 "SEAT_STATE_CALIBRATING" ;
VAL_ 1373 VCLEFT_a220_seatMotorState 1 "SEAT_STATE_MOVING_UP" 2 "SEAT_STATE_MOVING_DOWN" 3 "SEAT_STATE_RECALLING" 0 "SEAT_STATE_STOPPED" 5 "SEAT_STATE_UNDEFINED" 4 "SEAT_STATE_CALIBRATING" ;
VAL_ 1373 VCLEFT_a251_seatSwitchBack 2 "SWITCH_ON" 0 "SWITCH_SNA" 3 "SWITCH_FAULT" 1 "SWITCH_OFF" ;
VAL_ 1373 VCLEFT_a234_seatSwitchBack 2 "SWITCH_ON" 0 "SWITCH_SNA" 3 "SWITCH_FAULT" 1 "SWITCH_OFF" ;
VAL_ 1373 VCLEFT_a252_seatSwitchBack 2 "SWITCH_ON" 0 "SWITCH_SNA" 3 "SWITCH_FAULT" 1 "SWITCH_OFF" ;
VAL_ 1373 VCLEFT_a235_seatSwitchBack 2 "SWITCH_ON" 0 "SWITCH_SNA" 3 "SWITCH_FAULT" 1 "SWITCH_OFF" ;
VAL_ 1373 VCLEFT_a253_seatSwitchBack 2 "SWITCH_ON" 0 "SWITCH_SNA" 3 "SWITCH_FAULT" 1 "SWITCH_OFF" ;
VAL_ 1373 VCLEFT_a232_seatSwitchBack 2 "SWITCH_ON" 0 "SWITCH_SNA" 3 "SWITCH_FAULT" 1 "SWITCH_OFF" ;
VAL_ 1373 VCLEFT_a254_seatSwitchBack 2 "SWITCH_ON" 0 "SWITCH_SNA" 3 "SWITCH_FAULT" 1 "SWITCH_OFF" ;
VAL_ 1373 VCLEFT_a233_seatSwitchBack 2 "SWITCH_ON" 0 "SWITCH_SNA" 3 "SWITCH_FAULT" 1 "SWITCH_OFF" ;
VAL_ 1373 VCLEFT_a254_seatMotorState 1 "SEAT_STATE_MOVING_UP" 2 "SEAT_STATE_MOVING_DOWN" 3 "SEAT_STATE_RECALLING" 0 "SEAT_STATE_STOPPED" 5 "SEAT_STATE_UNDEFINED" 4 "SEAT_STATE_CALIBRATING" ;
VAL_ 1373 VCLEFT_a232_seatMotorState 1 "SEAT_STATE_MOVING_UP" 2 "SEAT_STATE_MOVING_DOWN" 3 "SEAT_STATE_RECALLING" 0 "SEAT_STATE_STOPPED" 5 "SEAT_STATE_UNDEFINED" 4 "SEAT_STATE_CALIBRATING" ;
VAL_ 1373 VCLEFT_a208_unitStatusEPBM 14 "EPB_STATUS_SUMMON" 1 "EPB_STATUS_OPEN" 9 "EPB_STATUS_DYNAMIC_APPLYING" 21 "EPB_STATUS_COUNT" 12 "EPB_STATUS_PARK_PENDING" 13 "EPB_STATUS_WINCHMODE_PENDING" 6 "EPB_STATUS_WINCHMODE" 3 "EPB_STATUS_PARK" 0 "EPB_STATUS_UNKNOWN" 4 "EPB_STATUS_START" 18 "EPB_STATUS_RELEASING_FOR_EXTERNAL_PARK" 19 "EPB_STATUS_EXTERNAL_PARKING" 17 "EPB_STATUS_EXTERNAL_DYNAMIC" 10 "EPB_STATUS_RELEASING" 15 "EPB_STATUS_SUMMON_RELEASING" 11 "EPB_STATUS_SERVICE_RELEASING" 7 "EPB_STATUS_WINCHMODE_RELEASING" 16 "EPB_STATUS_SUMMON_PARKING" 8 "EPB_STATUS_PARKING" 2 "EPB_STATUS_DYNAMIC" 5 "EPB_STATUS_SERVICE" 20 "EPB_STATUS_DYNAMIC_PARKING" ;
VAL_ 1373 VCLEFT_a234_seatMotorState 1 "SEAT_STATE_MOVING_UP" 2 "SEAT_STATE_MOVING_DOWN" 3 "SEAT_STATE_RECALLING" 0 "SEAT_STATE_STOPPED" 5 "SEAT_STATE_UNDEFINED" 4 "SEAT_STATE_CALIBRATING" ;
VAL_ 1373 VCLEFT_a252_seatMotorState 1 "SEAT_STATE_MOVING_UP" 2 "SEAT_STATE_MOVING_DOWN" 3 "SEAT_STATE_RECALLING" 0 "SEAT_STATE_STOPPED" 5 "SEAT_STATE_UNDEFINED" 4 "SEAT_STATE_CALIBRATING" ;
VAL_ 1373 VCLEFT_a207_unitStatusEPBM 14 "EPB_STATUS_SUMMON" 1 "EPB_STATUS_OPEN" 9 "EPB_STATUS_DYNAMIC_APPLYING" 21 "EPB_STATUS_COUNT" 12 "EPB_STATUS_PARK_PENDING" 13 "EPB_STATUS_WINCHMODE_PENDING" 6 "EPB_STATUS_WINCHMODE" 3 "EPB_STATUS_PARK" 0 "EPB_STATUS_UNKNOWN" 4 "EPB_STATUS_START" 18 "EPB_STATUS_RELEASING_FOR_EXTERNAL_PARK" 19 "EPB_STATUS_EXTERNAL_PARKING" 17 "EPB_STATUS_EXTERNAL_DYNAMIC" 10 "EPB_STATUS_RELEASING" 15 "EPB_STATUS_SUMMON_RELEASING" 11 "EPB_STATUS_SERVICE_RELEASING" 7 "EPB_STATUS_WINCHMODE_RELEASING" 16 "EPB_STATUS_SUMMON_PARKING" 8 "EPB_STATUS_PARKING" 2 "EPB_STATUS_DYNAMIC" 5 "EPB_STATUS_SERVICE" 20 "EPB_STATUS_DYNAMIC_PARKING" ;
VAL_ 1373 VCLEFT_a251_seatMotorState 1 "SEAT_STATE_MOVING_UP" 2 "SEAT_STATE_MOVING_DOWN" 3 "SEAT_STATE_RECALLING" 0 "SEAT_STATE_STOPPED" 5 "SEAT_STATE_UNDEFINED" 4 "SEAT_STATE_CALIBRATING" ;
VAL_ 1373 VCLEFT_a206_unitStatusEPBM 14 "EPB_STATUS_SUMMON" 1 "EPB_STATUS_OPEN" 9 "EPB_STATUS_DYNAMIC_APPLYING" 21 "EPB_STATUS_COUNT" 12 "EPB_STATUS_PARK_PENDING" 13 "EPB_STATUS_WINCHMODE_PENDING" 6 "EPB_STATUS_WINCHMODE" 3 "EPB_STATUS_PARK" 0 "EPB_STATUS_UNKNOWN" 4 "EPB_STATUS_START" 18 "EPB_STATUS_RELEASING_FOR_EXTERNAL_PARK" 19 "EPB_STATUS_EXTERNAL_PARKING" 17 "EPB_STATUS_EXTERNAL_DYNAMIC" 10 "EPB_STATUS_RELEASING" 15 "EPB_STATUS_SUMMON_RELEASING" 11 "EPB_STATUS_SERVICE_RELEASING" 7 "EPB_STATUS_WINCHMODE_RELEASING" 16 "EPB_STATUS_SUMMON_PARKING" 8 "EPB_STATUS_PARKING" 2 "EPB_STATUS_DYNAMIC" 5 "EPB_STATUS_SERVICE" 20 "EPB_STATUS_DYNAMIC_PARKING" ;
VAL_ 1373 VCLEFT_a233_seatMotorState 1 "SEAT_STATE_MOVING_UP" 2 "SEAT_STATE_MOVING_DOWN" 3 "SEAT_STATE_RECALLING" 0 "SEAT_STATE_STOPPED" 5 "SEAT_STATE_UNDEFINED" 4 "SEAT_STATE_CALIBRATING" ;
VAL_ 1373 VCLEFT_a210_unitStatusEPBM 14 "EPB_STATUS_SUMMON" 1 "EPB_STATUS_OPEN" 9 "EPB_STATUS_DYNAMIC_APPLYING" 21 "EPB_STATUS_COUNT" 12 "EPB_STATUS_PARK_PENDING" 13 "EPB_STATUS_WINCHMODE_PENDING" 6 "EPB_STATUS_WINCHMODE" 3 "EPB_STATUS_PARK" 0 "EPB_STATUS_UNKNOWN" 4 "EPB_STATUS_START" 18 "EPB_STATUS_RELEASING_FOR_EXTERNAL_PARK" 19 "EPB_STATUS_EXTERNAL_PARKING" 17 "EPB_STATUS_EXTERNAL_DYNAMIC" 10 "EPB_STATUS_RELEASING" 15 "EPB_STATUS_SUMMON_RELEASING" 11 "EPB_STATUS_SERVICE_RELEASING" 7 "EPB_STATUS_WINCHMODE_RELEASING" 16 "EPB_STATUS_SUMMON_PARKING" 8 "EPB_STATUS_PARKING" 2 "EPB_STATUS_DYNAMIC" 5 "EPB_STATUS_SERVICE" 20 "EPB_STATUS_DYNAMIC_PARKING" ;
VAL_ 1373 VCLEFT_a253_seatMotorState 1 "SEAT_STATE_MOVING_UP" 2 "SEAT_STATE_MOVING_DOWN" 3 "SEAT_STATE_RECALLING" 0 "SEAT_STATE_STOPPED" 5 "SEAT_STATE_UNDEFINED" 4 "SEAT_STATE_CALIBRATING" ;
VAL_ 1373 VCLEFT_a235_seatMotorState 1 "SEAT_STATE_MOVING_UP" 2 "SEAT_STATE_MOVING_DOWN" 3 "SEAT_STATE_RECALLING" 0 "SEAT_STATE_STOPPED" 5 "SEAT_STATE_UNDEFINED" 4 "SEAT_STATE_CALIBRATING" ;
VAL_ 1373 VCLEFT_a209_unitStatusEPBM 14 "EPB_STATUS_SUMMON" 1 "EPB_STATUS_OPEN" 9 "EPB_STATUS_DYNAMIC_APPLYING" 21 "EPB_STATUS_COUNT" 12 "EPB_STATUS_PARK_PENDING" 13 "EPB_STATUS_WINCHMODE_PENDING" 6 "EPB_STATUS_WINCHMODE" 3 "EPB_STATUS_PARK" 0 "EPB_STATUS_UNKNOWN" 4 "EPB_STATUS_START" 18 "EPB_STATUS_RELEASING_FOR_EXTERNAL_PARK" 19 "EPB_STATUS_EXTERNAL_PARKING" 17 "EPB_STATUS_EXTERNAL_DYNAMIC" 10 "EPB_STATUS_RELEASING" 15 "EPB_STATUS_SUMMON_RELEASING" 11 "EPB_STATUS_SERVICE_RELEASING" 7 "EPB_STATUS_WINCHMODE_RELEASING" 16 "EPB_STATUS_SUMMON_PARKING" 8 "EPB_STATUS_PARKING" 2 "EPB_STATUS_DYNAMIC" 5 "EPB_STATUS_SERVICE" 20 "EPB_STATUS_DYNAMIC_PARKING" ;
VAL_ 1373 VCLEFT_a226_seatSwitchForward 2 "SWITCH_ON" 0 "SWITCH_SNA" 3 "SWITCH_FAULT" 1 "SWITCH_OFF" ;
VAL_ 1373 VCLEFT_a227_seatSwitchForward 2 "SWITCH_ON" 0 "SWITCH_SNA" 3 "SWITCH_FAULT" 1 "SWITCH_OFF" ;
VAL_ 1373 VCLEFT_a224_seatSwitchForward 2 "SWITCH_ON" 0 "SWITCH_SNA" 3 "SWITCH_FAULT" 1 "SWITCH_OFF" ;
VAL_ 1373 VCLEFT_a225_seatSwitchForward 2 "SWITCH_ON" 0 "SWITCH_SNA" 3 "SWITCH_FAULT" 1 "SWITCH_OFF" ;
VAL_ 1373 VCLEFT_a210_unitStatusEPB 14 "EPB_STATUS_SUMMON" 1 "EPB_STATUS_OPEN" 9 "EPB_STATUS_DYNAMIC_APPLYING" 21 "EPB_STATUS_COUNT" 12 "EPB_STATUS_PARK_PENDING" 13 "EPB_STATUS_WINCHMODE_PENDING" 6 "EPB_STATUS_WINCHMODE" 3 "EPB_STATUS_PARK" 0 "EPB_STATUS_UNKNOWN" 4 "EPB_STATUS_START" 18 "EPB_STATUS_RELEASING_FOR_EXTERNAL_PARK" 19 "EPB_STATUS_EXTERNAL_PARKING" 17 "EPB_STATUS_EXTERNAL_DYNAMIC" 10 "EPB_STATUS_RELEASING" 15 "EPB_STATUS_SUMMON_RELEASING" 11 "EPB_STATUS_SERVICE_RELEASING" 7 "EPB_STATUS_WINCHMODE_RELEASING" 16 "EPB_STATUS_SUMMON_PARKING" 8 "EPB_STATUS_PARKING" 2 "EPB_STATUS_DYNAMIC" 5 "EPB_STATUS_SERVICE" 20 "EPB_STATUS_DYNAMIC_PARKING" ;
VAL_ 1373 VCLEFT_a224_seatSwitchBack 2 "SWITCH_ON" 0 "SWITCH_SNA" 3 "SWITCH_FAULT" 1 "SWITCH_OFF" ;
VAL_ 1373 VCLEFT_a209_unitStatusEPB 14 "EPB_STATUS_SUMMON" 1 "EPB_STATUS_OPEN" 9 "EPB_STATUS_DYNAMIC_APPLYING" 21 "EPB_STATUS_COUNT" 12 "EPB_STATUS_PARK_PENDING" 13 "EPB_STATUS_WINCHMODE_PENDING" 6 "EPB_STATUS_WINCHMODE" 3 "EPB_STATUS_PARK" 0 "EPB_STATUS_UNKNOWN" 4 "EPB_STATUS_START" 18 "EPB_STATUS_RELEASING_FOR_EXTERNAL_PARK" 19 "EPB_STATUS_EXTERNAL_PARKING" 17 "EPB_STATUS_EXTERNAL_DYNAMIC" 10 "EPB_STATUS_RELEASING" 15 "EPB_STATUS_SUMMON_RELEASING" 11 "EPB_STATUS_SERVICE_RELEASING" 7 "EPB_STATUS_WINCHMODE_RELEASING" 16 "EPB_STATUS_SUMMON_PARKING" 8 "EPB_STATUS_PARKING" 2 "EPB_STATUS_DYNAMIC" 5 "EPB_STATUS_SERVICE" 20 "EPB_STATUS_DYNAMIC_PARKING" ;
VAL_ 1373 VCLEFT_a151_windowPinchReason 1 "WINDOW_PINCH_REASON_POWER" 2 "WINDOW_PINCH_REASON_POWER_DIV_SPEED" 3 "WINDOW_PINCH_REASON_POWER_CRUDE" 0 "WINDOW_PINCH_REASON_NONE" 4 "WINDOW_PINCH_REASON_UNUSED" ;
VAL_ 1373 VCLEFT_a206_unitStatusEPB 14 "EPB_STATUS_SUMMON" 1 "EPB_STATUS_OPEN" 9 "EPB_STATUS_DYNAMIC_APPLYING" 21 "EPB_STATUS_COUNT" 12 "EPB_STATUS_PARK_PENDING" 13 "EPB_STATUS_WINCHMODE_PENDING" 6 "EPB_STATUS_WINCHMODE" 3 "EPB_STATUS_PARK" 0 "EPB_STATUS_UNKNOWN" 4 "EPB_STATUS_START" 18 "EPB_STATUS_RELEASING_FOR_EXTERNAL_PARK" 19 "EPB_STATUS_EXTERNAL_PARKING" 17 "EPB_STATUS_EXTERNAL_DYNAMIC" 10 "EPB_STATUS_RELEASING" 15 "EPB_STATUS_SUMMON_RELEASING" 11 "EPB_STATUS_SERVICE_RELEASING" 7 "EPB_STATUS_WINCHMODE_RELEASING" 16 "EPB_STATUS_SUMMON_PARKING" 8 "EPB_STATUS_PARKING" 2 "EPB_STATUS_DYNAMIC" 5 "EPB_STATUS_SERVICE" 20 "EPB_STATUS_DYNAMIC_PARKING" ;
VAL_ 1373 VCLEFT_a208_unitStatusEPB 14 "EPB_STATUS_SUMMON" 1 "EPB_STATUS_OPEN" 9 "EPB_STATUS_DYNAMIC_APPLYING" 21 "EPB_STATUS_COUNT" 12 "EPB_STATUS_PARK_PENDING" 13 "EPB_STATUS_WINCHMODE_PENDING" 6 "EPB_STATUS_WINCHMODE" 3 "EPB_STATUS_PARK" 0 "EPB_STATUS_UNKNOWN" 4 "EPB_STATUS_START" 18 "EPB_STATUS_RELEASING_FOR_EXTERNAL_PARK" 19 "EPB_STATUS_EXTERNAL_PARKING" 17 "EPB_STATUS_EXTERNAL_DYNAMIC" 10 "EPB_STATUS_RELEASING" 15 "EPB_STATUS_SUMMON_RELEASING" 11 "EPB_STATUS_SERVICE_RELEASING" 7 "EPB_STATUS_WINCHMODE_RELEASING" 16 "EPB_STATUS_SUMMON_PARKING" 8 "EPB_STATUS_PARKING" 2 "EPB_STATUS_DYNAMIC" 5 "EPB_STATUS_SERVICE" 20 "EPB_STATUS_DYNAMIC_PARKING" ;
VAL_ 1373 VCLEFT_a227_seatSwitchBack 2 "SWITCH_ON" 0 "SWITCH_SNA" 3 "SWITCH_FAULT" 1 "SWITCH_OFF" ;
VAL_ 1373 VCLEFT_a226_seatSwitchBack 2 "SWITCH_ON" 0 "SWITCH_SNA" 3 "SWITCH_FAULT" 1 "SWITCH_OFF" ;
VAL_ 1373 VCLEFT_a225_seatSwitchBack 2 "SWITCH_ON" 0 "SWITCH_SNA" 3 "SWITCH_FAULT" 1 "SWITCH_OFF" ;
VAL_ 1373 VCLEFT_a207_unitStatusEPB 14 "EPB_STATUS_SUMMON" 1 "EPB_STATUS_OPEN" 9 "EPB_STATUS_DYNAMIC_APPLYING" 21 "EPB_STATUS_COUNT" 12 "EPB_STATUS_PARK_PENDING" 13 "EPB_STATUS_WINCHMODE_PENDING" 6 "EPB_STATUS_WINCHMODE" 3 "EPB_STATUS_PARK" 0 "EPB_STATUS_UNKNOWN" 4 "EPB_STATUS_START" 18 "EPB_STATUS_RELEASING_FOR_EXTERNAL_PARK" 19 "EPB_STATUS_EXTERNAL_PARKING" 17 "EPB_STATUS_EXTERNAL_DYNAMIC" 10 "EPB_STATUS_RELEASING" 15 "EPB_STATUS_SUMMON_RELEASING" 11 "EPB_STATUS_SERVICE_RELEASING" 7 "EPB_STATUS_WINCHMODE_RELEASING" 16 "EPB_STATUS_SUMMON_PARKING" 8 "EPB_STATUS_PARKING" 2 "EPB_STATUS_DYNAMIC" 5 "EPB_STATUS_SERVICE" 20 "EPB_STATUS_DYNAMIC_PARKING" ;
VAL_ 1373 VCLEFT_a150_windowPinchReason 1 "WINDOW_PINCH_REASON_POWER" 2 "WINDOW_PINCH_REASON_POWER_DIV_SPEED" 3 "WINDOW_PINCH_REASON_POWER_CRUDE" 0 "WINDOW_PINCH_REASON_NONE" 4 "WINDOW_PINCH_REASON_UNUSED" ;
VAL_ 1373 VCLEFT_a226_seatMotorState 1 "SEAT_STATE_MOVING_UP" 2 "SEAT_STATE_MOVING_DOWN" 3 "SEAT_STATE_RECALLING" 0 "SEAT_STATE_STOPPED" 5 "SEAT_STATE_UNDEFINED" 4 "SEAT_STATE_CALIBRATING" ;
VAL_ 1373 VCLEFT_a227_seatMotorState 1 "SEAT_STATE_MOVING_UP" 2 "SEAT_STATE_MOVING_DOWN" 3 "SEAT_STATE_RECALLING" 0 "SEAT_STATE_STOPPED" 5 "SEAT_STATE_UNDEFINED" 4 "SEAT_STATE_CALIBRATING" ;
VAL_ 1373 VCLEFT_a224_seatMotorState 1 "SEAT_STATE_MOVING_UP" 2 "SEAT_STATE_MOVING_DOWN" 3 "SEAT_STATE_RECALLING" 0 "SEAT_STATE_STOPPED" 5 "SEAT_STATE_UNDEFINED" 4 "SEAT_STATE_CALIBRATING" ;
VAL_ 1373 VCLEFT_a225_seatMotorState 1 "SEAT_STATE_MOVING_UP" 2 "SEAT_STATE_MOVING_DOWN" 3 "SEAT_STATE_RECALLING" 0 "SEAT_STATE_STOPPED" 5 "SEAT_STATE_UNDEFINED" 4 "SEAT_STATE_CALIBRATING" ;
VAL_ 1373 VCLEFT_a183_stopReason 5 "DOOR_STATE_TEST_STOP_REASON_FAILED_OPENING" 8 "DOOR_STATE_TEST_STOP_REASON_UDS" 7 "DOOR_STATE_TEST_STOP_REASON_TIMEOUT" 4 "DOOR_STATE_TEST_STOP_REASON_FAILED_CLOSED" 6 "DOOR_STATE_TEST_STOP_REASON_FAILED_OPENED" 2 "DOOR_STATE_TEST_STOP_REASON_EXTERIOR_HANDLE" 3 "DOOR_STATE_TEST_STOP_REASON_LOCKED" 0 "DOOR_STATE_TEST_STOP_REASON_NONE" 1 "DOOR_STATE_TEST_STOP_REASON_INTERIOR_HANDLE" ;
VAL_ 1373 VCLEFT_a164_stopReason 6 "WINDOW_TEST_STOP_REASON_UDS" 2 "WINDOW_TEST_STOP_REASON_THERMAL" 3 "WINDOW_TEST_STOP_REASON_TIMEOUT" 5 "WINDOW_TEST_STOP_REASON_DOOR" 4 "WINDOW_TEST_STOP_REASON_SWITCH" 0 "WINDOW_TEST_STOP_REASON_NONE" 1 "WINDOW_TEST_STOP_REASON_PINCH" ;
VAL_ 1373 VCLEFT_a164_lastState 4 "WINDOW_TEST_STATE_D_MOVE_UP_BUILD_PINCH_CALIBRATION_TABLE" 3 "WINDOW_TEST_STATE_C_MOVE_DOWN" 5 "WINDOW_TEST_STATE_E_FIND_POSITION" 2 "WINDOW_TEST_STATE_B_FIND_TOP" 0 "WINDOW_TEST_STATE_IDLE" 1 "WINDOW_TEST_STATE_A_FIND_BOTTOM" ;
VAL_ 1373 VCLEFT_a276_mirrorState 3 "MIRROR_STATE_FOLD_UNFOLD" 1 "MIRROR_STATE_TILT_X" 0 "MIRROR_STATE_IDLE" 2 "MIRROR_STATE_TILT_Y" 4 "MIRROR_STATE_RECALL" ;
VAL_ 1373 VCLEFT_a183_lastState 5 "DOOR_STATE_TEST_STATE_E_OPENED" 4 "DOOR_STATE_TEST_STATE_D_WAIT_FOR_OPENED" 6 "DOOR_STATE_TEST_STATE_F_DONE" 0 "DOOR_STATE_TEST_STATE_IDLE" 1 "DOOR_STATE_TEST_STATE_A_CLOSED" 3 "DOOR_STATE_TEST_STATE_C_OPENING" 2 "DOOR_STATE_TEST_STATE_B_WAIT_FOR_OPENING" ;
VAL_ 1373 VCLEFT_a272_actualState 3 "VEHICLE_POWER_STATE_DRIVE" 1 "VEHICLE_POWER_STATE_CONDITIONING" 2 "VEHICLE_POWER_STATE_ACCESSORY" 0 "VEHICLE_POWER_STATE_OFF" ;
VAL_ 1373 VCLEFT_a136_DIbrakePedalState 2 "INVALID" 0 "OFF" 1 "ON" ;
VAL_ 1373 VCLEFT_a154_windowThermalMode 0 "WINDOW_THERMAL_MODE_SNA" 2 "WINDOW_THERMAL_MODE_ALERT" 1 "WINDOW_THERMAL_MODE_NORMAL" 3 "WINDOW_THERMAL_MODE_CRITICAL" ;
VAL_ 1373 VCLEFT_a155_windowThermalMode 0 "WINDOW_THERMAL_MODE_SNA" 2 "WINDOW_THERMAL_MODE_ALERT" 1 "WINDOW_THERMAL_MODE_NORMAL" 3 "WINDOW_THERMAL_MODE_CRITICAL" ;
VAL_ 1373 VCLEFT_a185_summonFaultReason 9 "EPB_SUMMONFAULT_VEH_CAN_FAULT" 21 "EPB_SUMMONFAULT_PASSIVE_REQUEST" 26 "EPB_SUMMONFAULT_START_IN_UNAVAILABLE" 5 "EPB_SUMMONFAULT_DI_FAULT" 4 "EPB_SUMMONFAULT_EPBM_MIA" 12 "EPB_SUMMONFAULT_SPEED" 14 "EPB_SUMMONFAULT_PARK_MIA" 19 "EPB_SUMMONFAULT_EPB_FAULT" 25 "EPB_SUMMONFAULT_REMOTE_UNIT_FAULTED" 11 "EPB_SUMMONFAULT_EPBM_REQUEST" 16 "EPB_SUMMONFAULT_PM_REQUEST" 6 "EPB_SUMMONFAULT_DI_APC_FAULT" 13 "EPB_SUMMONFAULT_EXTERNAL" 23 "EPB_SUMMONFAULT_REMOTE_SUMMON_FAULTED" 24 "EPB_SUMMONFAULT_LOCAL_UNIT_FAULTED" 28 "EPB_SUMMONFAULT_REMOTE_DID_NOT_START" 1 "EPB_SUMMONFAULT_DI_MIA" 15 "EPB_SUMMONFAULT_PM_MIA" 27 "EPB_SUMMONFAULT_INVALID_REMOTE_STATE" 0 "EPB_SUMMONFAULT_NONE" 10 "EPB_SUMMONFAULT_EAC_NOT_ALLOWED" 22 "EPB_SUMMONFAULT_EPBREMOTE_MIA" 18 "EPB_SUMMONFAULT_MISMATCH" 3 "EPB_SUMMONFAULT_ESP_MIA" 2 "EPB_SUMMONFAULT_DAS_MIA" 20 "EPB_SUMMONFAULT_DI_STATE_INVALID" 8 "EPB_SUMMONFAULT_ESP_FAULT" 17 "EPB_SUMMONFAULT_OOC" 7 "EPB_SUMMONFAULT_DAS_FAULT" ;
VAL_ 1373 VCLEFT_a272_expectedState 3 "VEHICLE_POWER_STATE_DRIVE" 1 "VEHICLE_POWER_STATE_CONDITIONING" 2 "VEHICLE_POWER_STATE_ACCESSORY" 0 "VEHICLE_POWER_STATE_OFF" ;
VAL_ 1373 VCLEFT_a156_windowThermalMode 0 "WINDOW_THERMAL_MODE_SNA" 2 "WINDOW_THERMAL_MODE_ALERT" 1 "WINDOW_THERMAL_MODE_NORMAL" 3 "WINDOW_THERMAL_MODE_CRITICAL" ;
VAL_ 1373 VCLEFT_a136_brakeSwitch 2 "SWITCH_ON" 0 "SWITCH_SNA" 3 "SWITCH_FAULT" 1 "SWITCH_OFF" ;
VAL_ 1373 VCLEFT_a157_windowThermalMode 0 "WINDOW_THERMAL_MODE_SNA" 2 "WINDOW_THERMAL_MODE_ALERT" 1 "WINDOW_THERMAL_MODE_NORMAL" 3 "WINDOW_THERMAL_MODE_CRITICAL" ;
VAL_ 1373 VCLEFT_a276_mirrorDebugType 6 "MIRROR_DEBUG_RECALL_END" 1 "MIRROR_DEBUG_TIMEOUT" 4 "MIRROR_DEBUG_RECALL_POSITION" 2 "MIRROR_DEBUG_STALL" 3 "MIRROR_DEBUG_NOMINAL_POSITION_CHANGE" 5 "MIRROR_DEBUG_RECALL_START" 0 "MIRROR_DEBUG_NONE" ;
VAL_ 1373 VCLEFT_alertType 0 "ALERT_CLEARED" 1 "ALERT_SET" ;
VAL_ 1373 VCLEFT_alertID 295 "VCLEFT_a295_buckleFaultedRearL" 293 "VCLEFT_a293_occupancyFaultedRearC" 189 "VCLEFT_a189_latchUnableToRearmR" 237 "VCLEFT_a237_lumbarOverPresB" 130 "VCLEFT_a130_blowerICWarning" 215 "VCLEFT_a215_currentDesyncWarning" 202 "VCLEFT_a202_epbmUnderIStatic" 320 "VCLEFT_a320_windowPwrDerivFDBG" 100 "VCLEFT_a100_CANbus_MIA" 321 "VCLEFT_a321_windowPwrDeriv2FDBG" 46 "VCLEFT_a046_Task1000msError" 181 "VCLEFT_a181_rearDoorLatchRehome" 284 "VCLEFT_a284_blowerFbkSanity" 12 "VCLEFT_a012_CPUReset" 277 "VCLEFT_a277_BLELeftUnderVoltage" 305 "VCLEFT_a305_rearIntHandleShorted" 163 "VCLEFT_a163_windowEncoderStallR" 185 "VCLEFT_a185_summonAborted" 114 "VCLEFT_a114_ESP_MIA" 252 "VCLEFT_a252_seatUncalBack" 107 "VCLEFT_a107_BMS_MIA" 62 "VCLEFT_a062_XCPWasConnected" 268 "VCLEFT_a268_seatBackHCEncStlDbg" 322 "VCLEFT_a322_windowPwrDerivRDBG" 108 "VCLEFT_a108_DIS_MIA" 136 "VCLEFT_a136_brakeSwitchMismatch" 119 "VCLEFT_a119_SCCM_MIA" 294 "VCLEFT_a294_occupancyFaultedRearR" 287 "VCLEFT_a287_windowSpeedInvalidR" 150 "VCLEFT_a150_windowPinchFront" 106 "VCLEFT_a106_PCS_MIA" 307 "VCLEFT_a307_handleDisconnectedR" 13 "VCLEFT_a013_AlertManagerFault" 206 "VCLEFT_a206_epbWrongDirection" 113 "VCLEFT_a113_UI_MIA" 283 "VCLEFT_a283_latchUnexpectedArmR" 228 "VCLEFT_a228_seatEncOverTrack" 15 "VCLEFT_a015_NVMMAlert" 133 "VCLEFT_a133_blowerLowRPMCBang" 153 "VCLEFT_a153_windowUncalRear" 269 "VCLEFT_a269_seatTiltHCEncStlDbg" 275 "VCLEFT_a275_leftTurnLightFault" 10 "VCLEFT_a010_ExtSupplyVoltError" 99 "VCLEFT_a099_PARK_MIA" 231 "VCLEFT_a231_seatEncOverLift" 139 "VCLEFT_a139_BLERearPowerCycled" 264 "VCLEFT_a264_seatBackStallDebug" 253 "VCLEFT_a253_seatUncalTilt" 101 "VCLEFT_a101_PM_MIA" 59 "VCLEFT_a059_inputResistanceHigh" 219 "VCLEFT_a219_motorCurrentDropout" 120 "VCLEFT_a120_DI_DRIVE_MIA" 160 "VCLEFT_a160_windowUndercurrentF" 220 "VCLEFT_a220_seatCurrStallTrack" 203 "VCLEFT_a203_epbmOverIStatic" 310 "VCLEFT_a310_mirrorFoldStall" 222 "VCLEFT_a222_seatCurrStallTilt" 243 "VCLEFT_a243_seatHeatShortRearL" 197 "VCLEFT_a197_VEHCANUndertrminate" 158 "VCLEFT_a158_windowPinchOverideF" 129 "VCLEFT_a129_blowerICLatchFault" 230 "VCLEFT_a230_seatEncOverTilt" 236 "VCLEFT_a236_lumbarOverPresA" 116 "VCLEFT_a116_VCRIGHT_MIA" 205 "VCLEFT_a205_epbmOverIDyn" 260 "VCLEFT_a260_latchDisarmDelayR" 221 "VCLEFT_a221_seatCurrStallBack" 209 "VCLEFT_a209_epbStateMisTime" 104 "VCLEFT_a104_DAS_MIA" 161 "VCLEFT_a161_windowUndercurrentR" 301 "VCLEFT_a301_swcOverVoltage" 232 "VCLEFT_a232_seatCurrUnderTrack" 183 "VCLEFT_a183_doorStateFactoryTest" 151 "VCLEFT_a151_windowPinchRear" 132 "VCLEFT_a132_blowerSoftStall" 159 "VCLEFT_a159_windowPinchOverideR" 60 "VCLEFT_a060_engineeringBuild" 137 "VCLEFT_a137_VCSECPowerCycled" 170 "VCLEFT_a170_windowCurrentPeakR" 290 "VCLEFT_a290_occupancyFaultedFront" 210 "VCLEFT_a210_epbStateTime" 152 "VCLEFT_a152_windowUncalFront" 242 "VCLEFT_a242_seatHeatIRearL" 240 "VCLEFT_a240_seatHeatShortFront" 30 "VCLEFT_a030_ECULogUploadRequest" 102 "VCLEFT_a102_PTC_MIA" 235 "VCLEFT_a235_seatCurrUnderLift" 300 "VCLEFT_a300_swcUnderVoltage" 204 "VCLEFT_a204_epbmUnderIDyn" 323 "VCLEFT_a323_windowPwrDeriv2RDBG" 111 "VCLEFT_a111_EPBR_MIA" 45 "VCLEFT_a045_Task100msError" 112 "VCLEFT_a112_EPBL_MIA" 276 "VCLEFT_a276_mirrorDebug" 190 "VCLEFT_a190_eFuseMgmtVbatFused" 117 "VCLEFT_a117_VCLEFT_MIA" 42 "VCLEFT_a042_HighStackUsage" 225 "VCLEFT_a225_seatEncStallBack" 2 "VCLEFT_a002_PowerLossReset" 182 "VCLEFT_a182_emergencyLatchRel" 41 "VCLEFT_a041_HighCPULoad" 103 "VCLEFT_a103_CP_MIA" 61 "VCLEFT_a061_XCPConnected" 239 "VCLEFT_a239_seatHeatIFront" 285 "VCLEFT_a285_blowerChipComms" 278 "VCLEFT_a278_BLERearUnderVoltage" 306 "VCLEFT_a306_handleDisconnectedF" 156 "VCLEFT_a156_windowNoInputFront" 131 "VCLEFT_a131_blowerICTransFault" 105 "VCLEFT_a105_TAS_MIA" 265 "VCLEFT_a265_seatTiltStallDebug" 270 "VCLEFT_a270_seatLiftHCEncStlDbg" 286 "VCLEFT_a286_windowSpeedInvalidF" 272 "VCLEFT_a272_vhclPwrStateMsmtch" 303 "VCLEFT_a303_eFuseMgmtWindowLift" 241 "VCLEFT_a241_seatHeatMIAFront" 212 "VCLEFT_a212_epbmOverIStaticNew" 143 "VCLEFT_a143_mirrorManuallyFolded" 217 "VCLEFT_a217_SPI_MIA_debugData2" 207 "VCLEFT_a207_epbmEnableWrong" 164 "VCLEFT_a164_windowFactoryTest" 292 "VCLEFT_a292_occupancyFaultedRearL" 211 "VCLEFT_a211_epbmUnderIStaticNew" 227 "VCLEFT_a227_seatEncStallLift" 43 "VCLEFT_a043_Task1msError" 141 "VCLEFT_a141_12VAuxPowerTrip" 234 "VCLEFT_a234_seatCurrUnderTilt" 63 "VCLEFT_a063_SwitchFault" 201 "VCLEFT_a201_motorDutyEncDisabl" 214 "VCLEFT_a214_epbmOverIDynNew" 162 "VCLEFT_a162_windowEncoderStallF" 3 "VCLEFT_a003_SWAssertion" 191 "VCLEFT_a191_TLCOvercurrent" 308 "VCLEFT_a308_sirenMIA" 254 "VCLEFT_a254_seatUncalLift" 216 "VCLEFT_a216_SPI_MIA_debugData1" 98 "VCLEFT_a098_DI_THERMAL_MIA" 280 "VCLEFT_a280_latchDidNotDisarmF" 155 "VCLEFT_a155_windowThermalRear" 44 "VCLEFT_a044_Task10msError" 97 "VCLEFT_a097_CMP_MIA" 169 "VCLEFT_a169_windowCurrentPeakF" 229 "VCLEFT_a229_seatEncOverBack" 259 "VCLEFT_a259_latchDisarmDelayF" 251 "VCLEFT_a251_seatUncalTrack" 115 "VCLEFT_a115_VCSEC_MIA" 223 "VCLEFT_a223_seatCurrStallLift" 22 "VCLEFT_a022_TaskInitError" 281 "VCLEFT_a281_latchDidNotDisarmR" 167 "VCLEFT_a167_windowDebugPinchF" 282 "VCLEFT_a282_latchUnexpectedArmF" 0 "VCLEFT_ALERT_DO_NOT_USE_ZERO" 274 "VCLEFT_a274_handleStuckActiveR" 138 "VCLEFT_a138_consoleDoorAssist" 31 "VCLEFT_a031_UDSActive" 244 "VCLEFT_a244_seatHeatMIARearL" 187 "VCLEFT_a187_latchReleaseFailedR" 64 "VCLEFT_a064_busSleepReqTimeout" 304 "VCLEFT_a304_frontIntHandleShorted" 157 "VCLEFT_a157_windowNoInputRear" 263 "VCLEFT_a263_seatTrackStallDebug" 309 "VCLEFT_a309_brakeSwitchFaulted" 302 "VCLEFT_a302_blowerGeneralFault" 273 "VCLEFT_a273_handleStuckActiveF" 166 "VCLEFT_a166_windowDebug" 172 "VCLEFT_a172_SPI_MIA" 180 "VCLEFT_a180_frontDoorLatchRehome" 213 "VCLEFT_a213_epbmUnderIDynNew" 168 "VCLEFT_a168_windowDebugPinchR" 218 "VCLEFT_a218_motorDriverFault" 233 "VCLEFT_a233_seatCurrUnderBack" 200 "VCLEFT_a200_motorPhantomEncoder" 238 "VCLEFT_a238_lumbarValveMIA" 266 "VCLEFT_a266_seatLiftStallDebug" 186 "VCLEFT_a186_latchReleaseFailedF" 1 "VCLEFT_a001_WatchdogReset" 134 "VCLEFT_a134_SteerColUpDownUnCal" 21 "VCLEFT_a021_TaskSchedulerError" 224 "VCLEFT_a224_seatEncStallTrack" 188 "VCLEFT_a188_latchUnableToRearmF" 291 "VCLEFT_a291_buckleFaultedFront" 154 "VCLEFT_a154_windowThermalFront" 226 "VCLEFT_a226_seatEncStallTilt" 279 "VCLEFT_a279_VCSECUnderVoltage" 109 "VCLEFT_a109_RCM_MIA" 165 "VCLEFT_a165_windowFactoryTest2" 135 "VCLEFT_a135_SteerColInOutUnCal" 208 "VCLEFT_a208_epbFaulted" 110 "VCLEFT_a110_GTW_MIA" 196 "VCLEFT_a196_VEHCANOverterminate" 267 "VCLEFT_a267_seatTrackHCEncStlDbg" 140 "VCLEFT_a140_BLELeftPowerCycled" 324 "VCLEFT_a324_mirrorHeatFault" 118 "VCLEFT_a118_VCFRONT_MIA" ;
VAL_ 812 CC_temperature4 127 "SNA" ;
VAL_ 812 CC_contactor2Closed 3 "CC_CONTACTOR_SNA" 0 "CC_CONTACTOR_OPEN" 1 "CC_CONTACTOR_CLOSED" ;
VAL_ 812 CC_contactor1Closed 3 "CC_CONTACTOR_SNA" 0 "CC_CONTACTOR_OPEN" 1 "CC_CONTACTOR_CLOSED" ;
VAL_ 812 CC_temperature3 127 "SNA" ;
VAL_ 812 CC_temperature2 127 "SNA" ;
VAL_ 812 CC_temperature1 127 "SNA" ;
VAL_ 812 CC_conn3Current 255 "SNA" ;
VAL_ 812 CC_conn4Current 255 "SNA" ;
VAL_ 812 CC_activeConnectorID 255 "SNA" ;
VAL_ 812 CC_conn1Current 255 "SNA" ;
VAL_ 812 CC_conn2Current 255 "SNA" ;
VAL_ 812 CC_logIndex 4 "Mux4" 2 "Mux2" 11 "Mux11" 3 "Mux3" 10 "Mux10" 13 "Mux13" 0 "Mux0" 12 "Mux12" 1 "Mux1" ;
VAL_ 1795 VCRIGHT_setTempAdjustmentRight 127 "SNA" ;
VAL_ 1795 VCRIGHT_setTempAdjustmentLeft 127 "SNA" ;
VAL_ 1795 VCRIGHT_cabinTempProbe 255 "SNA" ;
VAL_ 1795 VCRIGHT_tempEvapAdjustmentRight 127 "SNA" ;
VAL_ 1795 VCRIGHT_cabinTempThsBracket 255 "SNA" ;
VAL_ 1795 VCRIGHT_cabinTempThs 255 "SNA" ;
VAL_ 1795 VCRIGHT_tempEvapAdjustmentLeft 127 "SNA" ;
VAL_ 1795 VCRIGHT_debugThermal10HzIndex 1 "temps" 3 "cabinModel" 4 "actuatorStatus" 5 "END" 2 "airflow" 0 "heaterAndEvapWatts" ;
VAL_ 1344 SCCM_alertState 0 "ALERT_CLEARED" 1 "ALERT_SET" ;
VAL_ 1344 SCCM_alertID 14 "SCCM_a014_voltageLow" 10 "SCCM_a010_turnIndShortToGnd" 4 "SCCM_a004_highBeamShortToGND" 26 "SCCM_a026_parkButtonInvalidSignal" 3 "SCCM_a003_highBeamOpen" 29 "SCCM_a029_parkButtonMalfunction" 24 "SCCM_a024_gearStalkGenErr" 22 "SCCM_a022_gearStalkOpenCircuit" 2 "SCCM_a002_CANTOut" 11 "SCCM_a011_turnIndHWErr" 13 "SCCM_a013_voltageHigh" 7 "SCCM_a007_turnIndComInfo" 9 "SCCM_a009_turnIndOpen" 25 "SCCM_a025_runTimeError" 15 "SCCM_a015_softwareError" 23 "SCCM_a023_gearStalkShortCircuit" 28 "SCCM_a028_parkButtonShortToGround" 8 "SCCM_a008_turnIndInvalidTrans" 12 "SCCM_a012_turnGenErr" 18 "SCCM_a018_angleSpeedOutOfRange" 0 "SCCM_ALERT_DO_NOT_USE_ZERO" 5 "SCCM_a005_tipWipeOpen" 17 "SCCM_a017_memoryError" 6 "SCCM_a006_tipWipeShortToGND" 21 "SCCM_a021_gearStalkSignalInvalid" 20 "SCCM_a020_angleInternalError" 27 "SCCM_a027_parkButtonOpenCircuit" 19 "SCCM_a019_angleSpeedAboveLimit" 16 "SCCM_a016_hardwareError" 1 "SCCM_a001_CANBusOff" ;
VAL_ 917 DIS_oilPumpCurrentSensorOffset 255 "SNA" ;
VAL_ 917 DIS_oilPumpCurrent 255 "SNA" ;
VAL_ 917 DIS_oilPumpVoltage 255 "SNA" ;
VAL_ 917 DIS_oilPumpFluidT 255 "SNA" ;
VAL_ 917 DIS_oilPumpPcbT 255 "SNA" ;
VAL_ 917 DIS_oilPumpFlowActual 255 "SNA" ;
VAL_ 917 DIS_oilPumpFlowTarget 255 "SNA" ;
VAL_ 917 DIS_oilPumpState 2 "OIL_PUMP_COLD_STARTUP" 0 "OIL_PUMP_STANDBY" 1 "OIL_PUMP_ENABLE" 6 "OIL_PUMP_FAULTED" 7 "OIL_PUMP_SNA" ;
VAL_ 297 SCCM_steeringAngleValidity 3 "SNA" 2 "INIT" 0 "INVALID" 1 "VALID" ;
VAL_ 297 SCCM_steeringAngleSensorStatus 0 "OK" 1 "INIT" 2 "ERROR" 3 "ERROR_INIT" ;
VAL_ 644 UI_serviceMode 1 "SERVICE_MODE_ENABLED" 0 "SERVICE_MODE_DISABLED" ;
VAL_ 644 UI_showroomMode 1 "SHOWROOM_MODE_ENABLED" 0 "SHOWROOM_MODE_DISABLED" ;
VAL_ 644 UI_transportMode 1 "TRANSPORT_MODE_ENABLED" 0 "TRANSPORT_MODE_DISABLED" ;
VAL_ 644 UI_factoryMode 0 "FACTORY_MODE_DISABLED" 1 "FACTORY_MODE_ENABLED" ;
VAL_ 754 BMS_nmWakeUpReason 5 "BMS_WAKEUP_REASON_WANTTOWARM" 2 "BMS_WAKEUP_REASON_CAN_HVS" 4 "BMS_WAKEUP_REASON_CRITICALALERT" 3 "BMS_WAKEUP_REASON_WANTTOCHARGE" 1 "BMS_WAKEUP_REASON_CAN_VEH" 0 "BMS_WAKEUP_REASON_NONE" ;
VAL_ 754 BMS_nmKeepAwakeReason 2 "BMS_KEEPAWAKE_REASON_CRITICAL_ALERT" 5 "BMS_KEEPAWAKE_REASON_BMS_ACTIVE" 4 "BMS_KEEPAWAKE_REASON_HVP_ACTIVE" 0 "BMS_KEEPAWAKE_REASON_NONE_SNA" 6 "BMS_KEEPAWAKE_REASON_CP_ACTIVE" 3 "BMS_KEEPAWAKE_REASON_FC_CTR_CLEANING" 1 "BMS_KEEPAWAKE_REASON_CTRS_CLOSED" ;
VAL_ 1112 GTW_nmWakeUpReason 1 "GTW_WAKEUP_REASON_RESET" 8 "GTW_WAKEUP_REASON_UI_SCHEDULED" 6 "GTW_WAKEUP_REASON_VCFRONT" 2 "GTW_WAKEUP_REASON_GSM_RI" 5 "GTW_WAKEUP_REASON_VEH_CAN" 3 "GTW_WAKEUP_REASON_CH_CAN" 4 "GTW_WAKEUP_REASON_ETH_CAN" 0 "GTW_WAKEUP_REASON_NONE" 7 "GTW_WAKEUP_REASON_RTC_ALARM" ;
VAL_ 1112 GTW_nmKeepAwakeReason 0 "GTW_KEEPAWAKE_REASON_NONE_SNA" 15 "GTW_KEEPAWAKE_REASON_TBD" ;
VAL_ 705 VCFRONT_tempDischargeSimulated 2047 "SNA" ;
VAL_ 705 VCFRONT_fiveWayValveDuty 127 "SNA" ;
VAL_ 705 VCFRONT_pumpPowertrainRPMTarget 1023 "SNA" ;
VAL_ 705 VCFRONT_fiveWayValveState 0 "UNPOWERED" 3 "FAULT" 1 "CALIBRATING" 2 "READY" ;
VAL_ 705 VCFRONT_fiveWayValveAngleTarget 1023 "SNA" ;
VAL_ 705 VCFRONT_radiatorFanRPMTarget 1023 "SNA" ;
VAL_ 705 VCFRONT_pumpBatteryRPMTarget 1023 "SNA" ;
VAL_ 705 VCFRONT_fiveWayValveAngleActual 1023 "SNA" ;
VAL_ 705 VCFRONT_coolantTempBasedMode 0 "SERIES" 1 "PARALLEL" ;
VAL_ 705 VCFRONT_exvMotorState 11 "SPI_COMMS_DOWN" 3 "INIT_SPI" 9 "FAULT_OPEN_COIL" 2 "HARD_RESET" 1 "HARD_RESET_SETUP" 5 "ENABLE_MOTOR" 0 "UNPOWERED" 4 "SPI_ERROR" 10 "DRIVER_FAULT" 6 "READY" 7 "STALL" 8 "FAULT_SHORT_COIL" ;
VAL_ 705 VCFRONT_logging10HzIndex 5 "EXV_EVAP_SOLENOID_AIRFLOW" 3 "REFRIGERANT_LV8907" 4 "COMPRESSOR" 2 "FIVE_WAY_VALVE" 6 "END" 1 "THERMAL_FAN" 0 "COOLANT_PUMPS" ;
VAL_ 994 VCLEFT_rearRideHeight -128 "SNA" ;
VAL_ 994 VCLEFT_frontRideHeight -128 "SNA" ;
VAL_ 994 VCLEFT_fogTrailerLightStatus 3 "LIGHT_SNA" 1 "LIGHT_ON" 0 "LIGHT_OFF" 2 "LIGHT_FAULT" ;
VAL_ 994 VCLEFT_tailTrailerLightStatus 3 "LIGHT_SNA" 1 "LIGHT_ON" 0 "LIGHT_OFF" 2 "LIGHT_FAULT" ;
VAL_ 994 VCLEFT_brakeTrailerLightStatus 3 "LIGHT_SNA" 1 "LIGHT_ON" 0 "LIGHT_OFF" 2 "LIGHT_FAULT" ;
VAL_ 994 VCLEFT_rightTrnTrailerLightStatu 3 "LIGHT_SNA" 1 "LIGHT_ON" 0 "LIGHT_OFF" 2 "LIGHT_FAULT" ;
VAL_ 994 VCLEFT_leftTurnTrailerLightStatu 3 "LIGHT_SNA" 1 "LIGHT_ON" 0 "LIGHT_OFF" 2 "LIGHT_FAULT" ;
VAL_ 994 VCLEFT_RRMapLightStatus 3 "LIGHT_SNA" 1 "LIGHT_ON" 0 "LIGHT_OFF" 2 "LIGHT_FAULT" ;
VAL_ 994 VCLEFT_RLMapLightStatus 3 "LIGHT_SNA" 1 "LIGHT_ON" 0 "LIGHT_OFF" 2 "LIGHT_FAULT" ;
VAL_ 994 VCLEFT_FRMapLightStatus 3 "LIGHT_SNA" 1 "LIGHT_ON" 0 "LIGHT_OFF" 2 "LIGHT_FAULT" ;
VAL_ 994 VCLEFT_FLMapLightStatus 3 "LIGHT_SNA" 1 "LIGHT_ON" 0 "LIGHT_OFF" 2 "LIGHT_FAULT" ;
VAL_ 994 VCLEFT_turnSignalStatus 3 "LIGHT_SNA" 1 "LIGHT_ON" 0 "LIGHT_OFF" 2 "LIGHT_FAULT" ;
VAL_ 994 VCLEFT_tailLightStatus 3 "LIGHT_SNA" 1 "LIGHT_ON" 0 "LIGHT_OFF" 2 "LIGHT_FAULT" ;
VAL_ 994 VCLEFT_brakeLightStatus 3 "LIGHT_SNA" 1 "LIGHT_ON" 0 "LIGHT_OFF" 2 "LIGHT_FAULT" ;
VAL_ 1859 VCRIGHT_mirrorRecallStatus 3 "RECALL_INTERRUPTED" 1 "RECALL_IN_PROGRESS" 2 "RECALL_COMPLETE" 0 "RECALL_SNA" ;
VAL_ 1859 VCRIGHT_seatRecallStatus 3 "RECALL_INTERRUPTED" 1 "RECALL_IN_PROGRESS" 2 "RECALL_COMPLETE" 0 "RECALL_SNA" ;
VAL_ 1859 VCRIGHT_systemRecallStatus 3 "RECALL_INTERRUPTED" 1 "RECALL_IN_PROGRESS" 2 "RECALL_COMPLETE" 0 "RECALL_SNA" ;
VAL_ 258 VCLEFT_mirrorHeatState 2 "HEATER_STATE_OFF" 4 "HEATER_STATE_FAULT" 1 "HEATER_STATE_ON" 0 "HEATER_STATE_SNA" 3 "HEATER_STATE_OFF_UNAVAILABLE" ;
VAL_ 258 VCLEFT_mirrorRecallState 5 "MIRROR_RECALL_STATE_RECALLING_STOPPED" 2 "MIRROR_RECALL_STATE_RECALLING_AXIS_2" 0 "MIRROR_RECALL_STATE_INIT" 3 "MIRROR_RECALL_STATE_RECALLING_COMPLETE" 4 "MIRROR_RECALL_STATE_RECALLING_FAILED" 1 "MIRROR_RECALL_STATE_RECALLING_AXIS_1" ;
VAL_ 258 VCLEFT_mirrorFoldState 4 "MIRROR_FOLD_STATE_UNFOLDING" 1 "MIRROR_FOLD_STATE_FOLDED" 3 "MIRROR_FOLD_STATE_FOLDING" 0 "MIRROR_FOLD_STATE_UNKNOWN" 2 "MIRROR_FOLD_STATE_UNFOLDED" ;
VAL_ 258 VCLEFT_mirrorState 3 "MIRROR_STATE_FOLD_UNFOLD" 1 "MIRROR_STATE_TILT_X" 0 "MIRROR_STATE_IDLE" 2 "MIRROR_STATE_TILT_Y" 4 "MIRROR_STATE_RECALL" ;
VAL_ 258 VCLEFT_rearLatchStatus 8 "LATCH_FAULT" 2 "LATCH_CLOSED" 1 "LATCH_OPENED" 3 "LATCH_CLOSING" 7 "LATCH_DEFAULT" 4 "LATCH_OPENING" 5 "LATCH_AJAR" 6 "LATCH_TIMEOUT" 0 "LATCH_SNA" ;
VAL_ 258 VCLEFT_frontLatchStatus 8 "LATCH_FAULT" 2 "LATCH_CLOSED" 1 "LATCH_OPENED" 3 "LATCH_CLOSING" 7 "LATCH_DEFAULT" 4 "LATCH_OPENING" 5 "LATCH_AJAR" 6 "LATCH_TIMEOUT" 0 "LATCH_SNA" ;
VAL_ 787 UI_trackModeRequest 2 "TRACK_MODE_REQUEST_OFF" 1 "TRACK_MODE_REQUEST_ON" 0 "TRACK_MODE_REQUEST_IDLE" ;
VAL_ 787 UI_wasteModeRegenLimit 0 "MAX_REGEN_CURRENT_MAX" 2 "MAX_REGEN_CURRENT_10A" 3 "MAX_REGEN_CURRENT_0A" 1 "MAX_REGEN_CURRENT_30A" ;
VAL_ 787 UI_wasteMode 2 "WASTE_TYPE_FULL" 1 "WASTE_TYPE_PARTIAL" 0 "WASTE_TYPE_NONE" ;
VAL_ 787 UI_motorOnMode 2 "MOTORONMODE_REAR_ONLY" 1 "MOTORONMODE_FRONT_ONLY" 0 "MOTORONMODE_NORMAL" ;
VAL_ 787 UI_creepTorque 1 "CREEP_TORQUE_ON" 0 "CREEP_TORQUE_OFF" ;
VAL_ 787 UI_limitMode 2 "LIMIT_FACTORY" 1 "LIMIT_VALET" 0 "LIMIT_NORMAL" ;
VAL_ 787 UI_speedLimit 255 "SNA" ;
VAL_ 787 UI_systemTorqueLimit 63 "SNA" ;
VAL_ 787 UI_pedalMap 1 "SPORT" 0 "CHILL" ;
VAL_ 787 UI_systemPowerLimit 31 "SNA" ;
